VERSION "HNNBNNNYNNNNNNNNNNNNNNNNNNNNNNNNNNNNNNNNNN/4/%%%/4/'%**4NNN///"

NS_ :

BS_:

BU_: BAP_Tester Booster_AMP DSP_SKODA Gateway_PQ35 Gateway_PQ46 GSM_Pager Kompassmodul MDI Radio_2DIN Radio_Modul Radio_SKODA Rearview RNS_300_NF RNS_MFD2 RNS_midline SDARS_Tuner Sprachbedienung Standheizung Tastatur Telematik_Basis TV_hybrid UHV_High UHV_low UHV_NAR UHV_Premium UHV_UMTS

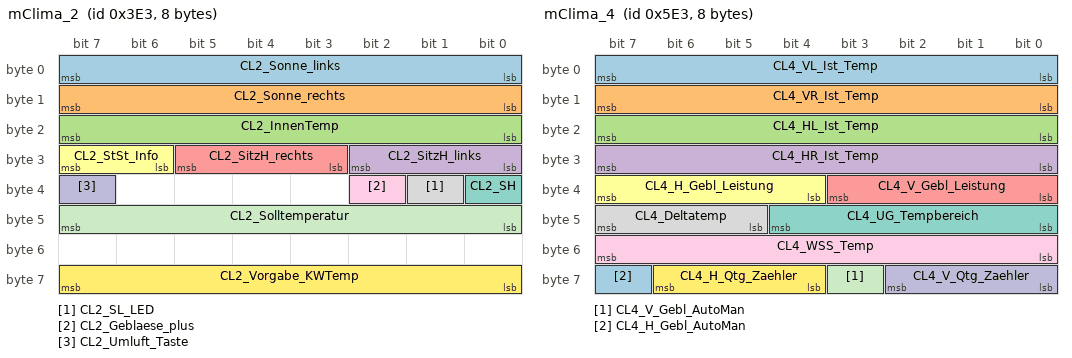
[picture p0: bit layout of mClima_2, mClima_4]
BO_ 995 mClima_2: 8 Gateway_PQ35
 SG_ CL2_Sonne_links : 0|8@1+ (4,0) [0|1016] "Unit_WattPerMeterSquar" Vector__XXX
 SG_ CL2_Sonne_rechts : 8|8@1+ (4,0) [0|1016] "Unit_WattPerMeterSquar" Vector__XXX
 SG_ CL2_InnenTemp : 16|8@1+ (0.5,-50) [-50|77] "Unit_DegreCelsi" Vector__XXX
 SG_ CL2_SitzH_links : 24|3@1+ (1,0) [0|7] "" Vector__XXX
 SG_ CL2_SitzH_rechts : 27|3@1+ (1,0) [0|7] "" Vector__XXX
 SG_ CL2_StSt_Info : 30|2@1+ (1,0) [0|3] "" Vector__XXX
 SG_ CL2_SH : 32|1@1+ (1,0) [0|1] ""  Standheizung,Telematik_Basis
 SG_ CL2_SL_LED : 33|1@1+ (1,0) [0|1] "" Vector__XXX
 SG_ CL2_Geblaese_plus : 34|1@1+ (1,0) [0|1] "" Vector__XXX
 SG_ CL2_Umluft_Taste : 39|1@1+ (1,0) [0|1] "" Vector__XXX
 SG_ CL2_Solltemperatur : 40|8@1+ (1,0) [0|255] "" Vector__XXX
 SG_ CL2_Vorgabe_KWTemp : 56|8@1+ (0.75,-48) [-48|142.5] "Unit_DegreCelsi" Vector__XXX

BO_ 1505 mClima_3: 7 Gateway_PQ35
 SG_ CL3_Umluft : 0|1@1+ (1,0) [0|1] ""  Radio_SKODA
 SG_ CL3_Restwaerme : 1|1@1+ (1,0) [0|1] "" Vector__XXX
 SG_ CL3_Mono : 2|1@1+ (1,0) [0|1] ""  Radio_SKODA
 SG_ CL3_Luftguetesensor : 3|1@1+ (1,0) [0|1] ""  Radio_SKODA
 SG_ CL3_Defrost : 4|1@1+ (1,0) [0|1] ""  Radio_SKODA
 SG_ CL3_Solarbelueftung : 5|1@1+ (1,0) [0|1] ""  Radio_SKODA
 SG_ CL3_Econ : 6|1@1+ (1,0) [0|1] ""  Radio_SKODA
 SG_ CL3_Klima_Hauptschalter : 7|1@1+ (1,0) [0|1] ""  Radio_SKODA
 SG_ CL3_KlimaOffFond : 8|1@1+ (1,0) [0|1] "" Vector__XXX
 SG_ CL3_Bedien_mgl : 9|1@1+ (1,0) [0|1] "" Vector__XXX
 SG_ CL3_nAkt_Uml_Fond : 10|1@1+ (1,0) [0|1] "" Vector__XXX
 SG_ CL3_nAkt_Umluft : 11|1@1+ (1,0) [0|1] "" Vector__XXX
 SG_ CL3_nAkt_Econ : 12|1@1+ (1,0) [0|1] "" Vector__XXX
 SG_ CL3_nAkt_AQS : 13|1@1+ (1,0) [0|1] "" Vector__XXX
 SG_ CL3_nAkt_Restwaerme : 14|1@1+ (1,0) [0|1] "" Vector__XXX
 SG_ CL3_Hzg_LF_Sens : 15|1@1+ (1,0) [0|1] "" Vector__XXX
 SG_ CL3_V_Qtg_Zaehler : 16|3@1+ (1,0) [0|7] "" Vector__XXX
 SG_ CL3_H_Qtg_Zaehler : 20|3@1+ (1,0) [0|7] "" Vector__XXX
 SG_ CL3_StandHzg : 23|1@1+ (1,0) [0|1] ""  Radio_SKODA
 SG_ CL3_Anstr_VL_Kopf : 24|1@1+ (1,0) [0|1] ""  Radio_SKODA
 SG_ CL3_Anstr_VL_Mann : 25|1@1+ (1,0) [0|1] ""  Radio_SKODA
 SG_ CL3_Anstr_VL_Fuss : 26|1@1+ (1,0) [0|1] ""  Radio_SKODA
 SG_ CL3_Anstr_VL_Automatik : 27|1@1+ (1,0) [0|1] ""  Radio_SKODA
 SG_ CL3_Anstr_VR_Kopf : 28|1@1+ (1,0) [0|1] "" Vector__XXX
 SG_ CL3_Anstr_VR_Mann : 29|1@1+ (1,0) [0|1] "" Vector__XXX
 SG_ CL3_Anstr_VR_Fuss : 30|1@1+ (1,0) [0|1] "" Vector__XXX
 SG_ CL3_Anstr_VR_Automatik : 31|1@1+ (1,0) [0|1] "" Vector__XXX
 SG_ CL3_Anstr_HL_Kopf : 32|1@1+ (1,0) [0|1] "" Vector__XXX
 SG_ CL3_Anstr_HL_Mann : 33|1@1+ (1,0) [0|1] "" Vector__XXX
 SG_ CL3_Anstr_HL_Fuss : 34|1@1+ (1,0) [0|1] "" Vector__XXX
 SG_ CL3_Anstr_HL_Automatik : 35|1@1+ (1,0) [0|1] "" Vector__XXX
 SG_ CL3_Anstr_HR_Kopf : 36|1@1+ (1,0) [0|1] "" Vector__XXX
 SG_ CL3_Anstr_HR_Mann : 37|1@1+ (1,0) [0|1] "" Vector__XXX
 SG_ CL3_Anstr_HR_Fuss : 38|1@1+ (1,0) [0|1] "" Vector__XXX
 SG_ CL3_Anstr_HR_Automatik : 39|1@1+ (1,0) [0|1] "" Vector__XXX
 SG_ CL3_FT_Defrost : 40|1@1+ (1,0) [0|1] "" Vector__XXX
 SG_ CL3_BT_Defrost : 41|1@1+ (1,0) [0|1] "" Vector__XXX
 SG_ CL3_StandLftg : 42|1@1+ (1,0) [0|1] "" Vector__XXX
 SG_ CL3_SH_ein_KDWunsch : 43|1@1+ (1,0) [0|1] "" Vector__XXX
 SG_ CL3_SH_Wasserpumpe : 44|1@1+ (1,0) [0|1] ""  Standheizung
 SG_ CL3_ein_Lenkrad_Hzg : 46|1@1+ (1,0) [0|1] "" Vector__XXX
 SG_ CL3_Gegendimmung : 48|8@1+ (1,0) [0|100] "Unit_PerCent" Vector__XXX

BO_ 1507 mClima_4: 8 Gateway_PQ35
 SG_ CL4_VL_Ist_Temp : 0|8@1+ (0.5,-50) [-50|77] "Unit_DegreCelsi"  Radio_SKODA
 SG_ CL4_VR_Ist_Temp : 8|8@1+ (0.5,-50) [-50|77] "Unit_DegreCelsi"  Radio_SKODA
 SG_ CL4_HL_Ist_Temp : 16|8@1+ (0.5,-50) [-50|77] "Unit_DegreCelsi" Vector__XXX
 SG_ CL4_HR_Ist_Temp : 24|8@1+ (0.5,-50) [-50|77] "Unit_DegreCelsi" Vector__XXX
 SG_ CL4_V_Gebl_Leistung : 32|4@1+ (10,0) [0|100] "Unit_PerCent"  Radio_SKODA
 SG_ CL4_H_Gebl_Leistung : 36|4@1+ (10,0) [0|100] "Unit_PerCent" Vector__XXX
 SG_ CL4_UG_Tempbereich : 40|5@1+ (1,0) [0|31] "Unit_DegreCelsi" Vector__XXX
 SG_ CL4_Deltatemp : 45|3@1+ (0.5,4) [4.5|7.5] "Unit_DegreCelsi" Vector__XXX
 SG_ CL4_WSS_Temp : 48|8@1+ (0.5,-50) [-50|77] "Unit_DegreCelsi" Vector__XXX
 SG_ CL4_V_Qtg_Zaehler : 56|3@1+ (1,0) [0|7] "" Vector__XXX
 SG_ CL4_V_Gebl_AutoMan : 59|1@1+ (1,0) [0|1] "" Vector__XXX
 SG_ CL4_H_Qtg_Zaehler : 60|3@1+ (1,0) [0|7] "" Vector__XXX
 SG_ CL4_H_Gebl_AutoMan : 63|1@1+ (1,0) [0|1] "" Vector__XXX

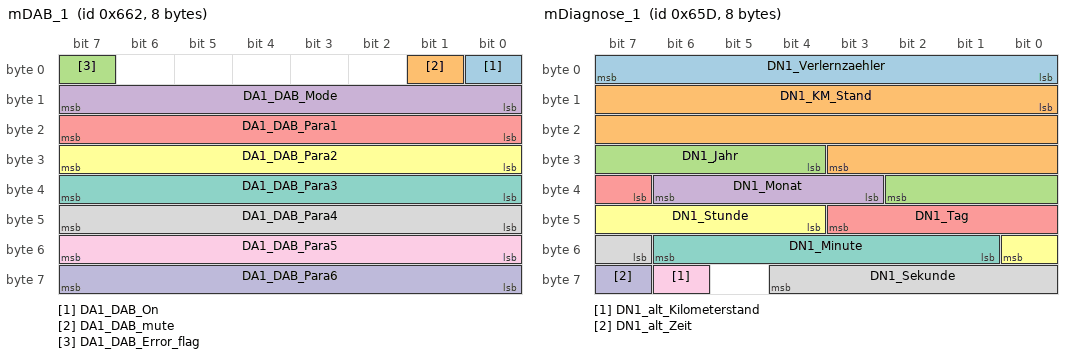
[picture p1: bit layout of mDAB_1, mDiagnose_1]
BO_ 1634 mDAB_1: 8 SDARS_Tuner
 SG_ DA1_DAB_On : 0|1@1+ (1,0) [0|1] ""  Radio_2DIN,Radio_SKODA
 SG_ DA1_DAB_mute : 1|1@1+ (1,0) [0|1] "" Vector__XXX
 SG_ DA1_DAB_Error_flag : 7|1@1+ (1,0) [0|1] ""  Gateway_PQ35,Gateway_PQ46
 SG_ DA1_DAB_Mode : 8|8@1+ (1,0) [0|255] ""  Radio_2DIN,Radio_SKODA
 SG_ DA1_DAB_Para1 : 16|8@1+ (1,0) [0|255] ""  Radio_2DIN,Radio_SKODA
 SG_ DA1_DAB_Para2 : 24|8@1+ (1,0) [0|255] ""  Radio_2DIN,Radio_SKODA
 SG_ DA1_DAB_Para3 : 32|8@1+ (1,0) [0|255] ""  Radio_2DIN,Radio_SKODA
 SG_ DA1_DAB_Para4 : 40|8@1+ (1,0) [0|255] ""  Radio_2DIN,Radio_SKODA
 SG_ DA1_DAB_Para5 : 48|8@1+ (1,0) [0|255] ""  Radio_2DIN,Radio_SKODA
 SG_ DA1_DAB_Para6 : 56|8@1+ (1,0) [0|255] ""  Radio_2DIN,Radio_SKODA

BO_ 1629 mDiagnose_1: 8 Gateway_PQ35
 SG_ DN1_Verlernzaehler : 0|8@1+ (1,0) [0|254] ""  Booster_AMP,DSP_SKODA,GSM_Pager,Kompassmodul,MDI,Radio_2DIN,Radio_Modul,Radio_SKODA,Rearview,RNS_300_NF,RNS_MFD2,RNS_midline,SDARS_Tuner,Sprachbedienung,Standheizung,Tastatur,Telematik_Basis,TV_hybrid,UHV_High,UHV_low,UHV_NAR,UHV_Premium,UHV_UMTS
 SG_ DN1_KM_Stand : 8|20@1+ (1,0) [0|1048575] "Unit_KiloMeter"  Booster_AMP,DSP_SKODA,GSM_Pager,Kompassmodul,MDI,Radio_Modul,Radio_SKODA,Rearview,RNS_300_NF,RNS_midline,SDARS_Tuner,Sprachbedienung,Standheizung,Tastatur,Telematik_Basis,TV_hybrid,UHV_High,UHV_low,UHV_NAR,UHV_Premium,UHV_UMTS
 SG_ DN1_Jahr : 28|7@1+ (1,2000) [2000|2127] "Unit_Year"  Booster_AMP,DSP_SKODA,GSM_Pager,Kompassmodul,MDI,Radio_2DIN,Radio_Modul,Radio_SKODA,Rearview,RNS_300_NF,RNS_midline,SDARS_Tuner,Sprachbedienung,Standheizung,Tastatur,Telematik_Basis,TV_hybrid,UHV_High,UHV_low,UHV_NAR,UHV_Premium,UHV_UMTS
 SG_ DN1_Monat : 35|4@1+ (1,0) [1|12] "Unit_Month"  Booster_AMP,DSP_SKODA,GSM_Pager,Kompassmodul,MDI,Radio_2DIN,Radio_Modul,Radio_SKODA,Rearview,RNS_300_NF,RNS_midline,SDARS_Tuner,Sprachbedienung,Standheizung,Tastatur,Telematik_Basis,TV_hybrid,UHV_High,UHV_low,UHV_NAR,UHV_Premium,UHV_UMTS
 SG_ DN1_Tag : 39|5@1+ (1,0) [0|31] "Unit_Day"  Booster_AMP,DSP_SKODA,GSM_Pager,Kompassmodul,MDI,Radio_2DIN,Radio_Modul,Radio_SKODA,Rearview,RNS_300_NF,RNS_midline,SDARS_Tuner,Sprachbedienung,Standheizung,Tastatur,Telematik_Basis,TV_hybrid,UHV_High,UHV_low,UHV_NAR,UHV_Premium,UHV_UMTS
 SG_ DN1_Stunde : 44|5@1+ (1,0) [0|23] "Unit_Hours"  Booster_AMP,DSP_SKODA,GSM_Pager,Kompassmodul,MDI,Radio_2DIN,Radio_Modul,Radio_SKODA,Rearview,RNS_300_NF,RNS_MFD2,RNS_midline,SDARS_Tuner,Sprachbedienung,Standheizung,Tastatur,Telematik_Basis,TV_hybrid,UHV_High,UHV_low,UHV_NAR,UHV_Premium,UHV_UMTS
 SG_ DN1_Minute : 49|6@1+ (1,0) [0|59] "Unit_Minut"  Booster_AMP,DSP_SKODA,GSM_Pager,Kompassmodul,MDI,Radio_2DIN,Radio_Modul,Radio_SKODA,Rearview,RNS_300_NF,RNS_MFD2,RNS_midline,SDARS_Tuner,Sprachbedienung,Standheizung,Tastatur,Telematik_Basis,TV_hybrid,UHV_High,UHV_low,UHV_NAR,UHV_Premium,UHV_UMTS
 SG_ DN1_Sekunde : 55|6@1+ (1,0) [0|59] "Unit_Secon"  Booster_AMP,DSP_SKODA,GSM_Pager,Kompassmodul,MDI,Radio_2DIN,Radio_Modul,Radio_SKODA,Rearview,RNS_300_NF,RNS_MFD2,RNS_midline,SDARS_Tuner,Sprachbedienung,Standheizung,Tastatur,Telematik_Basis,TV_hybrid,UHV_High,UHV_low,UHV_NAR,UHV_Premium,UHV_UMTS
 SG_ DN1_alt_Kilometerstand : 62|1@1+ (1,0) [0|1] ""  Booster_AMP,DSP_SKODA,GSM_Pager,Kompassmodul,MDI,Radio_Modul,Radio_SKODA,Rearview,RNS_300_NF,RNS_midline,SDARS_Tuner,Sprachbedienung,Standheizung,Tastatur,Telematik_Basis,TV_hybrid,UHV_High,UHV_low,UHV_NAR,UHV_Premium,UHV_UMTS
 SG_ DN1_alt_Zeit : 63|1@1+ (1,0) [0|1] ""  Booster_AMP,DSP_SKODA,GSM_Pager,Kompassmodul,MDI,Radio_2DIN,Radio_Modul,Radio_SKODA,Rearview,RNS_300_NF,RNS_MFD2,RNS_midline,SDARS_Tuner,Sprachbedienung,Standheizung,Tastatur,Telematik_Basis,TV_hybrid,UHV_High,UHV_low,UHV_NAR,UHV_Premium,UHV_UMTS

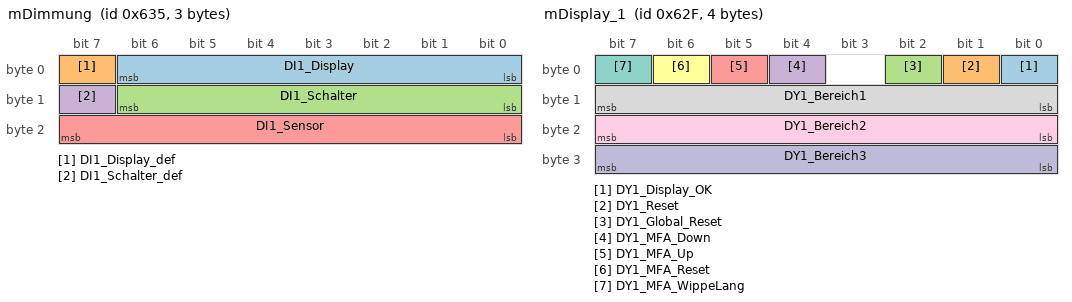
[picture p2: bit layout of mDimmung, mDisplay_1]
BO_ 1589 mDimmung: 3 Gateway_PQ35
 SG_ DI1_Display : 0|7@1+ (1,0) [0|100] "Unit_PerCent"  Radio_2DIN,Radio_Modul,Radio_SKODA,RNS_300_NF,RNS_MFD2,RNS_midline,Sprachbedienung,Tastatur,Telematik_Basis
 SG_ DI1_Display_def : 7|1@1+ (1,0) [0|1] ""  Radio_2DIN,Radio_Modul,Radio_SKODA,RNS_300_NF,RNS_MFD2,RNS_midline,Sprachbedienung,Tastatur,Telematik_Basis
 SG_ DI1_Schalter : 8|7@1+ (1,0) [0|100] "Unit_PerCent" Vector__XXX
 SG_ DI1_Schalter_def : 15|1@1+ (1,0) [0|1] "" Vector__XXX
 SG_ DI1_Sensor : 16|8@1+ (1,0) [0|253] ""  Radio_Modul,RNS_300_NF,RNS_midline

BO_ 1583 mDisplay_1: 4 Gateway_PQ35
 SG_ DY1_Display_OK : 0|1@1+ (1,0) [0|1] ""  Kompassmodul,Radio_2DIN,Radio_Modul,Radio_SKODA,RNS_300_NF,RNS_MFD2,RNS_midline,Standheizung,Telematik_Basis
 SG_ DY1_Reset : 1|1@1+ (1,0) [0|1] ""  Kompassmodul,Radio_2DIN,Radio_Modul,Radio_SKODA,RNS_300_NF,RNS_MFD2,RNS_midline,Standheizung,Telematik_Basis
 SG_ DY1_Global_Reset : 2|1@1+ (1,0) [0|1] ""  Standheizung
 SG_ DY1_MFA_Down : 4|1@1+ (1,0) [0|1] "" Vector__XXX
 SG_ DY1_MFA_Up : 5|1@1+ (1,0) [0|1] "" Vector__XXX
 SG_ DY1_MFA_Reset : 6|1@1+ (1,0) [0|1] "" Vector__XXX
 SG_ DY1_MFA_WippeLang : 7|1@1+ (1,0) [0|1] "" Vector__XXX
 SG_ DY1_Bereich1 : 8|8@1+ (1,0) [0|255] ""  Kompassmodul,Radio_2DIN,Radio_Modul,Radio_SKODA,RNS_300_NF,RNS_midline,Standheizung,Telematik_Basis
 SG_ DY1_Bereich2 : 16|8@1+ (1,0) [0|255] ""  Kompassmodul,Radio_2DIN,Radio_Modul,Radio_SKODA,RNS_300_NF,RNS_midline,Standheizung,Telematik_Basis
 SG_ DY1_Bereich3 : 24|8@1+ (1,0) [0|255] ""  Kompassmodul,Radio_2DIN,Radio_Modul,Radio_SKODA,RNS_300_NF,RNS_midline,Standheizung,Telematik_Basis

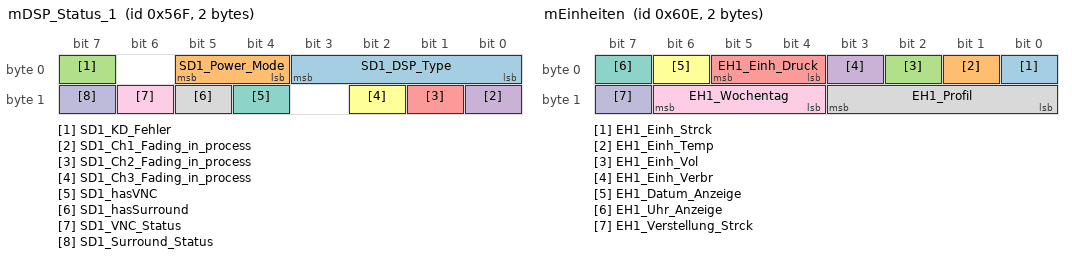
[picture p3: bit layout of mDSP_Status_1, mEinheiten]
BO_ 1391 mDSP_Status_1: 2 Booster_AMP
 SG_ SD1_DSP_Type : 0|4@1+ (1,0) [0|15] ""  Radio_Modul,Radio_SKODA
 SG_ SD1_Power_Mode : 4|2@1+ (1,0) [0|3] ""  Radio_Modul,Radio_SKODA,RNS_300_NF,RNS_midline
 SG_ SD1_KD_Fehler : 7|1@1+ (1,0) [0|1] ""  Gateway_PQ35,Gateway_PQ46
 SG_ SD1_Ch1_Fading_in_process : 8|1@1+ (1,0) [0|1] ""  Radio_SKODA
 SG_ SD1_Ch2_Fading_in_process : 9|1@1+ (1,0) [0|1] ""  Radio_SKODA
 SG_ SD1_Ch3_Fading_in_process : 10|1@1+ (1,0) [0|1] ""  Radio_SKODA
 SG_ SD1_hasVNC : 12|1@1+ (1,0) [0|1] "" Vector__XXX
 SG_ SD1_hasSurround : 13|1@1+ (1,0) [0|1] "" Vector__XXX
 SG_ SD1_VNC_Status : 14|1@1+ (1,0) [0|1] "" Vector__XXX
 SG_ SD1_Surround_Status : 15|1@1+ (1,0) [0|1] "" Vector__XXX

BO_ 1550 mEinheiten: 2 Gateway_PQ35
 SG_ EH1_Einh_Strck : 0|1@1+ (1,0) [0|1] ""  Radio_Modul,RNS_300_NF,RNS_midline
 SG_ EH1_Einh_Temp : 1|1@1+ (1,0) [0|1] ""  Radio_Modul,RNS_300_NF,RNS_midline,Standheizung
 SG_ EH1_Einh_Vol : 2|1@1+ (1,0) [0|1] ""  Radio_Modul,RNS_300_NF,RNS_midline
 SG_ EH1_Einh_Verbr : 3|1@1+ (1,0) [0|1] ""  Radio_Modul,RNS_300_NF,RNS_midline
 SG_ EH1_Einh_Druck : 4|2@1+ (1,0) [0|3] "" Vector__XXX
 SG_ EH1_Datum_Anzeige : 6|1@1+ (1,0) [0|1] ""  Radio_Modul,RNS_300_NF,RNS_midline
 SG_ EH1_Uhr_Anzeige : 7|1@1+ (1,0) [0|1] ""  Radio_2DIN,Radio_Modul,Radio_SKODA,RNS_300_NF,RNS_midline,Standheizung
 SG_ EH1_Profil : 8|4@1+ (1,0) [0|15] ""  Radio_Modul,RNS_300_NF,RNS_midline,Sprachbedienung,Standheizung,Telematik_Basis
 SG_ EH1_Wochentag : 12|3@1+ (1,0) [0|7] "" Vector__XXX
 SG_ EH1_Verstellung_Strck : 15|1@1+ (1,0) [0|1] ""  RNS_300_NF,RNS_midline

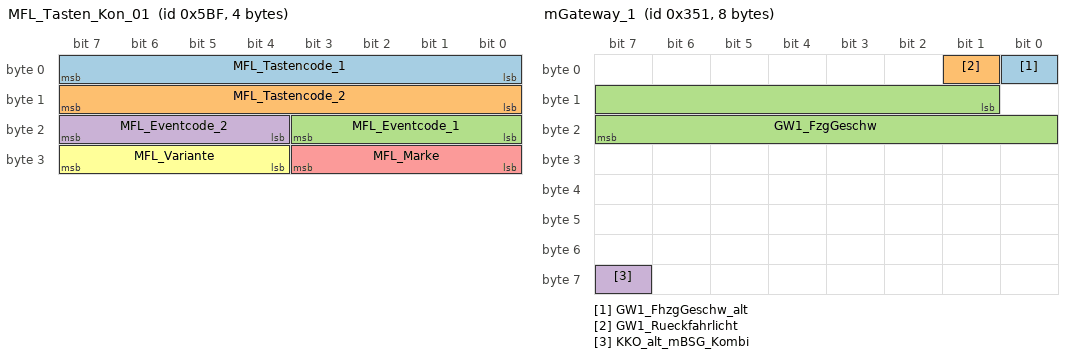
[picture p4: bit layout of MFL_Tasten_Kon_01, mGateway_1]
BO_ 1471 MFL_Tasten_Kon_01: 4 Gateway_PQ46
 SG_ MFL_Tastencode_1 : 0|8@1+ (1,0) [0|255] ""  UHV_NAR,UHV_UMTS
 SG_ MFL_Tastencode_2 : 8|8@1+ (1,0) [0|255] ""  UHV_NAR,UHV_UMTS
 SG_ MFL_Eventcode_1 : 16|4@1+ (1,0) [0|15] ""  UHV_NAR,UHV_UMTS
 SG_ MFL_Eventcode_2 : 20|4@1+ (1,0) [0|15] ""  UHV_NAR,UHV_UMTS
 SG_ MFL_Marke : 24|4@1+ (1,0) [0|15] ""  UHV_NAR,UHV_UMTS
 SG_ MFL_Variante : 28|4@1+ (1,0) [0|15] ""  UHV_NAR,UHV_UMTS

BO_ 1631 mFzg_Ident: 8 Gateway_PQ35
 SG_ FI1_MUX M : 0|2@1+ (1,0) [0|2] ""  RNS_300_NF,Telematik_Basis
 SG_ FI1_Geheimnis_1 m0 : 8|8@1+ (1,0) [0|255] "" Vector__XXX
 SG_ FI1_VIN_4 m1 : 8|8@1+ (1,0) [0|255] ""  RNS_300_NF,Telematik_Basis
 SG_ FI1_VIN_11 m2 : 8|8@1+ (1,0) [0|255] ""  RNS_300_NF,Telematik_Basis
 SG_ FI1_Geheimnis_2 m0 : 16|8@1+ (1,0) [0|255] "" Vector__XXX
 SG_ FI1_VIN_5 m1 : 16|8@1+ (1,0) [0|255] ""  RNS_300_NF,Telematik_Basis
 SG_ FI1_VIN_12 m2 : 16|8@1+ (1,0) [0|255] ""  RNS_300_NF,Telematik_Basis
 SG_ FI1_Geheimnis_3 m0 : 24|8@1+ (1,0) [0|255] "" Vector__XXX
 SG_ FI1_VIN_6 m1 : 24|8@1+ (1,0) [0|255] ""  RNS_300_NF,Telematik_Basis
 SG_ FI1_VIN_13 m2 : 24|8@1+ (1,0) [0|255] ""  RNS_300_NF,Telematik_Basis
 SG_ FI1_Geheimnis_4 m0 : 32|8@1+ (1,0) [0|255] "" Vector__XXX
 SG_ FI1_VIN_7 m1 : 32|8@1+ (1,0) [0|255] ""  RNS_300_NF,Telematik_Basis
 SG_ FI1_VIN_14 m2 : 32|8@1+ (1,0) [0|255] ""  RNS_300_NF,Telematik_Basis
 SG_ FI1_VIN_1 m0 : 40|8@1+ (1,0) [0|255] ""  RNS_300_NF,Telematik_Basis
 SG_ FI1_VIN_8 m1 : 40|8@1+ (1,0) [0|255] ""  RNS_300_NF,Telematik_Basis
 SG_ FI1_VIN_15 m2 : 40|8@1+ (1,0) [0|255] ""  RNS_300_NF,Telematik_Basis
 SG_ FI1_VIN_2 m0 : 48|8@1+ (1,0) [0|255] ""  RNS_300_NF,Telematik_Basis
 SG_ FI1_VIN_9 m1 : 48|8@1+ (1,0) [0|255] ""  RNS_300_NF,Telematik_Basis
 SG_ FI1_VIN_16 m2 : 48|8@1+ (1,0) [0|255] ""  RNS_300_NF,Telematik_Basis
 SG_ FI1_VIN_3 m0 : 56|8@1+ (1,0) [0|255] ""  RNS_300_NF,Telematik_Basis
 SG_ FI1_VIN_10 m1 : 56|8@1+ (1,0) [0|255] ""  RNS_300_NF,Telematik_Basis
 SG_ FI1_VIN_17 m2 : 56|8@1+ (1,0) [0|255] ""  RNS_300_NF,Telematik_Basis

BO_ 849 mGateway_1: 8 Gateway_PQ35
 SG_ GW1_FhzgGeschw_alt : 0|1@1+ (1,0) [0|1] "" Vector__XXX
 SG_ GW1_Rueckfahrlicht : 1|1@1+ (1,0) [0|1] "" Vector__XXX
 SG_ GW1_FzgGeschw : 9|15@1+ (0.01,0) [0|326.39] "Unit_KiloMeterPerHour" Vector__XXX
 SG_ KKO_alt_mBSG_Kombi : 63|1@1+ (1,0) [0|1] "" Vector__XXX

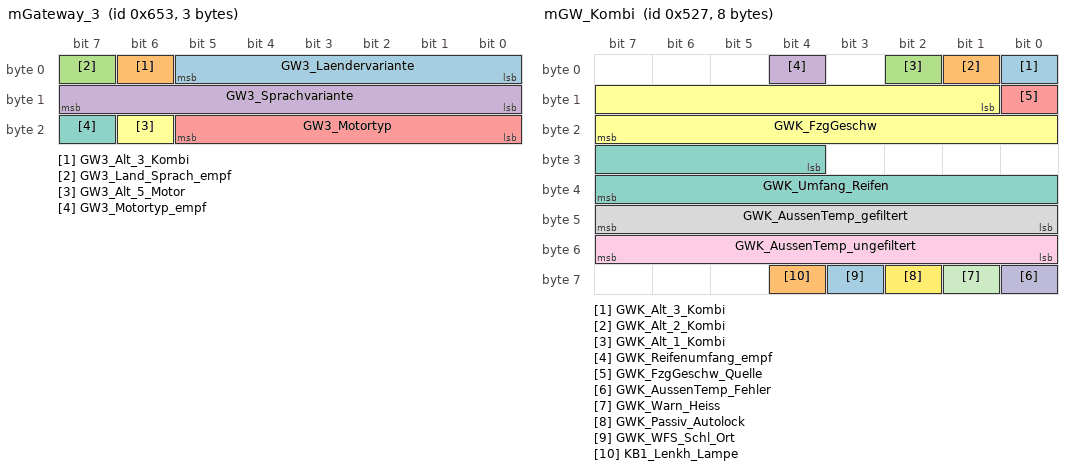
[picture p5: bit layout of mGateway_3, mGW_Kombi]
BO_ 1619 mGateway_3: 3 Gateway_PQ35
 SG_ GW3_Laendervariante : 0|6@1+ (1,0) [0|63] ""  Kompassmodul,Radio_Modul,Rearview,RNS_300_NF,RNS_MFD2,RNS_midline,Standheizung,Telematik_Basis,UHV_High,UHV_low,UHV_NAR,UHV_Premium,UHV_UMTS
 SG_ GW3_Alt_3_Kombi : 6|1@1+ (1,0) [0|1] ""  Rearview,UHV_High,UHV_low,UHV_NAR,UHV_Premium,UHV_UMTS
 SG_ GW3_Land_Sprach_empf : 7|1@1+ (1,0) [0|1] ""  Radio_Modul,RNS_300_NF,RNS_MFD2,RNS_midline,Telematik_Basis,UHV_High,UHV_low,UHV_NAR,UHV_Premium,UHV_UMTS
 SG_ GW3_Sprachvariante : 8|8@1+ (1,0) [0|255] ""  Kompassmodul,Radio_Modul,Rearview,RNS_300_NF,RNS_MFD2,RNS_midline,Standheizung,Telematik_Basis,UHV_High,UHV_low,UHV_NAR,UHV_Premium,UHV_UMTS
 SG_ GW3_Motortyp : 16|6@1+ (1,0) [0|63] ""  Standheizung
 SG_ GW3_Alt_5_Motor : 22|1@1+ (1,0) [0|1] ""  Standheizung
 SG_ GW3_Motortyp_empf : 23|1@1+ (1,0) [0|1] "" Vector__XXX

BO_ 1487 mGSM_Pager_1: 1 GSM_Pager
 SG_ GS1_Error_flag : 7|1@1+ (1,0) [0|1] ""  Gateway_PQ35,Gateway_PQ46

BO_ 857 mGW_Bremse_Getriebe: 8 Gateway_PQ35
 SG_ GWB_Alt_FzgGeschw : 0|1@1+ (1,0) [0|1] ""  Booster_AMP,DSP_SKODA,Kompassmodul,Radio_2DIN,Radio_Modul,Radio_SKODA,Rearview,RNS_300_NF,RNS_MFD2,RNS_midline,Standheizung,Telematik_Basis,UHV_low,UHV_Premium
 SG_ GWB_Alt_2_Bremse : 1|1@1+ (1,0) [0|1] ""  Radio_Modul,RNS_300_NF,RNS_MFD2,RNS_midline,Telematik_Basis
 SG_ GWB_Alt_1_Bremse : 2|1@1+ (1,0) [0|1] "" Vector__XXX
 SG_ GWB_Alt_1_Getriebe : 3|1@1+ (1,0) [0|1] "" Vector__XXX
 SG_ GWB_Alt_2_Getriebe : 4|1@1+ (1,0) [0|1] "" Vector__XXX
 SG_ GWB_Alt_1_EPB : 5|1@1+ (1,0) [0|1] "" Vector__XXX
 SG_ GWB_Alt_5_Bremse : 6|1@1+ (1,0) [0|1] "" Vector__XXX
 SG_ GWB_Alt_AWV_X : 7|1@1+ (1,0) [0|1] "" Vector__XXX
 SG_ GWB_FzgGeschw_Quelle : 8|1@1+ (1,0) [0|1] ""  Booster_AMP,DSP_SKODA,Kompassmodul,Radio_2DIN,Radio_Modul,Radio_SKODA,Rearview,RNS_300_NF,RNS_MFD2,RNS_midline,Standheizung,Telematik_Basis,UHV_low,UHV_Premium
 SG_ GWB_FzgGeschw : 9|15@1+ (0.01,0) [0|326.39] "Unit_KiloMeterPerHour"  Booster_AMP,DSP_SKODA,Kompassmodul,Radio_2DIN,Radio_Modul,Radio_SKODA,Rearview,RNS_300_NF,RNS_MFD2,RNS_midline,Standheizung,Telematik_Basis,UHV_low,UHV_Premium
 SG_ GWB_Wegimpulse : 24|11@1+ (1,0) [0|2047] ""  Radio_Modul,RNS_300_NF,RNS_MFD2,RNS_midline,Telematik_Basis
 SG_ GWB_Wegimpuls_Status : 35|1@1+ (1,0) [0|1] ""  Radio_Modul,RNS_300_NF,RNS_MFD2,RNS_midline,Telematik_Basis
 SG_ GWB_Wegimpulse_Fehler : 39|1@1+ (1,0) [0|1] ""  Radio_Modul,RNS_300_NF,RNS_MFD2,RNS_midline,Telematik_Basis
 SG_ GWB_Impulszahl : 40|6@1+ (1,0) [0|63] ""  Radio_Modul,RNS_300_NF,RNS_MFD2,RNS_midline,Telematik_Basis
 SG_ GWB_Alt_PLA_Status : 46|1@1+ (1,0) [0|1] "" Vector__XXX
 SG_ PLS_Bremsleuchte : 47|1@1+ (1,0) [0|1] "" Vector__XXX
 SG_ GWB_TSP_aktiv : 48|1@1+ (1,0) [0|1] "" Vector__XXX
 SG_ GWB_Notbremsung : 49|1@1+ (1,0) [0|1] "" Vector__XXX
 SG_ GWB_ABS_Bremsung : 50|1@1+ (1,0) [0|1] "" Vector__XXX
 SG_ GWB_EPB_Status : 51|1@1+ (1,0) [0|1] "" Vector__XXX
 SG_ GWB_EPB_Bremslicht : 52|1@1+ (1,0) [0|1] "" Vector__XXX
 SG_ GWB_Schlechtweg : 53|1@1+ (1,0) [0|1] "" Vector__XXX
 SG_ GWB_Schlechtweg_Fehler : 54|1@1+ (1,0) [0|1] "" Vector__XXX
 SG_ GWB_Geschw_Ersatz : 55|1@1+ (1,0) [0|1] ""  Booster_AMP,DSP_SKODA,Kompassmodul,Radio_2DIN,Radio_Modul,Radio_SKODA,RNS_300_NF,RNS_MFD2,RNS_midline,Telematik_Basis
 SG_ GWB_Schaltvorgang : 56|1@1+ (1,0) [0|1] "" Vector__XXX
 SG_ ANB_Teilbremsung_Freigabe : 57|1@1+ (1,0) [0|1] "" Vector__XXX
 SG_ GWB_ESP_Eingriff : 58|1@1+ (1,0) [0|1] "" Vector__XXX
 SG_ GWB_Shift_Lock : 59|1@1+ (1,0) [0|1] "" Vector__XXX
 SG_ GWB_Info_Waehlhebel : 60|4@1+ (1,0) [0|15] "" Vector__XXX

BO_ 1315 mGW_KOM_INF: 8 Gateway_PQ35
 SG_ GWI_alt_ZKE_4 : 0|1@1+ (1,0) [0|1] ""  GSM_Pager,Radio_Modul
 SG_ GWI_alt_ZKE_3 : 1|1@1+ (1,0) [0|1] ""  GSM_Pager
 SG_ GWI_alt_Kombi_1 : 2|1@1+ (1,0) [0|1] "" Vector__XXX
 SG_ GWI_res3 : 3|1@1+ (1,0) [0|1] "" Vector__XXX
 SG_ GWI_res4 : 4|1@1+ (1,0) [0|1] "" Vector__XXX
 SG_ GWI_res5 : 5|1@1+ (1,0) [0|1] "" Vector__XXX
 SG_ GWI_res6 : 6|1@1+ (1,0) [0|1] "" Vector__XXX
 SG_ GWI_res7 : 7|1@1+ (1,0) [0|1] "" Vector__XXX
 SG_ GWI_Status_Verdeck : 8|1@1+ (1,0) [0|1] ""  Radio_Modul
 SG_ GWI_ZKE4_Zusatzfkt : 15|1@1+ (1,0) [0|1] ""  GSM_Pager
 SG_ GWI_Blk_ZV_auf : 16|1@1+ (1,0) [0|1] ""  GSM_Pager
 SG_ GWI_Blk_ZV_zu : 17|1@1+ (1,0) [0|1] ""  GSM_Pager
 SG_ GWI_Blk_DW_ein : 18|1@1+ (1,0) [0|1] ""  GSM_Pager
 SG_ GWI_DWA_Alarm : 19|1@1+ (1,0) [0|1] ""  GSM_Pager
 SG_ GWI_verriegelt_int : 20|1@1+ (1,0) [0|1] ""  GSM_Pager
 SG_ GWI_verriegelt_ext : 21|1@1+ (1,0) [0|1] ""  GSM_Pager
 SG_ GWI_gesaeft_ext : 22|1@1+ (1,0) [0|1] ""  GSM_Pager
 SG_ KB1_angez_kmh : 32|10@1+ (0.32,0) [0|325.76] "Unit_KiloMeterPerHour" Vector__XXX

BO_ 1319 mGW_Kombi: 8 Gateway_PQ35
 SG_ GWK_Alt_3_Kombi : 0|1@1+ (1,0) [0|1] ""  Radio_Modul,RNS_300_NF,RNS_MFD2,RNS_midline
 SG_ GWK_Alt_2_Kombi : 1|1@1+ (1,0) [0|1] ""  Radio_Modul,Standheizung,Telematik_Basis
 SG_ GWK_Alt_1_Kombi : 2|1@1+ (1,0) [0|1] ""  DSP_SKODA,Kompassmodul,Radio_2DIN,Radio_Modul,Radio_SKODA,RNS_300_NF,RNS_midline,Standheizung,Telematik_Basis,UHV_low,UHV_NAR,UHV_Premium,UHV_UMTS
 SG_ GWK_Reifenumfang_empf : 4|1@1+ (1,0) [0|1] ""  RNS_300_NF,RNS_MFD2,RNS_midline
 SG_ GWK_FzgGeschw_Quelle : 8|1@1+ (1,0) [0|1] ""  DSP_SKODA,Kompassmodul,Radio_2DIN,Radio_Modul,Radio_SKODA,RNS_300_NF,RNS_midline,Standheizung,Telematik_Basis,UHV_low,UHV_NAR,UHV_Premium,UHV_UMTS
 SG_ GWK_FzgGeschw : 9|15@1+ (0.01,0) [0|326] "Unit_KiloMeterPerHour"  DSP_SKODA,Kompassmodul,Radio_2DIN,Radio_Modul,Radio_SKODA,RNS_300_NF,RNS_midline,Standheizung,Telematik_Basis,UHV_low,UHV_NAR,UHV_Premium,UHV_UMTS
 SG_ GWK_Umfang_Reifen : 28|12@1+ (1,0) [0|4095] ""  RNS_300_NF,RNS_MFD2,RNS_midline
 SG_ GWK_AussenTemp_gefiltert : 40|8@1+ (0.5,-50) [-50|77] "Unit_DegreCelsi"  Radio_Modul,Standheizung,Telematik_Basis
 SG_ GWK_AussenTemp_ungefiltert : 48|8@1+ (0.5,-50) [-50|77] "Unit_DegreCelsi"  Standheizung,Telematik_Basis
 SG_ GWK_AussenTemp_Fehler : 56|1@1+ (1,0) [0|1] ""  Standheizung,Telematik_Basis
 SG_ GWK_Warn_Heiss : 57|1@1+ (1,0) [0|1] "" Vector__XXX
 SG_ GWK_Passiv_Autolock : 58|1@1+ (1,0) [0|1] "" Vector__XXX
 SG_ GWK_WFS_Schl_Ort : 59|1@1+ (1,0) [0|1] "" Vector__XXX
 SG_ KB1_Lenkh_Lampe : 60|1@1+ (1,0) [0|1] "" Vector__XXX

BO_ 859 mGW_Motor: 8 Gateway_PQ35
 SG_ GWM_Alt_1_Motor : 0|1@1+ (1,0) [0|1] ""  Booster_AMP,DSP_SKODA,Radio_2DIN,Radio_Modul,Radio_SKODA,RNS_300_NF,RNS_midline,Standheizung,Telematik_Basis
 SG_ GWM_Alt_2_Motor : 1|1@1+ (1,0) [0|1] ""  Standheizung
 SG_ GWM_Alt_5_Motor : 2|1@1+ (1,0) [0|1] "" Vector__XXX
 SG_ GWM_Alt_Motor_Bremse : 3|1@1+ (1,0) [0|1] "" Vector__XXX
 SG_ GWM_RME_Gehalt : 5|3@1+ (12.5,0) [0|75] "Unit_PerCent"  Standheizung
 SG_ GWM_Motordrehzahl : 8|16@1+ (0.25,0) [0|16256] "Unit_MinutInver"  Booster_AMP,DSP_SKODA,Radio_2DIN,Radio_Modul,Radio_SKODA,RNS_300_NF,RNS_midline,Standheizung,Telematik_Basis
 SG_ GWM_KuehlmittelTemp : 24|8@1+ (0.75,-48) [-47.25|142.5] "Unit_DegreCelsi"  Standheizung
 SG_ GWM_Bremslicht_Schalter : 32|1@1+ (1,0) [0|1] "" Vector__XXX
 SG_ GWM_Bremstest_Schalter : 33|1@1+ (1,0) [0|1] "" Vector__XXX
 SG_ GWM_Fehl_KmittelTemp : 34|1@1+ (1,0) [0|1] "" Vector__XXX
 SG_ GWM_Kuppl_Schalter : 35|1@1+ (1,0) [0|1] "" Vector__XXX
 SG_ GWM_Heissl_Vorwarn : 36|1@1+ (1,0) [0|1] "" Vector__XXX
 SG_ GWM_Klimaabschaltung : 37|1@1+ (1,0) [0|1] "" Vector__XXX
 SG_ GWM_Kennfeldkuehlung : 38|1@1+ (1,0) [0|1] "" Vector__XXX
 SG_ GWM_Komp_Leist_red : 39|1@1+ (1,0) [0|1] "" Vector__XXX
 SG_ GWM_KLuefter : 40|8@1+ (0.4,0) [0|101.6] "Unit_PerCent" Vector__XXX
 SG_ GWM_Anl_Freigabe : 48|1@1+ (1,0) [0|1] "" Vector__XXX
 SG_ GWM_Anl_Ausspuren : 49|1@1+ (1,0) [0|1] "" Vector__XXX
 SG_ GWM_Interlock : 50|1@1+ (1,0) [0|1] "" Vector__XXX
 SG_ GWM_TypStartSteu : 51|1@1+ (1,0) [0|1] "" Vector__XXX
 SG_ GWM_Freig_Bremsanforderung : 52|1@1+ (1,0) [0|1] "" Vector__XXX
 SG_ GWM_Vorgluehen : 53|1@1+ (1,0) [0|1] "" Vector__XXX
 SG_ GWM_GRA_Status : 54|2@1+ (1,0) [0|3] "" Vector__XXX
 SG_ GWM_KVerbrauch : 56|7@1+ (256,0) [0|32512] "Unit_MicroLiter" Vector__XXX
 SG_ GWM_Ueberl_KV : 63|1@1+ (1,0) [0|1] "" Vector__XXX

BO_ 1367 mKD_Error: 8 Gateway_PQ35
 SG_ EKD_Motor_A : 0|1@1+ (1,0) [0|1] ""  Telematik_Basis
 SG_ EKD_Getriebe_A : 1|1@1+ (1,0) [0|1] ""  Telematik_Basis
 SG_ EKD_Bremse_A : 2|1@1+ (1,0) [0|1] ""  Telematik_Basis
 SG_ EKD_Kombi_A : 3|1@1+ (1,0) [0|1] ""  Telematik_Basis
 SG_ EKD_LSM_A : 4|1@1+ (1,0) [0|1] ""  Telematik_Basis
 SG_ EKD_Airbag_A : 5|1@1+ (1,0) [0|1] ""  Telematik_Basis
 SG_ EKD_Lenkhilfe_A : 6|1@1+ (1,0) [0|1] ""  Telematik_Basis
 SG_ EKD_dyn_LWR_A : 7|1@1+ (1,0) [0|1] ""  Telematik_Basis
 SG_ EKD_Niveau_A : 8|1@1+ (1,0) [0|1] ""  Telematik_Basis
 SG_ EKD_Allrad_A : 9|1@1+ (1,0) [0|1] ""  Telematik_Basis
 SG_ EKD_ADR_Sensor_A : 10|1@1+ (1,0) [0|1] ""  Telematik_Basis
 SG_ EKD_ADR_getrennt : 11|1@1+ (1,0) [0|1] ""  Telematik_Basis
 SG_ EKD_Parkbremse_A : 12|1@1+ (1,0) [0|1] ""  Telematik_Basis
 SG_ EKD_EZS_A : 13|1@1+ (1,0) [0|1] ""  Telematik_Basis
 SG_ EKD_Daempfer_A : 14|1@1+ (1,0) [0|1] ""  Telematik_Basis
 SG_ EKD_Quersperre : 15|1@1+ (1,0) [0|1] "" Vector__XXX
 SG_ EKD_Motor_Slave_A : 16|1@1+ (1,0) [0|1] "" Vector__XXX
 SG_ EKD_SWA_A : 17|1@1+ (1,0) [0|1] "" Vector__XXX
 SG_ EKD_LDW_A : 18|1@1+ (1,0) [0|1] "" Vector__XXX
 SG_ EKD_RKA_Plus_A : 19|1@1+ (1,0) [0|1] "" Vector__XXX
 SG_ EKD_PLA_A : 20|1@1+ (1,0) [0|1] ""  Telematik_Basis
 SG_ EKD_WFS_KBI : 21|1@1+ (1,0) [0|1] ""  Telematik_Basis
 SG_ EKD_Kombi_KBI : 22|1@1+ (1,0) [0|1] ""  Telematik_Basis
 SG_ EKD_BSG_K : 24|1@1+ (1,0) [0|1] ""  Telematik_Basis
 SG_ EKD_KSG_K : 25|1@1+ (1,0) [0|1] ""  Telematik_Basis
 SG_ EKD_TSG_FT_K : 26|1@1+ (1,0) [0|1] ""  Telematik_Basis
 SG_ EKD_TSG_BT_K : 27|1@1+ (1,0) [0|1] ""  Telematik_Basis
 SG_ EKD_TSG_HL_K : 28|1@1+ (1,0) [0|1] ""  Telematik_Basis
 SG_ EKD_TSG_HR_K : 29|1@1+ (1,0) [0|1] ""  Telematik_Basis
 SG_ EKD_Memory_K : 30|1@1+ (1,0) [0|1] ""  Telematik_Basis
 SG_ EKD_Dachmodul_K : 31|1@1+ (1,0) [0|1] ""  Telematik_Basis
 SG_ EKD_Zentralelektrik_II_K : 32|1@1+ (1,0) [0|1] ""  Telematik_Basis
 SG_ EKD_RDK_K : 33|1@1+ (1,0) [0|1] ""  Telematik_Basis
 SG_ EKD_SMLS_K : 34|1@1+ (1,0) [0|1] ""  Telematik_Basis
 SG_ EKD_Gateway_K : 35|1@1+ (1,0) [0|1] ""  Telematik_Basis
 SG_ EKD_Clima_K : 36|1@1+ (1,0) [0|1] ""  Telematik_Basis
 SG_ EKD_APS_K : 37|1@1+ (1,0) [0|1] ""  Telematik_Basis
 SG_ EKD_PTC_Heizung_K : 38|1@1+ (1,0) [0|1] ""  Telematik_Basis
 SG_ EKD_Standhzg_K : 39|1@1+ (1,0) [0|1] ""  Telematik_Basis
 SG_ EKD_VSG_K : 40|1@1+ (1,0) [0|1] ""  Telematik_Basis
 SG_ EKD_RSE_I : 41|1@1+ (1,0) [0|1] ""  Telematik_Basis
 SG_ EKD_Wischer_K : 42|1@1+ (1,0) [0|1] ""  Telematik_Basis
 SG_ EKD_MDI_I : 43|1@1+ (1,0) [0|1] ""  Telematik_Basis
 SG_ EKD_AAG_K : 44|1@1+ (1,0) [0|1] ""  Telematik_Basis
 SG_ EKD_Mem_BF_K : 45|1@1+ (1,0) [0|1] ""  Telematik_Basis
 SG_ EKD_Easy_Entry_VF : 46|1@1+ (1,0) [0|1] ""  Telematik_Basis
 SG_ EKD_Easy_Entry_VB : 47|1@1+ (1,0) [0|1] "" Vector__XXX
 SG_ EKD_Heckdeckel_K : 48|1@1+ (1,0) [0|1] ""  Telematik_Basis
 SG_ EKD_Rearview_I : 49|1@1+ (1,0) [0|1] "" Vector__XXX
 SG_ EKD_Sonderfahrzeug_SG_K : 50|1@1+ (1,0) [0|1] ""  Telematik_Basis
 SG_ EKD_Tastenmodul_I : 51|1@1+ (1,0) [0|1] ""  Telematik_Basis
 SG_ EKD_Kompass_I : 52|1@1+ (1,0) [0|1] ""  Telematik_Basis
 SG_ EKD_WFS_K : 53|1@1+ (1,0) [0|1] ""  Telematik_Basis
 SG_ EKD_GSM_Pager_I : 54|1@1+ (1,0) [0|1] ""  Telematik_Basis
 SG_ EKD_DSP_I : 56|1@1+ (1,0) [0|1] ""  Telematik_Basis
 SG_ EKD_DAB_I : 57|1@1+ (1,0) [0|1] ""  Telematik_Basis
 SG_ EKD_Telematik_I : 58|1@1+ (1,0) [0|1] ""  Telematik_Basis
 SG_ EKD_Navigation_I : 59|1@1+ (1,0) [0|1] ""  Telematik_Basis
 SG_ EKD_TV_Tuner_I : 60|1@1+ (1,0) [0|1] ""  Telematik_Basis
 SG_ EKD_Neigungsmodul : 61|1@1+ (1,0) [0|1] ""  Telematik_Basis
 SG_ EKD_Radio_I : 62|1@1+ (1,0) [0|1] ""  Telematik_Basis
 SG_ EKD_Telefon_I : 63|1@1+ (1,0) [0|1] ""  Telematik_Basis

BO_ 1569 mKombi_K1: 7 Gateway_PQ35
 SG_ KO1_Tankstop : 0|1@1+ (1,0) [0|1] ""  RNS_midline,Standheizung,UHV_High
 SG_ KO1_Tankwarnlampe : 1|1@1+ (1,0) [0|1] ""  RNS_midline,Standheizung
 SG_ KO1_WaschWasser : 2|1@1+ (1,0) [0|1] "" Vector__XXX
 SG_ KO1_MH_Kontakt : 3|1@1+ (1,0) [0|1] "" Vector__XXX
 SG_ KO1_FT_geoeffnet : 4|1@1+ (1,0) [0|1] "" Vector__XXX
 SG_ KO1_Handbremse : 5|1@1+ (1,0) [0|1] "" Vector__XXX
 SG_ KO1_AFL : 6|1@1+ (1,0) [0|1] "" Vector__XXX
 SG_ KO1_Klemme_L : 7|1@1+ (1,0) [0|1] "" Vector__XXX
 SG_ KO1_Standzeit : 8|15@1+ (4,0) [0|131068] "Unit_Secon"  Radio_2DIN,Radio_Modul,Radio_SKODA,RNS_MFD2,RNS_midline
 SG_ KO1_Standzeit_Fehler : 23|1@1+ (1,0) [0|1] ""  Radio_2DIN,Radio_Modul,Radio_SKODA,RNS_MFD2,RNS_midline
 SG_ KO1_Tankinhalt : 24|7@1+ (1,0) [0|126] "Unit_Liter"  Standheizung
 SG_ KO1_Tankwarnung : 31|1@1+ (1,0) [0|1] ""  RNS_midline
 SG_ KO1_WFS_Schluessel : 32|4@1+ (1,0) [0|15] "" Vector__XXX
 SG_ KO1_KD_Fehler_WFS : 36|1@1+ (1,0) [0|1] "" Vector__XXX
 SG_ KO1_Fernlicht : 37|1@1+ (1,0) [0|1] "" Vector__XXX
 SG_ KO1_Freigabe_Zuheizer : 38|1@1+ (1,0) [0|1] "" Vector__XXX
 SG_ KO1_MFA_vorhanden : 39|1@1+ (1,0) [0|1] "" Vector__XXX
 SG_ KO1_Bel_Displ : 40|7@1+ (1,0) [0|100] "Unit_PerCent" Vector__XXX
 SG_ KO1_Sta_Displ : 47|1@1+ (1,0) [0|1] "" Vector__XXX
 SG_ KO1_Lichtsensor : 48|8@1+ (1,0) [0|253] "" Vector__XXX

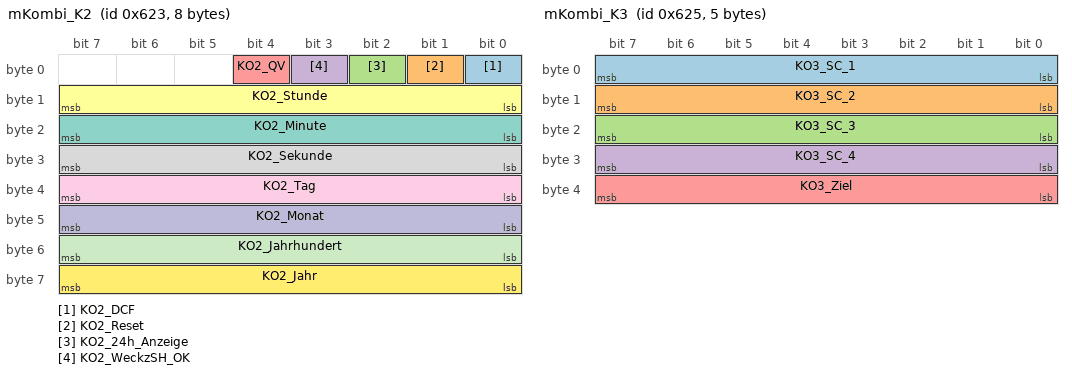
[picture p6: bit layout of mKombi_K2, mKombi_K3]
BO_ 1571 mKombi_K2: 8 Gateway_PQ35
 SG_ KO2_DCF : 0|1@1+ (1,0) [0|1] "" Vector__XXX
 SG_ KO2_Reset : 1|1@1+ (1,0) [0|1] "" Vector__XXX
 SG_ KO2_24h_Anzeige : 2|1@1+ (1,0) [0|1] "" Vector__XXX
 SG_ KO2_WeckzSH_OK : 3|1@1+ (1,0) [0|1] "" Vector__XXX
 SG_ KO2_QV : 4|1@1+ (1,0) [0|1] "" Vector__XXX
 SG_ KO2_Stunde : 8|8@1+ (1,0) [0|255] "" Vector__XXX
 SG_ KO2_Minute : 16|8@1+ (1,0) [0|255] "" Vector__XXX
 SG_ KO2_Sekunde : 24|8@1+ (1,0) [0|255] "" Vector__XXX
 SG_ KO2_Tag : 32|8@1+ (1,0) [0|255] "" Vector__XXX
 SG_ KO2_Monat : 40|8@1+ (1,0) [0|255] "" Vector__XXX
 SG_ KO2_Jahrhundert : 48|8@1+ (1,0) [0|255] "" Vector__XXX
 SG_ KO2_Jahr : 56|8@1+ (1,0) [0|255] "" Vector__XXX

BO_ 1573 mKombi_K3: 5 Gateway_PQ35
 SG_ KO3_SC_1 : 0|8@1+ (1,0) [0|255] ""  Radio_2DIN,Radio_Modul,Radio_SKODA,RNS_300_NF,RNS_MFD2,RNS_midline
 SG_ KO3_SC_2 : 8|8@1+ (1,0) [0|255] ""  Radio_2DIN,Radio_Modul,Radio_SKODA,RNS_300_NF,RNS_MFD2,RNS_midline
 SG_ KO3_SC_3 : 16|8@1+ (1,0) [0|255] ""  Radio_2DIN,Radio_Modul,Radio_SKODA,RNS_300_NF,RNS_MFD2,RNS_midline
 SG_ KO3_SC_4 : 24|8@1+ (1,0) [0|255] ""  Radio_2DIN,Radio_Modul,Radio_SKODA,RNS_300_NF,RNS_MFD2,RNS_midline
 SG_ KO3_Ziel : 32|8@1+ (1,0) [0|255] ""  Radio_2DIN,Radio_Modul,Radio_SKODA,RNS_300_NF,RNS_MFD2,RNS_midline

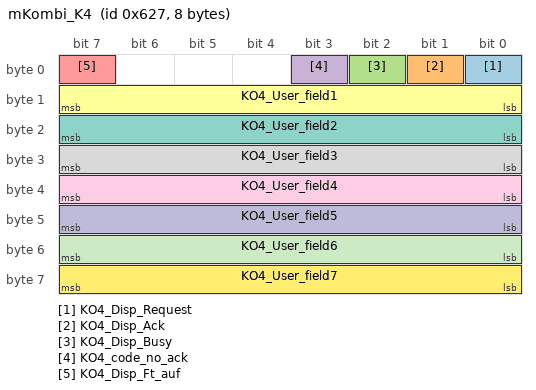
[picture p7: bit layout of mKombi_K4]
BO_ 1575 mKombi_K4: 8 Gateway_PQ35
 SG_ KO4_Disp_Request : 0|1@1+ (1,0) [0|1] "" Vector__XXX
 SG_ KO4_Disp_Ack : 1|1@1+ (1,0) [0|1] "" Vector__XXX
 SG_ KO4_Disp_Busy : 2|1@1+ (1,0) [0|1] "" Vector__XXX
 SG_ KO4_code_no_ack : 3|1@1+ (1,0) [0|1] "" Vector__XXX
 SG_ KO4_Disp_Ft_auf : 7|1@1+ (1,0) [0|1] "" Vector__XXX
 SG_ KO4_User_field1 : 8|8@1+ (1,0) [0|255] "" Vector__XXX
 SG_ KO4_User_field2 : 16|8@1+ (1,0) [0|255] "" Vector__XXX
 SG_ KO4_User_field3 : 24|8@1+ (1,0) [0|255] "" Vector__XXX
 SG_ KO4_User_field4 : 32|8@1+ (1,0) [0|255] "" Vector__XXX
 SG_ KO4_User_field5 : 40|8@1+ (1,0) [0|255] "" Vector__XXX
 SG_ KO4_User_field6 : 48|8@1+ (1,0) [0|255] "" Vector__XXX
 SG_ KO4_User_field7 : 56|8@1+ (1,0) [0|255] "" Vector__XXX

BO_ 1479 mKompass: 4 Kompassmodul
 SG_ KOM_Norden : 0|1@1+ (1,0) [0|1] "" Vector__XXX
 SG_ KOM_NordOst : 1|1@1+ (1,0) [0|1] "" Vector__XXX
 SG_ KOM_Ost : 2|1@1+ (1,0) [0|1] "" Vector__XXX
 SG_ KOM_SuedOst : 3|1@1+ (1,0) [0|1] "" Vector__XXX
 SG_ KOM_Sued : 4|1@1+ (1,0) [0|1] "" Vector__XXX
 SG_ KOM_SuedWest : 5|1@1+ (1,0) [0|1] "" Vector__XXX
 SG_ KOM_West : 6|1@1+ (1,0) [0|1] "" Vector__XXX
 SG_ KOM_NordWest : 7|1@1+ (1,0) [0|1] "" Vector__XXX
 SG_ KOM_Zone : 8|4@1+ (1,0) [0|15] "" Vector__XXX
 SG_ KOM_Calibriert : 12|1@1+ (1,0) [0|1] "" Vector__XXX
 SG_ KOM_CALaktiv : 13|1@1+ (1,0) [0|1] "" Vector__XXX
 SG_ KOM_Grad : 16|8@1+ (1,0) [0|255] "" Vector__XXX
 SG_ KOM_Stoerfeld : 24|1@1+ (1,0) [0|1] "" Vector__XXX
 SG_ KOM_ASIC_Fehler : 25|1@1+ (1,0) [0|1] "" Vector__XXX
 SG_ KOM_Fehler3 : 26|1@1+ (1,0) [0|1] "" Vector__XXX
 SG_ KOM_Fehler4 : 27|1@1+ (1,0) [0|1] "" Vector__XXX
 SG_ KOM_Fehler5 : 28|1@1+ (1,0) [0|1] "" Vector__XXX
 SG_ KOM_Fehler6 : 29|1@1+ (1,0) [0|1] "" Vector__XXX
 SG_ KOM_Fehler7 : 30|1@1+ (1,0) [0|1] "" Vector__XXX
 SG_ KOM_KD_Fehler : 31|1@1+ (1,0) [0|1] ""  Gateway_PQ35,Gateway_PQ46

BO_TX_BU_ 995 : Gateway_PQ35,Gateway_PQ46;
BO_TX_BU_ 1505 : Gateway_PQ35,Gateway_PQ46;
BO_TX_BU_ 1507 : Gateway_PQ35,Gateway_PQ46;
BO_TX_BU_ 1629 : Gateway_PQ35,Gateway_PQ46;
BO_TX_BU_ 1589 : Gateway_PQ35,Gateway_PQ46;
BO_TX_BU_ 1583 : Gateway_PQ35,Gateway_PQ46;
BO_TX_BU_ 1391 : Booster_AMP,DSP_SKODA;
BO_TX_BU_ 1550 : Gateway_PQ35,Gateway_PQ46;
BO_TX_BU_ 1471 : Gateway_PQ35,Gateway_PQ46;
BO_TX_BU_ 1631 : Gateway_PQ35,Gateway_PQ46;
BO_TX_BU_ 849 : Gateway_PQ35,Gateway_PQ46;
BO_TX_BU_ 1619 : Gateway_PQ35,Gateway_PQ46;
BO_TX_BU_ 857 : Gateway_PQ35,Gateway_PQ46;
BO_TX_BU_ 1315 : Gateway_PQ35,Gateway_PQ46;
BO_TX_BU_ 1319 : Gateway_PQ35,Gateway_PQ46;
BO_TX_BU_ 859 : Gateway_PQ35,Gateway_PQ46;
BO_TX_BU_ 1367 : Gateway_PQ35,Gateway_PQ46;
BO_TX_BU_ 1569 : Gateway_PQ35,Gateway_PQ46;
BO_TX_BU_ 1571 : Gateway_PQ35,Gateway_PQ46;
BO_TX_BU_ 1573 : Gateway_PQ35,Gateway_PQ46;
BO_TX_BU_ 1575 : Gateway_PQ35,Gateway_PQ46;
CM_ SG_ 995 CL2_Sonne_links "FF = Fehler
Sonnensensor links";
CM_ SG_ 995 CL2_Sonne_rechts "FF = Fehler
Sonnensensor rechts";
CM_ SG_ 995 CL2_InnenTemp "FF = Fehler
Innenraumtemperatur";
CM_ SG_ 995 CL2_SitzH_links "Status Sitzheizung links
Sitzheizung links Stufe 0...6";
CM_ SG_ 995 CL2_SitzH_rechts "Status Sitzheizung rechts
Sitzheizung rechts Stufe 0...6";
CM_ SG_ 995 CL2_StSt_Info "Stopp-Freigabe/Start-Anforderung für den Start-Stopp-Koordinator";
CM_ SG_ 995 CL2_SH "1 = Standheizung ein, 0 = Standheizung aus";
CM_ SG_ 995 CL2_SL_LED "1 = Kontrolllampe SL_LED ein
Kontrollampe Standlueftung";
CM_ SG_ 995 CL2_Geblaese_plus "1 = Geblaeseleistung Standheizung erhoehen oder Standheizung/ Lueftung ein erhalten
Geblaese plus, Standheizung - Lueftung ein erhalten";
CM_ SG_ 995 CL2_Umluft_Taste "1 = Taste gedrueckt, 0 = Taste nicht gedrueckt
Umluft Taste gedrueckt";
CM_ SG_ 995 CL2_Solltemperatur "Solltemperatur fuer RNSE
Wertebeschreibung:
0 = Klima OFF
1..4 = keine Anzeige
5 = Low
6..9 = keine Anzeige
10..34 = 16,0°C - 28,0°C; Schrittweite 0,5°C
35..109 = keine Anzeige
110..134 = 60°F - 84°F; Schrittweite 1,0°F
135..199 = keine Anzeige
";
CM_ SG_ 995 CL2_Vorgabe_KWTemp "FF = Fehler
Vorgabe der Kuehlwassertemperatur";
CM_ SG_ 1505 CL3_Umluft "1 = ein
Status Umluftbetrieb";
CM_ SG_ 1505 CL3_Restwaerme "1= ein
Restwaermebetrieb";
CM_ SG_ 1505 CL3_Mono "1 = Clima Status MONO aktiviert";
CM_ SG_ 1505 CL3_Luftguetesensor "1 = ein Umluftautomatik
Status Luftguetesensor AQS";
CM_ SG_ 1505 CL3_Defrost "1 = ein
Status Defrost";
CM_ SG_ 1505 CL3_Solarbelueftung "1 = Solarbelueftungsmodus ist eingeschaltet (Klappen sind geoeffnet)
Im D1GP2 wird diese Info vom RNS auf dem I-CAN empfangen.
Status Solarbelueftung";
CM_ SG_ 1505 CL3_Econ "1 = ein
Status ECON-Betrieb";
CM_ SG_ 1505 CL3_Klima_Hauptschalter "1 = Klimaanlage ist ausgeschaltet
Status Klimaanlage OFF";
CM_ SG_ 1505 CL3_KlimaOffFond "1 - Klimaanlage Fond ist ausgeschaltet (Rückmeldung für Anzeige)
Status Klimaanlage Fond";
CM_ SG_ 1505 CL3_Bedien_mgl "1= Mitteilung, daß eine Bedienung ueber externe Bedieneinheit moeglich ist (z.B. nach Wake-up oder Reset)";
CM_ SG_ 1505 CL3_nAkt_Uml_Fond "1 = nicht aktivierbar
Umluft von BT Fond nicht aktivierbar";
CM_ SG_ 1505 CL3_nAkt_Umluft "1 = nicht aktivierbar
Umluft von BT Vorne nicht aktivierbar";
CM_ SG_ 1505 CL3_nAkt_Econ "1 = nicht aktivierbar
Econ nicht aktivierbar";
CM_ SG_ 1505 CL3_nAkt_AQS "1 = nicht aktivierbar
Luftguetesensor (AQS) nicht aktivierbar";
CM_ SG_ 1505 CL3_nAkt_Restwaerme "1 = nicht aktivierbar
Restwaermebetrieb nicht aktivierbar";
CM_ SG_ 1505 CL3_Hzg_LF_Sens "1 = Bfehl Heizung einschalten, 0 = Heizung ausschalten
Heizung des Luftfeuchtesensors";
CM_ SG_ 1505 CL3_V_Qtg_Zaehler "Der Zaehlerstand aus mBedClima_1 wird hier uebernommen
Quittungszaehler fuer Einstellungen vorn";
CM_ SG_ 1505 CL3_H_Qtg_Zaehler "Der Zaehlerstand aus mBedClima_1, also mBedClima_3 wird hier uebernommen
Quittungszaehler fuer Einstellungen hinten";
CM_ SG_ 1505 CL3_StandHzg "Befehl z. aus-/einschalten der Standheizung";
CM_ SG_ 1505 CL3_Anstr_VL_Kopf "1 = auf
Status Anstroemer vorne links Kopf (auf/zu)";
CM_ SG_ 1505 CL3_Anstr_VL_Mann "1 = auf
Status Anstroemer vorne links Mann (auf/zu)";
CM_ SG_ 1505 CL3_Anstr_VL_Fuss "1 = auf
Status Anstroemer vorne links Fuss (auf/zu)";
CM_ SG_ 1505 CL3_Anstr_VL_Automatik "1 = auf
Status Anstroemer vorne links Auto (ein/aus)";
CM_ SG_ 1505 CL3_Anstr_VR_Kopf "1 = auf
Status Anstroemer vorne rechts Kopf (auf/zu)";
CM_ SG_ 1505 CL3_Anstr_VR_Mann "1 = auf
Status Anstroemer vorne rechts Mann (auf/zu)";
CM_ SG_ 1505 CL3_Anstr_VR_Fuss "1 = auf
Status Anstroemer vorne rechts Fuss (auf/zu)";
CM_ SG_ 1505 CL3_Anstr_VR_Automatik "1 = auf
Status Anstroemer vorne rechts Auto (ein/aus)";
CM_ SG_ 1505 CL3_Anstr_HL_Kopf "1 = auf
Status Anstroemer hinten links Kopf (auf/zu)";
CM_ SG_ 1505 CL3_Anstr_HL_Mann "1 = auf
Status Anstroemer hinten links Mann (auf/zu)";
CM_ SG_ 1505 CL3_Anstr_HL_Fuss "1 = auf
Status Anstroemer hinten links Fuss (auf/zu)";
CM_ SG_ 1505 CL3_Anstr_HL_Automatik "1 = auf
Status Anstroemer hinten links Auto (ein/aus)";
CM_ SG_ 1505 CL3_Anstr_HR_Kopf "1 = auf
Status Anstroemer hinten rechts Kopf (auf/zu)";
CM_ SG_ 1505 CL3_Anstr_HR_Mann "1 = auf
Status Anstroemer hinten rechts Mann (auf/zu)";
CM_ SG_ 1505 CL3_Anstr_HR_Fuss "1 = auf
Status Anstroemer hinten rechts Fuss (auf/zu)";
CM_ SG_ 1505 CL3_Anstr_HR_Automatik "1 = auf
Status Anstroemer hinten rechts Auto (ein/aus)";
CM_ SG_ 1505 CL3_FT_Defrost "1 = auf
Status Defrostausstroemer Fahrertuer";
CM_ SG_ 1505 CL3_BT_Defrost "1 = auf
Status Defrostausstroemer Beifahrertuer";
CM_ SG_ 1505 CL3_StandLftg "1=aktiv, 0=deaktiv
Standlueftungsmodus";
CM_ SG_ 1505 CL3_SH_ein_KDWunsch "1 = Kundenwunsch Standheizung einschalten";
CM_ SG_ 1505 CL3_SH_Wasserpumpe "Anforderung zur Ansteuerung der SH- Wasserpunmpe im Restwaermebetrieb; 1 = Wasserpumpe ein; 0 = aus";
CM_ SG_ 1505 CL3_ein_Lenkrad_Hzg "1 = Lenkradheizung einschalten; 0 = Lenkradheizung aus. Dieses Biot wird in Abhaengigkeit der Innentemperatur nur von der Climatronic gesetzt";
CM_ SG_ 1505 CL3_Gegendimmung "Gegenlichtdimmung Display";
CM_ SG_ 1507 CL4_VL_Ist_Temp "Zur Anzeige im Infotainment, FF = Fehler
Eingestellte Temperatur vorne links";
CM_ SG_ 1507 CL4_VR_Ist_Temp "An der Klimaanlage eingestellter Wert, kein gemessener Wert
Eingestellte Temperatur vorne rechts";
CM_ SG_ 1507 CL4_HL_Ist_Temp "An der Klimaanlage eingestellter Wert, kein gemessener Wert
Eingestellte Temperatur hinten links";
CM_ SG_ 1507 CL4_HR_Ist_Temp "An der Klimaanlage eingestellter Wert, kein gemessener Wert
Eingestellte Temperatur hinten rechts";
CM_ SG_ 1507 CL4_V_Gebl_Leistung "Eingestellte Geblaeseleistung vorn";
CM_ SG_ 1507 CL4_H_Gebl_Leistung "Eingestellte Geblaeseleistung hinten";
CM_ SG_ 1507 CL4_UG_Tempbereich "fuer Prioritaetsschaltungen ZAB vorn/hinten
Untergrenze des gueltigen Temperaturbereiches";
CM_ SG_ 1507 CL4_Deltatemp "0 = Begrenzung nicht verwendet
maximaler Temperaturgradient";
CM_ SG_ 1507 CL4_WSS_Temp "Temperatur an der Windschutzscheibe fuer interne Berechnungen des Regensensors";
CM_ SG_ 1507 CL4_V_Qtg_Zaehler "Bestaetigung des Zaehlerstandes fuer einen aus der Bedienbotschaft erhaltenen Befehl
Quittungszaehler fuer Einstellungen vorn";
CM_ SG_ 1507 CL4_V_Gebl_AutoMan "Modus Geblaese vorne: 0 = Automatik, 1 = Manuell";
CM_ SG_ 1507 CL4_H_Qtg_Zaehler "Bestaetigung des Zaehlerstandes fuer einen aus der Bedienbotschaft erhaltenen Befehl
Quittungszaehler f. Einst. hinten";
CM_ SG_ 1507 CL4_H_Gebl_AutoMan "Modus Geblaese hinten: 0 = Automatik, 1 = Manuell";
CM_ SG_ 1634 DA1_DAB_On "Festlegung von Statuscodes und Parametern erfolgt in separater Tabelle.
DAB-Tuner Einschaltzustand";
CM_ SG_ 1634 DA1_DAB_mute "Mute On/Off";
CM_ SG_ 1634 DA1_DAB_Error_flag "Fehlereintrag vorhanden";
CM_ SG_ 1634 DA1_DAB_Mode "siehe Spezifikation Mode-Codierung
Mode-Information";
CM_ SG_ 1634 DA1_DAB_Para1 "Parameter des jew. Modes";
CM_ SG_ 1634 DA1_DAB_Para2 "Parameter des jew. Modes";
CM_ SG_ 1634 DA1_DAB_Para3 "Parameter des jew. Modes";
CM_ SG_ 1634 DA1_DAB_Para4 "Parameter des jew. Modes";
CM_ SG_ 1634 DA1_DAB_Para5 "Parameter des jew. Modes";
CM_ SG_ 1634 DA1_DAB_Para6 "Parameter des jew. Modes";
CM_ BO_ 1629 "CAN-Dashboard CAN-Komfort CAN-Infotainment";
CM_ SG_ 1629 DN1_Verlernzaehler "FFh = Fehler, ungueltiger Zaehlerstand bzw. kein gueltiger Fahrzyklus
Binaer wrap around";
CM_ SG_ 1629 DN1_KM_Stand "Kilometerstand";
CM_ SG_ 1629 DN1_Jahr "0 für Datum unbekannt (z.B. keine Funkuhr)
(bei relativem Datum ist auch der Wert 0 gültig siehe Spezifikation_Tageszähler_Kombi_01.doc)";
CM_ SG_ 1629 DN1_Monat "0 = Monat unbekannt
Dh = ungueltig
Eh = relatives Datum siehe Spezifikation_Tageszähler_Kombi_01.doc
Fh = Keine Funkuhrinformation vorhanden und 12 h Anzeige (Monat, Tag, Jahr fehlen)";
CM_ SG_ 1629 DN1_Tag "0 für Datum unbekannt (z.B. keine Funkuhr)
(bei relativem Datum ist auch der Wert 0 gültig siehe Spezifikation_Tageszähler_Kombi_01.doc)";
CM_ SG_ 1629 DN1_Stunde "18h - 1Fh ungueltig";
CM_ SG_ 1629 DN1_Minute "3Ch - 3Fh ungueltig";
CM_ SG_ 1629 DN1_Sekunde "3Ch - 3Fh ungueltig";
CM_ SG_ 1629 DN1_alt_Kilometerstand "0 = Kilometerstand aktuell (vor < als 2 Sec vom Kombi empfangen)
1 = Kilometerstand veraltet";
CM_ SG_ 1629 DN1_alt_Zeit "0 = Zeit aktuell vom Kombi empfangen (< 2 sec)
1 = Zeit veraltet";
CM_ SG_ 1589 DI1_Display "7F = Fehlerwert, kein Ersatzwert; (100 % entspricht maximaler Beleuchtungsstaerke)
Displaydimmung; Tastverhaeltnis";
CM_ SG_ 1589 DI1_Display_def "1 = Fehler, bzw. nicht verfuegbar
Klemme 58d n.i.O";
CM_ SG_ 1589 DI1_Schalter "7F = Fehlerwert, kein Ersatzwert (Bei VW z.Zt. grundsaetzlich 7Fh)
Schalterdimmung; Tastverhaeltnis";
CM_ SG_ 1589 DI1_Schalter_def "1 = Fehler, bzw. nicht verfuegbar (Bei VW z.Zt. grundsaetzlich 1)
Klemme 58s n.i.O";
CM_ SG_ 1589 DI1_Sensor "Lichtsensorzustand lt. Dimmungsspezifikation";
CM_ SG_ 1583 DY1_Display_OK "1 = Diplay ist bereit um Daten anzuzeigen (z.B. Klemme 15 ist ein)";
CM_ SG_ 1583 DY1_Reset "1 = Anzeige wurde resetet";
CM_ SG_ 1583 DY1_Global_Reset "1 = Zuruecksetzen aller DDP-Teilnehmer in den Init-Zustand bzgl. Personalisierung
Reset aller DDP-Teilnehmer gefordert";
CM_ SG_ 1583 DY1_MFA_Down "1 = Taste gedrueckt
Taste MFA Down betaetigt";
CM_ SG_ 1583 DY1_MFA_Up "1 = Taste gedrueckt
Taste MFA Up betaetigt";
CM_ SG_ 1583 DY1_MFA_Reset "1 = Taste gedrueckt
Taste MFA Reset betaetigt";
CM_ SG_ 1583 DY1_MFA_WippeLang "1 = die Wippe wird gerade laenger als 2 Sekunden gehalten";
CM_ SG_ 1583 DY1_Bereich1 "Belegung des Displaybereiches mit einer Meldung mit der Prioritaet des Wertes.
Die genaue Zuordnung der Bereiche zum Display sind aus den Ergaenzungen zur DDP Spezifikation zu ersehen.
Displaybereich Nr. 1";
CM_ SG_ 1583 DY1_Bereich2 "Belegung des Displaybereiches mit einer Meldung mit der Prioritaet des Wertes.
Die genaue Zuordnung der Bereiche zum Display sind aus den Ergaenzungen zur DDP Spezifikation zu ersehen.
Displaybereich Nr. 2";
CM_ SG_ 1583 DY1_Bereich3 "Belegung des Displaybereiches mit einer Meldung mit der Prioritaet des Wertes.
Die genaue Zuordnung der Bereiche zum Display sind aus den Ergaenzungen zur DDP Spezifikation zu ersehen.
Displaybereich Nr. 3";
CM_ SG_ 1391 SD1_DSP_Type "0 = keine Info verfuegbar
1 = 8 K. Linearverst.
2 = 8 K. Verst m. Klangregelung
3 = 12 K. DSP
DSP Typ Information";
CM_ SG_ 1391 SD1_Power_Mode "Rueckmeldung des Verstaerker Betriebszustandes s. mMenu_DSP_1";
CM_ SG_ 1391 SD1_KD_Fehler "1 = mindestens ein Kundendienstfehler ist im Steuergeraet eingetragen";
CM_ SG_ 1391 SD1_Ch1_Fading_in_process "1 = Angesteuerter Cross-Fading Lauf in Kanal 1 ist zur Zeit aktiv";
CM_ SG_ 1391 SD1_Ch2_Fading_in_process "1 = Angesteuerter Cross-Fading Lauf in Kanal 2 ist zur Zeit aktiv";
CM_ SG_ 1391 SD1_Ch3_Fading_in_process "1 = Angesteuerter Cross-Fading Lauf in Kanal 3 ist zur Zeit aktiv";
CM_ SG_ 1550 EH1_Einh_Strck "0 = km
1 = mls
Einheit Streckenanzeige (km/mls)";
CM_ SG_ 1550 EH1_Einh_Temp "0 = °C
1 = °F
Einheit Temperaturanzeige ( °C / °F )";
CM_ SG_ 1550 EH1_Einh_Vol "0 = liter
1 = gallons
Einheit_Volumen ( liter / gallons)";
CM_ SG_ 1550 EH1_Einh_Verbr "0= Strecke / Volumen
1 = Volumen / Strecke
Einheit Verbrauchsanzeige ( Vol./Strecke ; Strecke/Vol.)";
CM_ SG_ 1550 EH1_Einh_Druck "0 = Druckangabe in bar
1 = Druckangabe in psi
2 = n.n.
3 = Druck in kPa
Einheit Druck (bar/psi/_/kPa)";
CM_ SG_ 1550 EH1_Datum_Anzeige "Anzeigeformat des Datums (Europäisch = 0, amerikanisch = 1)";
CM_ SG_ 1550 EH1_Uhr_Anzeige "0 = 24 Stunden Anzeige
1 = 12 Stunden Anzeige
Anzeige 12 24 Stunden";
CM_ SG_ 1550 EH1_Profil "aktuelle Profilnummer";
CM_ SG_ 1550 EH1_Wochentag "0 =Init, 1=Mo, 2=Di, 3=Mi, 4=Do, 5=Fr, 6=Sa, 7=So
Wochentag";
CM_ SG_ 1550 EH1_Verstellung_Strck "Das Kombi kann mittels Personalisierung die Einheit für die Strecke (km/mls) verstellen.
Verstellung der Einheit Strecke via Personalisierung";
CM_ SG_ 1471 MFL_Tastencode_1 "siehe MFL-Codes
Symbolcode 1";
CM_ SG_ 1471 MFL_Tastencode_2 "siehe MFL-Codes
Symbolcode 2";
CM_ SG_ 1471 MFL_Eventcode_1 "Walze:
0 = kein Tick
1...7 = +1...+7 Ticks
8 = Fehlerwert
9...15 = -7...-1 Ticks

Taste:
0 = no Event
1 = pressed
3 = double-click
4 = long-press 1 [800ms]
5 = long-press 2 [2s]
6 = long-press 3 [3s]

Tickzaehler od. Eventcode Walze 1";
CM_ SG_ 1471 MFL_Eventcode_2 "Walze:
0 = kein Tick
1...7 = +1...+7 Ticks
8 = Fehlerwert
9...15 = -7...-1 Ticks

Taste:
0 = no Event
1 = pressed
3 = double-click
4 = long-press 1 [800ms]
5 = long-press 2 [2s]
6 = long-press 3 [3s]

Tickzaehler od. Eventcode Walze 2";
CM_ SG_ 1471 MFL_Marke "0 = VW
1 = AU
2 = SE
3 = SK
4 = VN
5 = Bugatti
6 = Lamborghini
7 = Bentley
8 = Rolls Royce
14 = Ford
15 = Porsche
Fahrzeughersteller nach Kenntnisstand des Senders";
CM_ SG_ 1471 MFL_Variante "Variante für unterschiedliche Tasten / Tastenbelegungen verschiedener MFL";
CM_ BO_ 1631 "CAN-Komfort";
CM_ SG_ 1631 FI1_MUX "Multiplexbyte zur Berechnung der folgenden Datenbytes
Schaltet die naechsten 7 Byte um.
VW756/VW611: Reihenfolge der Inhalte für schnelle Initialisierung anderer Steuergeräte über Ident-Wert 0 folgendermaßen definiert 0, 1, 0, 2, 0, 1, 0, ...";
CM_ SG_ 1631 FI1_Geheimnis_1 "Multiplex = 0
1. Byte Fahrzeuggeheimnis (nicht PQ35/46)";
CM_ SG_ 1631 FI1_VIN_4 "Multiplex = 1
4. Stelle der Fahrgestellnummer
WFS nicht angelernt: Ausgabe 'X' (0x58) oder '-' (0x2D)";
CM_ SG_ 1631 FI1_VIN_11 "Multiplex = 2
11. Stelle der Fahrgestellnummer
WFS nicht angelernt: Ausgabe 'X' (0x58) oder '-' (0x2D)";
CM_ SG_ 1631 FI1_Geheimnis_2 "Multiplex = 0
2. Byte Fahrzeuggeheimnis (nicht PQ35/46)";
CM_ SG_ 1631 FI1_VIN_5 "Multiplex = 1
5. Stelle der Fahrgestellnummer
WFS nicht angelernt: Ausgabe 'X' (0x58) oder '-' (0x2D)";
CM_ SG_ 1631 FI1_VIN_12 "Multiplex = 2
12. Stelle der Fahrgestellnummer
WFS nicht angelernt: Ausgabe 'X' (0x58) oder '-' (0x2D)";
CM_ SG_ 1631 FI1_Geheimnis_3 "Multiplex = 0
3. Byte Fahrzeuggeheimnis (nicht PQ35/46)";
CM_ SG_ 1631 FI1_VIN_6 "Multiplex = 1
6. Stelle der Fahrgestellnummer
WFS nicht angelernt: Ausgabe 'X' (0x58) oder '-' (0x2D)";
CM_ SG_ 1631 FI1_VIN_13 "Multiplex = 2
13. Stelle der Fahrgestellnummer
WFS nicht angelernt: Ausgabe 'X' (0x58) oder '-' (0x2D)";
CM_ SG_ 1631 FI1_Geheimnis_4 "Multiplex = 0
4. Byte Fahrzeuggeheimnis (nicht PQ35/46)";
CM_ SG_ 1631 FI1_VIN_7 "Multiplex = 1
7. Stelle der Fahrgestellnummer
WFS nicht angelernt: Ausgabe 'X' (0x58) oder '-' (0x2D)";
CM_ SG_ 1631 FI1_VIN_14 "Multiplex = 2
14. Stelle der Fahrgestellnummer
WFS nicht angelernt: Ausgabe 'X' (0x58) oder '-' (0x2D)";
CM_ SG_ 1631 FI1_VIN_1 "Multiplex = 0
1. Stelle der Fahrgestellnummer
WFS nicht angelernt: Ausgabe 'X' (0x58) oder '-' (0x2D)";
CM_ SG_ 1631 FI1_VIN_8 "Multiplex = 1
8. Stelle der Fahrgestellnummer
WFS nicht angelernt: Ausgabe 'X' (0x58) oder '-' (0x2D)";
CM_ SG_ 1631 FI1_VIN_15 "Multiplex = 2
15. Stelle der Fahrgestellnummer
WFS nicht angelernt: Ausgabe 'X' (0x58) oder '-' (0x2D)";
CM_ SG_ 1631 FI1_VIN_2 "Multiplex = 0
2. Stelle der Fahrgestellnummer
WFS nicht angelernt: Ausgabe 'X' (0x58) oder '-' (0x2D)";
CM_ SG_ 1631 FI1_VIN_9 "Multiplex = 1
9. Stelle der Fahrgestellnummer
WFS nicht angelernt: Ausgabe 'X' (0x58) oder '-' (0x2D)";
CM_ SG_ 1631 FI1_VIN_16 "Multiplex = 2
16. Stelle der Fahrgestellnummer
WFS nicht angelernt: Ausgabe 'X' (0x58) oder '-' (0x2D)";
CM_ SG_ 1631 FI1_VIN_3 "Multiplex = 0
3. Stelle der Fahrgestellnummer
WFS nicht angelernt: Ausgabe 'X' (0x58) oder '-' (0x2D)";
CM_ SG_ 1631 FI1_VIN_10 "Multiplex = 1
10. Stelle der Fahrgestellnummer
WFS nicht angelernt: Ausgabe 'X' (0x58) oder '-' (0x2D)";
CM_ SG_ 1631 FI1_VIN_17 "Multiplex = 2
17. Stelle der Fahrgestellnummer
WFS nicht angelernt: Ausgabe 'X' (0x58) oder '-' (0x2D)";
CM_ SG_ 849 GW1_FhzgGeschw_alt "Veraltetbit wird bei Ausfall der Botschaft am CAN Antrieb nach 50 ms gesetzt. Entspricht GWB_Alt_1_Bremse
Fahrzeuggeschwindigkeit veraltet";
CM_ SG_ 849 GW1_Rueckfahrlicht "1 = Rueckfahrlicht ein";
CM_ SG_ 849 GW1_FzgGeschw "Low Byte 3, High Byte 4 (Auflösung 1,28 km/h)
Bremse holt sich den Radumfang aus der Botschaft 'Kombi_3'
generell wird Mittelwert (alle außer B6/D3) der permanent angetriebenen Räder ausgegeben (d.h. bei Frontantrieb und gesteuertem Allrad (Haldex) Mitt";
CM_ SG_ 849 KKO_alt_mBSG_Kombi "Veraltetinformation der Botschaft mBSG_Kombi
Wird gesetzt nach zweimaligem Nichtempfang der Botschaft (100 ms)";
CM_ SG_ 1619 GW3_Laendervariante "Code 00: Länder- und Sprachvariante werden nur ausgegeben, wenn Sie im Kombi vorliegen (z.B. Highline)
Kombi Multiplex Info (Ländervariante)";
CM_ SG_ 1619 GW3_Alt_3_Kombi "1 = Wert veraltet (>100 ms)
veraltete Signale aus Botschaft Kombi 3";
CM_ SG_ 1619 GW3_Land_Sprach_empf "Die Laender und Sprachvariante werden aus der Botschaft mKombi_3 genommen. Da die Werte in ihrer Quellenbotschaft als Multiplexinformation gesendet wird, bezeichnet dieses Bit, dass der Inhalt nicht der Initwert ist, sondern die Informationen korrekt gese";
CM_ SG_ 1619 GW3_Sprachvariante "Code 00: Länder- und Sprachvariante werden nur ausgegeben, wenn Sie im Kombi vorliegen (z.B. Highline)
Kombi Multiplex Info (Sprachvariante)";
CM_ SG_ 1619 GW3_Motortyp "Motor Multiplex-Info (Motortyp) (Code 10)
Bit 3...0: Zweizylinder 2 Dreizylinder 3 Vierzylinder 4 Fuenfzylinder 5 Sechszylinder 6 Achtzylinder 8 Zehnzylnder 10 Zwoelfzylinder 12 Fuenfzehnzylinder 13 Sechzehnzylinder 14 Achtzehnzylinder 15
Bit 4: Turbo_M";
CM_ SG_ 1619 GW3_Alt_5_Motor "veraltete Signale aus Botschsaft Motor 5";
CM_ SG_ 1619 GW3_Motortyp_empf "Der Motortyp wird aus der Botschaft mMotor_5 genommen. Da der Wert in seiner Quellenbotschaft als Multiplexinformation gesendet wird, bezeichnet dieses Bit, dass der Inhalt nicht der Initwert ist, sondern die Information korrekt gesetzt ist.
Motortyp emp";
CM_ SG_ 1487 GS1_Error_flag "Fehlereintrag vorhanden";
CM_ SG_ 857 GWB_Alt_FzgGeschw "Veraltetbit wird bei Ausfall der Botschaft am CAN Antrieb nach 50 ms gesetzt. Entspricht GWB_Alt_1_Bremse
Fahrzeuggeschwindigkeit veraltet";
CM_ SG_ 857 GWB_Alt_2_Bremse "Veraltetbit wird bei Ausfall der Botschaft mBremse_2 am CAN Antrieb nach 50 ms gesetzt.
veraltete Signale aus Botschaft Bremse 2 ( Byte 4 bis 6)";
CM_ SG_ 857 GWB_Alt_1_Bremse "Veraltetbit wird bei Ausfall der Botschaft mBremse_1 am CAN Antrieb nach 50 ms gesetzt.
veraltete Signale aus Botschaft Bremse 1 (Byte 7)";
CM_ SG_ 857 GWB_Alt_1_Getriebe "Veraltetbit wird bei Ausfall der Botschaft mGetriebe_1 am CAN Antrieb nach 50 ms gesetzt.
veraltete Signale aus Botschaft Getriebe 1";
CM_ SG_ 857 GWB_Alt_2_Getriebe "Veraltetbit wird bei Ausfall der Botschaft mGetriebe_2 am CAN Antrieb nach 50 ms gesetzt.
veraltete Signale aus Botschaft Getriebe 2";
CM_ SG_ 857 GWB_Alt_1_EPB "Veraltetbit wird bei Ausfall der Botschaft mEPB_1 auf dem CAN Antrieb nach 50ms gesetzt
veraltete Signale aus Botschaft mEPB_1";
CM_ SG_ 857 GWB_Alt_5_Bremse "Veraltetbit wird bei Ausfall der Botschaft mBremse_5 auf dem CAN Antrieb nach 50 ms gesetzt
veraltete Signale aus Botschaft mBremse_5";
CM_ SG_ 857 GWB_FzgGeschw_Quelle "1 = ABS-Signal
Signalquelle FzgGeschw.";
CM_ SG_ 857 GWB_FzgGeschw "Low Byte 3, High Byte 4 (Auflösung 1,28 km/h)
Bremse holt sich den Radumfang aus der Botschaft 'Kombi_3'
generell wird Mittelwert (alle außer B6/D3) der permanent angetriebenen Räder ausgegeben (d.h. bei Frontantrieb und gesteuertem Allrad (Haldex) Mitt";
CM_ SG_ 857 GWB_Wegimpulse "Anzahl der Raddrehzahl-impulse (steigende und fallende Flanke) der Vorderachse (gemittelt) zur Wegstreckenzählung
bei Ausfall eines Drehzahlfühlers wird der funktionsfähige Sensor zur Ausgabe verwendet
Wegimpulse Vorderachse

Im RPU wird die Hinterach";
CM_ SG_ 857 GWB_Wegimpuls_Status "der Wegimpuls-Zähler ist mindestens einmal übergelaufen (Reset des ABS-Steuergerätes) kann damit erkannt werden
Wegimpulszählerstatus";
CM_ SG_ 857 GWB_Wegimpulse_Fehler "Fehler wird gesetzt, wenn beide ABS-Drehzahlfühler an der Vorderachse defekt sind
Fehlerstatus Wegimpulse";
CM_ SG_ 857 GWB_Impulszahl "Zähnezahl des verwendeten Impulsrades
Bei Neuentwicklungen muss die Impulszahl aus Byte 1 (Ausgabe während der Hochlaufphase) verwendet werden";
CM_ SG_ 857 GWB_Alt_PLA_Status "Veraltetbit wird bei Ausfall der Botschaft mBremse_1 am CAN Antrieb nach 50 ms gesetzt.
veraltete Signale aus Botschaft Bremse 1 (Byte 7)";
CM_ SG_ 857 PLS_Bremsleuchte "Bei einer durch PLA initiierten Bremsung des Fahrzeugs muss Bremsleuchte angesteuert werden. Dieses Signal ist der Befehl, die Bremsleuchte einzuschalten, an dasjenige Steuergerät, das sie schaltet.";
CM_ SG_ 857 GWB_TSP_aktiv "wenn Gespannstabilisierungs-Regelung zu einer Verzögerung führt, wird das Bit gesetzt: im Colorado zusätzlich zum Hardware-ausgang, in PQ35 / PQ46 ohne Hardware-Ausgang (nicht D1GP/BY61x)
Wird im T5GP und RPU umgesetzt für Bremslicht-Ansteuerung.
Gespan";
CM_ SG_ 857 GWB_Notbremsung "Automatische Aktivierung des Warnblinkers und Bremsflächenvergrößerung bei Notbremsung. Funktion im ESP8 & ILM-Hinten ab Audi C6 erstmalig implementiert. (nicht PQ46) (nicht D1GP/BY61x)
Notbremsanzeige";
CM_ SG_ 857 GWB_ABS_Bremsung "Antiblockiersystem, Bit zeigt auch Druckabbau an (z.B. ESP hat zuviel Druck aufgebaut oder ungebremste Regelung auf Bahnübergang)";
CM_ SG_ 857 GWB_EPB_Status "Gibt den Zustand der EPB-Aktuatoren an. Verknüpfung mit Fehlerstatus; wenn z.B. 'Linke Seite Fehlerhaft' und 'Bremse geschlossen', dann ist nur die rechte Seite geschlossen. Das Bit gesetzt, wenn auf einer Seite Spannkraft aufgebaut wird. Wenn auf beiden ";
CM_ SG_ 857 GWB_EPB_Bremslicht "Bremslichtansteuerung bei dynamischer Abbremsung (nur im PQ46)";
CM_ SG_ 857 GWB_Schlechtweg "OBD-Funktion (MAD-Signal), wird bei Teves / TRW z.Zt. nicht ausgegeben
Schlechtwegausblendung";
CM_ SG_ 857 GWB_Schlechtweg_Fehler "ESP 5.7: Im ESP-Fehlerfall ist Bit 'ungültig'
ESP 8: Im ESP-Fehler ist Bit weiterhin 'gültig'
Initwert 1 wird gesendet, wenn Funktion nicht umgesetzt
Fehlerstatus Schlechtwegausblendung";
CM_ SG_ 857 GWB_Geschw_Ersatz "Geschwindigkeit wird als Ersatzwert ausgegeben (z.B. ein Sensor defekt, kein Radumfang gelernt, kein oder fehlerhafter Radumfang vom Kombi empfangen oder bei Contiteves und passiven Sensoren wird Hinterrad eingespiegelt)
Geschwindigkeits-Ersatzwert";
CM_ SG_ 857 GWB_Schaltvorgang "Schaltung aktiv (Getriebe 1)";
CM_ SG_ 857 ANB_Teilbremsung_Freigabe "Freigabe-Bit der Teilbremsung an das ESP";
CM_ SG_ 857 GWB_ESP_Eingriff "Fahrdynamikregelung
ESP Eingriff";
CM_ SG_ 857 GWB_Shift_Lock "Wählhebel ist durch Shift-Lock Funktion blockiert
Falls Senderkennung = 1 (MSG): Bedienung mit Initwert
Shift-Lock-Lampe";
CM_ SG_ 857 GWB_Info_Waehlhebel "bei Selespeed Bedeutung 'Fahrprogramm', da keine Wählhebelgasse vorhanden ist;Anmerkung: Empfänger erwartet 'P' wegen Zündschlüsselabzugsperre.
Das Selespeed-Getriebe (automatisierter Handschalter) hat den Zustand 'P' nicht, bedient aber den Wert (08H), ";
CM_ SG_ 1315 GWI_alt_ZKE_4 "1 = Botschaft mZKE_4 nicht empfangen (>400 ms)";
CM_ SG_ 1315 GWI_alt_Kombi_1 "1 = Wert veraltet (>200 ms)
veraltete Signale aus Botschaft Kombi 1";
CM_ SG_ 1315 GWI_Status_Verdeck "Signal zeigt den Status des manuellen Verdeckes an.";
CM_ SG_ 1315 GWI_ZKE4_Zusatzfkt "Zusatzfunktionen des Komfortsteuergeräts sind verfuegbar, wenn DLC von mZKE_4 >6";
CM_ SG_ 1315 GWI_Blk_ZV_auf "Zusatzinfo, statisch zu ZK3_Blinker_ein (Modesignal)
Modesignal: Blinkerquittierung ZV auf";
CM_ SG_ 1315 GWI_Blk_ZV_zu "Zusatzinfo, statisch zu ZK3_Blinker_ein (Modesignal)
Modesignal: Blinkerquittierung ZV zu";
CM_ SG_ 1315 GWI_Blk_DW_ein "Zusatzinfo, statisch zu ZK3_Blinker_ein (Modesignal)
Modesignal: Blinkerquittierung DWA ein";
CM_ SG_ 1315 GWI_DWA_Alarm "Zusatzinfo, statisch zu ZK3_Blinker_ein (Modesignal)
Modesignal: Alarmblinken DWA";
CM_ SG_ 1315 GWI_verriegelt_int "1 = Fahrzeug innen verriegelt (Sollzustand nach Befehl)
Fahrzeug verriegelt per Innentaster (Soll)";
CM_ SG_ 1315 GWI_verriegelt_ext "1 = Fahrzeug aussen verriegelt (Sollzustand nach Befehl)
Fahrzeug verriegelt per Funk/Schl. (Soll)";
CM_ SG_ 1315 GWI_gesaeft_ext "1 = Fahrzeug aussen gesafet (Sollzustand nach Befehl)
Fahrzeug gesafet per Funk/Schl. (Soll)";
CM_ SG_ 1315 KB1_angez_kmh "Am Tacho angezeigte Geschwindigkeit (incl. Voreilung)
Angezeigte Geschwindigkeit";
CM_ SG_ 1319 GWK_Alt_3_Kombi "1 = Wert veraltet (>100 ms)
veraltete Signale aus Botschaft Kombi 3";
CM_ SG_ 1319 GWK_Alt_2_Kombi "veraltete Signale aus Botschaft Kombi 2";
CM_ SG_ 1319 GWK_Alt_1_Kombi "1 = Wert veraltet (>200 ms)
veraltete Signale aus Botschaft Kombi 1";
CM_ SG_ 1319 GWK_Reifenumfang_empf "Der Reifenumfang wird aus der Botschaft mKombi_3 genommen. Da der Wert in seiner Quellenbotschaft als Multiplexinformation gesendet wird, bezeichnet dieses Bit, dass der Inhalt nicht der Initwert ist, sondern die Information korrekt gesetzt ist.
MUX Inha";
CM_ SG_ 1319 GWK_FzgGeschw_Quelle "Die Fahrzeuggeschwindigkeit wird aus einem Tachogeber (eigener Hallgeber, eigener Reed-Kontakt, Fahrtenschreiber) oder aus der Referenzgeschwindigkeit vom ABS berechnet (nicht Audi D3/C6)
Signalquelle Geschwindigkeit";
CM_ SG_ 1319 GWK_FzgGeschw "Fahrzeuggeschwindigkeit als Rohsignal vom Tachogeber (ab ca. 25 km/h eine Geberradumdrehung, d.h. z.Zt. Mittelwert aus 4 Perioden der wahren Geschwindigkeit) oder vom ABS-Steuergerät (Raddrehzahl x Radumfang)
die Auflösung entspricht der ABS-Geschwindigk";
CM_ SG_ 1319 GWK_Umfang_Reifen "Code 10: mittlerer Reifenumfang in Millimeter (Byte 2 Bit 5,4 reserviert, Byte 2 Bit 3..0 und Byte 1 Bit 7..0; Wertebereich 0..4096 mm)
Kombi Multiplex Info (Radumfang)";
CM_ SG_ 1319 GWK_AussenTemp_gefiltert "realer Meßbereich z. Zt. ca. -45..58 Grad
0 für nicht verbaut

im Fehlerfall (FFH) ggf. auf Byte 8, Bit 7..4 achten
Außentemperatur gefiltert";
CM_ SG_ 1319 GWK_AussenTemp_ungefiltert "Klima-Steuergerät kann aus dem Rohsignal eigene Plausibilitäten berechnen
0 für nicht verbaut
im Hochlauf alter abgespeicherter Wert bis neuer vorliegt
Besonderheit Initwerte Temperaturen (bei VW und Audi ???):

0/1*:
0: Klemme 30 Reset
1: Klemme 1";
CM_ SG_ 1319 GWK_AussenTemp_Fehler "Diese Botschaft wird mit der Botschaft mKombi_1 zeitlich verzahnt gesendet!!!
n.i.O. steht für Fehlerwert, außerhalb des Meßbereichs (ungenau), nicht verbaut oder noch kein aktueller Wert
Besonderheit Initwerte Temperaturen (bei VW und Audi ???):

0/1";
CM_ SG_ 1319 GWK_Warn_Heiss "Heißleuchtenvorwarnung 5 Grad (applizierbar) vor Erreichen der Warnschwelle für die Heißleuchte (nur PQ24/25/T5)
";
CM_ SG_ 1319 GWK_Passiv_Autolock "1 = Umschaltanforderung vom Kombi: 'Passiv Autolock / Autounlock'";
CM_ SG_ 1319 GWK_WFS_Schl_Ort "Schlüsselerkennung via Lesespule oder Keyless";
CM_ SG_ 1319 KB1_Lenkh_Lampe "Lenkhilfe-Sicherheits-Lampe wurde eingeschaltet";
CM_ SG_ 859 GWM_Alt_1_Motor "1 = Fehler oder Wert veraltet (>100 ms)
veraltete Signale aus Botschsaft Motor 1";
CM_ SG_ 859 GWM_Alt_2_Motor "1 = Fehler oder Wert veraltet (>1 s)
veraltete Signale aus Botschsaft Motor 2";
CM_ SG_ 859 GWM_Alt_5_Motor "veraltete Signale aus Botschsaft Motor 5";
CM_ SG_ 859 GWM_Alt_Motor_Bremse "Veraltetbit wird bei Ausfall der Botschaft auf dem CAN Antrieb nach 50ms gesetzt
veraltete Signale aus Botschaft mMotor_Bremse";
CM_ SG_ 859 GWM_RME_Gehalt "Rapsölmethylester-Gehalt (Diesel) (wird z. Zt. nicht bedient)
(evtl. mit Bio-Ethanol-Gehalt bei Benzinern belegen)
(Info: Byte 4 war 'Fahrzeuggeschwindigkeit' teilw. noch im PQ25,T5GP)";
CM_ SG_ 859 GWM_Motordrehzahl "Low Byte 3, High Byte 4; es wird der letzte aktuelle Meßwert gesendet, d.h. die Zeit für das letzte Arbeitsspiel (180 Grad KW beim 4 Zylinder) wird herangezogen; der Fehlerwert wird gesendet, wenn das Motor-steuergerät keine plausible Drehzahlinformation ";
CM_ SG_ 859 GWM_KuehlmittelTemp "Motor-Kühlmitteltemperatur oder Ersatzwert
Initwert 0 ist außerhalb des Wertebereichs";
CM_ SG_ 859 GWM_Bremslicht_Schalter "Ungefiltertes Rohsignal (Fzg. ohne BLS (z. B. Touareg GP): siehe 'Spezifikation Schnittstelle und Verhalten bei Fahrerbremsung für Motorsteuergerät und Bremsensteuergerät im Touareg GP', Autor M. Williges)";
CM_ SG_ 859 GWM_Bremstest_Schalter "Ein Empfänger kann BLS und BTS miteinander plausibilisieren ('0' für nicht verbaut)
Fzg. ohne BTS (z.B. PQ46): Bit aus Bremse 1, Byte 2, Bit 3 Bremsdruckschwelle überschritten wird gespiegelt
Touareg GP: siehe 'Spezifikation Schnittstelle und Verhalten ";
CM_ SG_ 859 GWM_Fehl_KmittelTemp "n i.O. steht für Ersatzwert oder Fehlerwert in Byte 2
Fehlerstatus Kühlmitteltemperatur (Motor 2)";
CM_ SG_ 859 GWM_Kuppl_Schalter "nur Handschalter
aktiv, wenn Schalter verbaut, sonst konstant auf 0 gesetzt
Bit wird gesetzt, wenn Kupplungspedal nicht betätigt wird (Kupplungsschalter hoch), Triebstrang kann noch eingekuppelt sein
Kupplungsschalter";
CM_ SG_ 859 GWM_Heissl_Vorwarn "Klimaanlage mußte aufgrund einer Übertemperaturerkennung abgeschaltet werden (Schwelle entspricht der Heißleuchtenvorwarnschwelle)
Heißleuchtenvorwarnung";
CM_ SG_ 859 GWM_Klimaabschaltung "Motor-Steuergerät schaltet Klimakompressor aus";
CM_ SG_ 859 GWM_Kennfeldkuehlung "Die Kennfeldkühlung ist in diesem Fahrzeug verbaut und hat keinen Systemfehler";
CM_ SG_ 859 GWM_Komp_Leist_red "Klimakompressor-Leistungsreduzierung (im PQ35/46 z. Zt. nicht genutzt)";
CM_ SG_ 859 GWM_KLuefter "Istzustand der Kühlerlüfteransteuerung über die PWM Schnittstelle
Lüfterstufen (z.B. 14) werden in Prozente umgerechnet
Werte > 100% sind unzulässig (Mittelwert bei zwei Lüftern)
Kühlerlüfteransteuerung (Motor 5)";
CM_ SG_ 859 GWM_Anl_Freigabe "Bit wird gesetzt, wenn der Motor beim Automatikstart (nur im VW D1/Colorado Otto; nicht bei sonstigen Audi) gestartet werden darf (Motorstillstand, Emissionsmaßnahmen sind erfüllt,..)
Anlasser Freigabe";
CM_ SG_ 859 GWM_Anl_Ausspuren "Bit wird gesetzt, wenn der Motorhochlauf ohne Anlasserunterstützung beendet werden kann oder ein Start-Time Out erreicht wurde (nur im VW D1/Colorado Otto und PQ35/46; nicht bei sonstigen Audi)
Anlasser Ausspuren";
CM_ SG_ 859 GWM_Interlock "Interlockschalter muß beim Handschalter betätigt sein, damit ein Motorstart erlaubt ist (z.Zt. bei Audi-Handschalter mit Automatikstart und VW mit Automatikstart)
Bei Stufenautomaten (Audi) wird pauschal der Initwert gesendet.
Bei Stufenautomaten (VW) w";
CM_ SG_ 859 GWM_TypStartSteu "Automatikstart wird gesetzt, wenn das Motorsteuergerät den Motorstart automatisch steuert
Typ Startersteuerung";
CM_ SG_ 859 GWM_Freig_Bremsanforderung "Anforderung Bremsstellgröße (mMotor_Bremse: Byte 4,3) bzw. Summenradbremsmoment (mMotor_Bremse: Byte 5,4) wird freigegeben (Vorhalt)
Bremslicht wird angesteuert
Freigabe Bremsanforderung";
CM_ SG_ 859 GWM_Vorgluehen "Diesel-Vorglühlampe und Diesel-Systemlampe";
CM_ SG_ 859 GWM_GRA_Status "00 steht auch für nicht verbaut und ADR nicht zulässig
01 bedeutet eingeschaltet, GRA vom Fahrer aktiviert und z.Zt. im Regelbetrieb oder ADR erlaubt
10 Fahrer gibt mehr Gas als der Regler
11 Fehler in Motorsteuerung oder Time out oder CS-Fehler in Bot";
CM_ SG_ 859 GWM_KVerbrauch "Highbyte des Kraftstoffverbrauchssignales (entspricht Motor_5, Byte 4, Bit 0...7);Hinweis Erdgas-Projekt: Bei Erdgasbetrieb wird die Gas-Verbrauchsmenge in Einheit mg ausgegeben.
Kraftstoffverbrauchssignal Highbyte (s. Motor_5)
";
CM_ SG_ 859 GWM_Ueberl_KV "Der Motor-Steuergerät interne Verbrauchszähler ist mindestens einmal übergelaufen. Dieses Bit wird genutzt, um erkennen zu können, das das Motorsteuergerät aus dem Reset-Zustand hochläuft";
CM_ SG_ 1367 EKD_Motor_A "Bei gesetztem Bit ist mindestens ein Kundendienstfehler eingetragen";
CM_ SG_ 1367 EKD_Getriebe_A "Bei gesetztem Bit ist mindestens ein Kundendienstfehler eingetragen
Fehlerspeichereintrag (Getriebe 1)";
CM_ SG_ 1367 EKD_Bremse_A "Bei gesetztem Bit ist mindestens ein Kundendienstfehler eingetragen";
CM_ SG_ 1367 EKD_Kombi_A "Kundendienstfehler
Kombiinstrument am CAN-Antrieb";
CM_ SG_ 1367 EKD_LSM_A "Kundendienstfehler
Lenkwinkel";
CM_ SG_ 1367 EKD_Airbag_A "Bei gesetztem Bit ist mindestens ein Kundendienstfehler eingetragen";
CM_ SG_ 1367 EKD_Lenkhilfe_A "Bei gesetztem Bit ist mindestens ein Kundendienstfehler eingetragen
Fehlerspeichereintrag (Lenkhilfe 1)";
CM_ SG_ 1367 EKD_dyn_LWR_A "Bei gesetztem Bit ist mindestens ein Kundendienstfehler eingetragen (auch sporadische bzw. passive Fehler).
LWR und AFS Fehlerspeichereintrag";
CM_ SG_ 1367 EKD_Niveau_A "Kundendienstfehler
Niveauregulierung am CAN Antrieb";
CM_ SG_ 1367 EKD_Allrad_A "Bei gesetztem Bit ist mindestens ein Kundendienstfehler eingetragen";
CM_ SG_ 1367 EKD_ADR_Sensor_A "Bei gesetztem Bit ist mindestens ein Kundendienstfehler eingetragen
Fehlerspeichereintrag ACC-SG";
CM_ SG_ 1367 EKD_ADR_getrennt "ADR-Sensor kann vom CAN-Antrieb abgetrennt werden:
aktueller Zustand dieses Relais wird übertragen
Initwert 0: Hardware ohne Abtrennmöglichkeit (z. Zt. PQ35)
Initwert 1: Hardware mit bestückbarer Abtrennmöglichkeit (z. Zt. alle PQ46)";
CM_ SG_ 1367 EKD_Parkbremse_A "Bei gesetztem Bit ist mindestens ein Kundendienstfehler eingetragen";
CM_ SG_ 1367 EKD_EZS_A "Kundendienstfehler
EZS Steuergeraet
EKD_EZS_A";
CM_ SG_ 1367 EKD_Daempfer_A "im Fehlerspeicher der Dämpferregelung gibt es einen aktuellen (statischen oder sporadischen) Kundendienst-Fehlerspeichereintrag";
CM_ SG_ 1367 EKD_Quersperre "Bei gesetztem Bit ist mindestens ein Kundendienstfehler eingetragen";
CM_ SG_ 1367 EKD_Motor_Slave_A "Info für Diagnose; bei gesetztem Bit befindet sich mindestens ein Kundendienstfehler im Fehlerspeicher des Motorslave";
CM_ SG_ 1367 EKD_SWA_A "Bei gesetztem Bit ist mindestens ein Kundendienstfehler eingetragen";
CM_ SG_ 1367 EKD_LDW_A "Bei gesetztem Bit ist mindestens ein Kundendienstfehler eingetragen";
CM_ SG_ 1367 EKD_RKA_Plus_A "1 = mindestens ein Kundendienstfehler im Steuergeraet vorhanden";
CM_ SG_ 1367 EKD_PLA_A "mindestens ein Fehler ist im Kundendienstfehlerspeicher eingetragen";
CM_ SG_ 1367 EKD_WFS_KBI "1 = mindestens ein Kundendienstfehler im Fehlerspeicher der Wegfahrsperre eingetragen";
CM_ SG_ 1367 EKD_Kombi_KBI "Bei gesetztem Bit ist mindestens ein Kundendienstfehler eingetragen
Fehlerspeichereintrag (Kombi 2)";
CM_ SG_ 1367 EKD_BSG_K "1 = mindestens ein Fehler ist im Kundendienstfehlerspeicher eingetragen";
CM_ SG_ 1367 EKD_KSG_K "1 = mindestens 1 Kundendienstfehler im Steuergeraet";
CM_ SG_ 1367 EKD_TSG_FT_K "1 = mindestens 1 Kundendienstfehler im Steuergeraet, Bei Audi z. Z. nur Memoryfehler";
CM_ SG_ 1367 EKD_TSG_BT_K "1 = mindestens 1 Kundendienstfehler im Steuergeraet, Bei Audi z. Z. nur Memoryfehler";
CM_ SG_ 1367 EKD_TSG_HL_K "1 = mindestens 1 Kundendienstfehler im Steuergeraet";
CM_ SG_ 1367 EKD_TSG_HR_K "1 = mindestens 1 Kundendienstfehler im Steuergeraet";
CM_ SG_ 1367 EKD_Memory_K "1 = mindestens 1 Kundendienstfehler ist im Steuergeraet eingetragen";
CM_ SG_ 1367 EKD_Dachmodul_K "Kundendienstfehler Dachmodul
";
CM_ SG_ 1367 EKD_Zentralelektrik_II_K "Kundendienstfehler Zentralelektrik 2 am CAN-Komfort";
CM_ SG_ 1367 EKD_RDK_K "1 = mindestens ein Kundendienstfehler im Steuergeraet vorhanden
";
CM_ SG_ 1367 EKD_SMLS_K "1 = mindestens ein Kundendienstfehler ist im Fehlerspeicher eingetragen";
CM_ SG_ 1367 EKD_Gateway_K "Bei gesetztem Bit ist mindestens ein KD-Fehler unter der Gateway Adresse abgelegt";
CM_ SG_ 1367 EKD_Clima_K "1 = mindestens 1 Kundendienstfehler ist im Fehlerspeicher eingetragen";
CM_ SG_ 1367 EKD_APS_K "1 = mindestens ein Fehler ist im Kundendienstfehlerspeicher eingetragen";
CM_ SG_ 1367 EKD_PTC_Heizung_K "1 = mindestens 1 Fehler im Kundendienstfehlerspeicher eingetragen";
CM_ SG_ 1367 EKD_Standhzg_K "1 = mindestens 1 Kundendienstfehler ist im Fehlerspeicher eingetragen";
CM_ SG_ 1367 EKD_VSG_K "1 = mindestens 1 Kundendienstfehlereintrag im Steuergeraet";
CM_ SG_ 1367 EKD_RSE_I "Kundendienstfehler Rearseatentertainment";
CM_ SG_ 1367 EKD_Wischer_K "Kundendienstfehler Wischermodul";
CM_ SG_ 1367 EKD_MDI_I "Fehlereintrag vorhanden";
CM_ SG_ 1367 EKD_AAG_K "1 = mindestens ein Kundendienstfehler ist eingetragen";
CM_ SG_ 1367 EKD_Mem_BF_K "1 = mindestens 1 Kundendienstfehler ist im Steuergeraet eingetragen";
CM_ SG_ 1367 EKD_Easy_Entry_VF "1 = mindestens 1 Kundendienstfehler ist im Steuergeraet eingetragen (statisch oder sporadisch)";
CM_ SG_ 1367 EKD_Easy_Entry_VB "1 = mindestens 1 Kundendienstfehler ist im Steuergeraet eingetragen (statisch oder sporadisch)";
CM_ SG_ 1367 EKD_Heckdeckel_K "Kundendienstfehlerspeichereintrag im Steuergeraet";
CM_ SG_ 1367 EKD_Rearview_I "Kundendienst-Fehler";
CM_ SG_ 1367 EKD_Sonderfahrzeug_SG_K "1 = mindestens 1 Kundendienstfehlereintrag im Steuergeraet";
CM_ SG_ 1367 EKD_Tastenmodul_I "Fehlereintrag vorhanden";
CM_ SG_ 1367 EKD_Kompass_I "Kundendienstfehlerspeicher vorhanden";
CM_ SG_ 1367 EKD_WFS_K "1 = Mindestens ein Kundendienstfehler im Fehlerspeicher WFS eingetragen
KD_Fehler fuer Wegfahrsperre";
CM_ SG_ 1367 EKD_GSM_Pager_I "Fehlereintrag vorhanden";
CM_ SG_ 1367 EKD_DSP_I "1 = mindestens ein Kundendienstfehler ist im Steuergeraet eingetragen";
CM_ SG_ 1367 EKD_DAB_I "Fehlereintrag vorhanden";
CM_ SG_ 1367 EKD_Telematik_I "Fehlereintrag vorhanden";
CM_ SG_ 1367 EKD_Navigation_I "Fehlereintrag vorhanden";
CM_ SG_ 1367 EKD_TV_Tuner_I "1 = mindestens 1 Fehler im Kundendienstfehlerspeicher eingetragen";
CM_ SG_ 1367 EKD_Neigungsmodul "Kundendienstfehler Neigungsmodul am CAN-Infotainment";
CM_ SG_ 1367 EKD_Radio_I "Fehlereintrag vorhanden";
CM_ SG_ 1367 EKD_Telefon_I "1 = mindestens ein Kundendienstfehler ist im Steuergeraet eingetragen";
CM_ BO_ 1569 "PQ35";
CM_ SG_ 1569 KO1_Tankstop "Kombi hat Tankstop erkannt (Vorsicht: Wartezeit nach Klemme 15 ein berücksichtigen)
Flag wird nach 5 Sekunden bei fahrendem Fahrzeug gelöscht
";
CM_ SG_ 1569 KO1_Tankwarnlampe "Fahrer wird gewarnt (z. Zt. 7 Liter)";
CM_ SG_ 1569 KO1_WaschWasser "1 = Waschwasserstand zu niedrig
Waschwasser Warnung";
CM_ SG_ 1569 KO1_MH_Kontakt "1 = Motorhaube geoeffnet
Motorhaubenkontakt";
CM_ SG_ 1569 KO1_FT_geoeffnet "1 = Fahrertuer geoeffnet";
CM_ SG_ 1569 KO1_Handbremse "Umgesetzt bei VW, Audi B6, B7
Nicht bei Audi-Fahrzeugen mit EPB (Audi D3, C6)
Sonderfall PQ46: Hardware-Eingang von EPB zur Ansteuerung der BKL-Lampe, auch im Betriebsfall BKL-Blinken!
Sonderfall BY61x: Gespiegelt aus EPB-Botschaft CAN-Antrieb.";
CM_ SG_ 1569 KO1_AFL "Lichtschalterstellung auf AFL";
CM_ SG_ 1569 KO1_Klemme_L "Kombi hat seine Ladekontroll-Lampe eingeschaltet (Empfänger: z.Zt. Batman), nicht PQ35/46, nicht Audi D3/C6";
CM_ SG_ 1569 KO1_Standzeit "(0...36,4 h) Standzeit in 4 Sekunden Auflösung
mit diesen 15 Bits läßt sich eine Zeit bis 36 Stunden, 24 Minuten und 28 Sekunden darstellen
Der Standzeitzähler wird mit 'Klemme 15 aus' gestartet, er bleibt 2 Minuten vor einem Überlauf stehen, dieser alt";
CM_ SG_ 1569 KO1_Standzeit_Fehler "Reset Standzeit";
CM_ SG_ 1569 KO1_Tankinhalt "Restmenge 2 bzw. 2,5l nicht auflösbar
7FH ist Fehler. Bei Klemme 15 aus werden hier die zuletzt bei Kl. 15 ein ermittelten Werte gesendet.";
CM_ SG_ 1569 KO1_Tankwarnung "OBD-Schwelle (z. Zt. 15 %, applizierbar)
Tankwarnung";
CM_ SG_ 1569 KO1_WFS_Schluessel "0 = ungueltig, xxxx = Schluessel-Nr.
Schluesselinformation (s. Kombi_3)";
CM_ SG_ 1569 KO1_KD_Fehler_WFS "1 = mindestens ein Kundendienstfehler im Fehlerspeicher der Wegfahrsperre eingetragen";
CM_ SG_ 1569 KO1_Fernlicht "1 = Licht ein
Kl56a Fernlicht ein";
CM_ SG_ 1569 KO1_Freigabe_Zuheizer "Ein- u. Ausschalten des autom. Zuheizers via Einstellung im Kombi-Menue (statt Taste am KBT)
Einschalten des automatischen Zuheizers";
CM_ SG_ 1569 KO1_MFA_vorhanden "1 = MFA-Schalter verbaut
0 = kein MFA- Schalter
MFA Tasten vorhanden";
CM_ SG_ 1569 KO1_Bel_Displ "Display-Beleuchtung, Tastverhältnis in Prozent
Klemme 58d";
CM_ SG_ 1569 KO1_Sta_Displ "N.i.O. steht für nicht verfügbar oder Ersatzwert in Bit 6..0 wird vorgegeben (Standard)
VW Highline / Mini-DOT und Audi Kombis geben das mit dem Fototransister bewertete Signal aus
Fehlerstatus Kl. 58 d";
CM_ SG_ 1569 KO1_Lichtsensor "Lichtsensorzustand lt. Dimmungsspezifikation";
CM_ SG_ 1571 KO2_DCF "1 = DCF-Signal vorhanden";
CM_ SG_ 1571 KO2_Reset "1 = Reset der Uhr, Uebertragene Uhrzeit nicht gueltig";
CM_ SG_ 1571 KO2_24h_Anzeige "1 = Uhr zeigt 24 Stunden an
0 = Uhr zeigt nur 12 Stunden an, Fehler von +- 12 Stunden sind moeglich";
CM_ SG_ 1571 KO2_WeckzSH_OK "1= Die im Kombi gespeicherte Weckzeit ist erreicht. Bit wird nach 2-maliger Wiederholung wieder auf Null gesetzt.
Aktivierte Weckzeit fuer SH erreicht";
CM_ SG_ 1571 KO2_QV "Verstellmode Kombi";
CM_ SG_ 1571 KO2_Stunde "BCD-Codiert
Stunde
Dieses Signal ist die Kombi-Uhrzeit";
CM_ SG_ 1571 KO2_Minute "BCD-Codiert
Minute";
CM_ SG_ 1571 KO2_Sekunde "BCD-Codiert
Sekunde";
CM_ SG_ 1571 KO2_Tag "BCD-Codiert
Tag";
CM_ SG_ 1571 KO2_Monat "BCD-Codiert
Monat";
CM_ SG_ 1571 KO2_Jahrhundert "BCD-Codiert
Jahrhundert";
CM_ SG_ 1571 KO2_Jahr "BCD-Codiert
Jahr";
CM_ BO_ 1573 "CAN-Komfort, CAN-Dashboard";
CM_ SG_ 1573 KO3_SC_1 "Antwort auf Komfort-Radio-Request
Security Acces_Mode_2_Byte_1";
CM_ SG_ 1573 KO3_SC_2 "Timeout, siehe Radio-spec.
Security Acces_Mode_2_Byte_2";
CM_ SG_ 1573 KO3_SC_3 "Security Acces_Mode_2_Byte_3";
CM_ SG_ 1573 KO3_SC_4 "Security Acces_Mode_2_Byte_4";
CM_ SG_ 1573 KO3_Ziel "Adresse des anfragenden Teilnehmers
Zieladresse Security_Request";
CM_ SG_ 1575 KO4_Disp_Request "1 = neue Anfrage zum Refresh des Displays
Display_Request";
CM_ SG_ 1575 KO4_Disp_Ack "1 = Displaydaten erhalten
Display_Acknowledge";
CM_ SG_ 1575 KO4_Disp_Busy "1 = Display busy (wird derzeit gesetzt wenn Teldaten nicht angezeigt werden koennen Prio1 Warnung)";
CM_ SG_ 1575 KO4_code_no_ack "1 = Komfortcodierung des Radio nicht verstanden(derzeit nicht verwendet)
Komfort_Codierung_no_Ack";
CM_ SG_ 1575 KO4_Disp_Ft_auf "1 = Fahrertuer geoeffnet, fuer Coming_home Funktion fuer AFL";
CM_ SG_ 1575 KO4_User_field1 "Display-Manager-Information
SG im linken Anzeigesegment 1.Zeile von oben";
CM_ SG_ 1575 KO4_User_field2 "Aufteilung des Displays im Kombi siehe Kombispec. Highline Kombis
SG im rechten Anzeigesegment 1.Zeile von oben";
CM_ SG_ 1575 KO4_User_field3 "SG im linken Anzeigesegment 2.Zeile von oben";
CM_ SG_ 1575 KO4_User_field4 "SG im rechten Anzeigesegment 2.Zeile von oben";
CM_ SG_ 1575 KO4_User_field5 "SG im mittleren Anzeigesegment oben";
CM_ SG_ 1575 KO4_User_field6 "SG im mittleren Anzeigesegment unten";
CM_ SG_ 1575 KO4_User_field7 "SG im unteren Anzeigesegment";
CM_ SG_ 1479 KOM_Norden "Richtung Norden";
CM_ SG_ 1479 KOM_NordOst "Richtung NordOst";
CM_ SG_ 1479 KOM_Ost "Richtung Ost";
CM_ SG_ 1479 KOM_SuedOst "Richtung SüdOst";
CM_ SG_ 1479 KOM_Sued "Richtung Süd";
CM_ SG_ 1479 KOM_SuedWest "Richtung SüdWest";
CM_ SG_ 1479 KOM_West "Richtung West";
CM_ SG_ 1479 KOM_NordWest "Richtung NordWest";
CM_ SG_ 1479 KOM_Zone "Aktivierte Zone (1-15)
Richtung West";
CM_ SG_ 1479 KOM_Calibriert "Kompass ist kalibriert";
CM_ SG_ 1479 KOM_CALaktiv "Anzeige CAL im Display
Calibrierung aktiv";
CM_ SG_ 1479 KOM_Grad "Grad";
CM_ SG_ 1479 KOM_Stoerfeld "Magnetisches Störfeld zu stark";
CM_ SG_ 1479 KOM_ASIC_Fehler "ASIC Fehler";
CM_ SG_ 1479 KOM_Fehler3 "Fehler1";
CM_ SG_ 1479 KOM_Fehler4 "Fehler4";
CM_ SG_ 1479 KOM_Fehler5 "Fehler5";
CM_ SG_ 1479 KOM_Fehler6 "Fehler6";
CM_ SG_ 1479 KOM_Fehler7 "Fehler7";
CM_ SG_ 1479 KOM_KD_Fehler "Kundendienstfehlerspeicher vorhanden";
BA_DEF_ BO_  "GenMsgAutoGenDsp" ENUM  "No","Yes";
BA_DEF_ BO_  "GenMsgAutoGenSnd" ENUM  "No","Yes";
BA_DEF_ BO_  "GenMsgCycleTime" INT 0 65535;
BA_DEF_ BO_  "GenMsgCycleTimeFast" INT 0 65535;
BA_DEF_ BO_  "GenMsgDelayTime" INT 0 100000;
BA_DEF_ BO_  "GenMsgILSupport" ENUM  "No","Yes";
BA_DEF_ BO_  "GenMsgNrOfRepetition" INT 0 100;
BA_DEF_ BO_  "GenMsgSendType" ENUM  "Cyclic","not_used","not_used","not_used","not_used","not_used","not_used","IfActive","NoMsgSendType";
BA_DEF_ BO_  "GenMsgStartDelayTime" INT 0 100000;
BA_DEF_ BO_  "NmMessage" ENUM  "No","Yes";
BA_DEF_ BO_  "NmhMessage" ENUM  "No","Yes";
BA_DEF_ BO_  "VAGTP20_API" HEX 0 255;
BA_DEF_ BO_  "VAGTP20_DynConnection" ENUM  "No","Yes";
BA_DEF_ BO_  "VAGTP20_DynSetup" ENUM  "No","Yes";
BA_DEF_ BO_  "VAGTP20_StatConnection" ENUM  "No","Yes";
BA_DEF_ BO_  "DiagRequest" ENUM  "No","Yes";
BA_DEF_ BO_  "DiagResponse" ENUM  "No","Yes";
BA_DEF_ BO_  "DiagState" ENUM  "No","Yes";
BA_DEF_ SG_  "GenSigAutoGenDsp" ENUM  "No","Yes";
BA_DEF_ SG_  "GenSigAutoGenSnd" ENUM  "No","Yes";
BA_DEF_ SG_  "GenSigEnvVarType" ENUM  "int","float","undef";
BA_DEF_ SG_  "GenSigInactiveValue" INT -2147483648 2147483647;
BA_DEF_ SG_  "GenSigSendType" ENUM  "Cyclic","OnWrite","OnWriteWithRepetition","OnChange","OnChangeWithRepetition","IfActive","IfActiveWithRepetition","NoSigSendType","OnChangeAndIfActive","OnChangeAndIfActiveWithRepetition";
BA_DEF_ SG_  "GenSigStartValue" INT -2147483648 2147483647;
BA_DEF_ SG_  "NWM-WakeupAllowed" ENUM  "No","Yes";
BA_DEF_ SG_  "GenSigFuncType" ENUM  "NoFunction","MsgCounter","CRC-8","XOR","XOR-2","DatedBit","SW-Kl15","CHK","Constant","Protocol";
BA_DEF_ SG_  "GenSigSwitchedByIgnition" ENUM  "No","Yes";
BA_DEF_ SG_  "Fehlerwert" HEX 0 2147483647;
BA_DEF_DEF_  "GenMsgAutoGenDsp" "Yes";
BA_DEF_DEF_  "GenMsgAutoGenSnd" "Yes";
BA_DEF_DEF_  "GenMsgCycleTime" 0;
BA_DEF_DEF_  "GenMsgCycleTimeFast" 0;
BA_DEF_DEF_  "GenMsgDelayTime" 0;
BA_DEF_DEF_  "GenMsgILSupport" "No";
BA_DEF_DEF_  "GenMsgNrOfRepetition" 0;
BA_DEF_DEF_  "GenMsgSendType" "NoMsgSendType";
BA_DEF_DEF_  "GenMsgStartDelayTime" 0;
BA_DEF_DEF_  "NmMessage" "No";
BA_DEF_DEF_  "NmhMessage" "No";
BA_DEF_DEF_  "VAGTP20_API" 0;
BA_DEF_DEF_  "VAGTP20_DynConnection" "No";
BA_DEF_DEF_  "VAGTP20_DynSetup" "No";
BA_DEF_DEF_  "VAGTP20_StatConnection" "No";
BA_DEF_DEF_  "DiagRequest" "No";
BA_DEF_DEF_  "DiagResponse" "No";
BA_DEF_DEF_  "DiagState" "No";
BA_DEF_DEF_  "GenSigAutoGenDsp" "No";
BA_DEF_DEF_  "GenSigAutoGenSnd" "No";
BA_DEF_DEF_  "GenSigEnvVarType" "undef";
BA_DEF_DEF_  "GenSigInactiveValue" 0;
BA_DEF_DEF_  "GenSigSendType" "NoSigSendType";
BA_DEF_DEF_  "GenSigStartValue" 0;
BA_DEF_DEF_  "NWM-WakeupAllowed" "No";
BA_DEF_DEF_  "GenSigFuncType" "NoFunction";
BA_DEF_DEF_  "GenSigSwitchedByIgnition" "No";
BA_DEF_DEF_  "Fehlerwert" 0;
BA_ "GenMsgCycleTime" BO_ 995 800;
BA_ "GenMsgDelayTime" BO_ 995 80;
BA_ "GenMsgILSupport" BO_ 995 1;
BA_ "GenMsgSendType" BO_ 995 0;
BA_ "GenMsgCycleTime" BO_ 1505 200;
BA_ "GenMsgDelayTime" BO_ 1505 20;
BA_ "GenMsgILSupport" BO_ 1505 1;
BA_ "GenMsgSendType" BO_ 1505 0;
BA_ "GenMsgCycleTime" BO_ 1507 400;
BA_ "GenMsgDelayTime" BO_ 1507 40;
BA_ "GenMsgILSupport" BO_ 1507 1;
BA_ "GenMsgSendType" BO_ 1507 0;
BA_ "GenMsgCycleTime" BO_ 1634 1000;
BA_ "GenMsgDelayTime" BO_ 1634 100;
BA_ "GenMsgILSupport" BO_ 1634 1;
BA_ "GenMsgSendType" BO_ 1634 0;
BA_ "GenMsgCycleTime" BO_ 1629 1000;
BA_ "GenMsgILSupport" BO_ 1629 1;
BA_ "GenMsgSendType" BO_ 1629 0;
BA_ "GenMsgCycleTime" BO_ 1589 200;
BA_ "GenMsgDelayTime" BO_ 1589 25;
BA_ "GenMsgILSupport" BO_ 1589 1;
BA_ "GenMsgSendType" BO_ 1589 0;
BA_ "GenMsgCycleTime" BO_ 1583 200;
BA_ "GenMsgDelayTime" BO_ 1583 20;
BA_ "GenMsgILSupport" BO_ 1583 1;
BA_ "GenMsgSendType" BO_ 1583 0;
BA_ "GenMsgCycleTime" BO_ 1391 1000;
BA_ "GenMsgDelayTime" BO_ 1391 100;
BA_ "GenMsgILSupport" BO_ 1391 1;
BA_ "GenMsgSendType" BO_ 1391 0;
BA_ "GenMsgCycleTime" BO_ 1550 1000;
BA_ "GenMsgDelayTime" BO_ 1550 100;
BA_ "GenMsgILSupport" BO_ 1550 1;
BA_ "GenMsgSendType" BO_ 1550 0;
BA_ "GenMsgCycleTimeFast" BO_ 1471 1000;
BA_ "GenMsgDelayTime" BO_ 1471 30;
BA_ "GenMsgILSupport" BO_ 1471 1;
BA_ "GenMsgNrOfRepetition" BO_ 1471 5;
BA_ "GenMsgCycleTime" BO_ 1631 200;
BA_ "GenMsgILSupport" BO_ 1631 1;
BA_ "GenMsgSendType" BO_ 1631 0;
BA_ "GenMsgCycleTime" BO_ 849 100;
BA_ "GenMsgCycleTime" BO_ 1619 500;
BA_ "GenMsgILSupport" BO_ 1619 1;
BA_ "GenMsgSendType" BO_ 1619 0;
BA_ "GenMsgCycleTime" BO_ 1487 1000;
BA_ "GenMsgILSupport" BO_ 1487 1;
BA_ "GenMsgSendType" BO_ 1487 0;
BA_ "GenMsgCycleTime" BO_ 857 100;
BA_ "GenMsgILSupport" BO_ 857 1;
BA_ "GenMsgSendType" BO_ 857 0;
BA_ "GenMsgCycleTime" BO_ 1315 200;
BA_ "GenMsgDelayTime" BO_ 1315 20;
BA_ "GenMsgILSupport" BO_ 1315 1;
BA_ "GenMsgSendType" BO_ 1315 0;
BA_ "GenMsgCycleTime" BO_ 1319 200;
BA_ "GenMsgILSupport" BO_ 1319 1;
BA_ "GenMsgSendType" BO_ 1319 0;
BA_ "GenMsgCycleTime" BO_ 859 100;
BA_ "GenMsgILSupport" BO_ 859 1;
BA_ "GenMsgSendType" BO_ 859 0;
BA_ "GenMsgCycleTime" BO_ 1367 500;
BA_ "GenMsgSendType" BO_ 1367 0;
BA_ "GenMsgCycleTime" BO_ 1569 100;
BA_ "GenMsgILSupport" BO_ 1569 1;
BA_ "GenMsgSendType" BO_ 1569 0;
BA_ "GenMsgCycleTime" BO_ 1571 1000;
BA_ "GenMsgILSupport" BO_ 1571 1;
BA_ "GenMsgSendType" BO_ 1571 0;
BA_ "GenMsgCycleTimeFast" BO_ 1573 100;
BA_ "GenMsgILSupport" BO_ 1573 1;
BA_ "GenMsgSendType" BO_ 1573 7;
BA_ "GenMsgCycleTime" BO_ 1575 500;
BA_ "GenMsgDelayTime" BO_ 1575 50;
BA_ "GenMsgILSupport" BO_ 1575 1;
BA_ "GenMsgSendType" BO_ 1575 0;
BA_ "GenMsgCycleTime" BO_ 1479 500;
BA_ "GenMsgILSupport" BO_ 1479 1;
BA_ "GenMsgSendType" BO_ 1479 0;
BA_ "GenSigAutoGenDsp" SG_ 995 CL2_Sonne_links 1;
BA_ "GenSigAutoGenSnd" SG_ 995 CL2_Sonne_links 1;
BA_ "GenSigSendType" SG_ 995 CL2_Sonne_links 0;
BA_ "GenSigStartValue" SG_ 995 CL2_Sonne_links 255;
BA_ "Fehlerwert" SG_ 995 CL2_Sonne_links 255;
BA_ "GenSigAutoGenDsp" SG_ 995 CL2_Sonne_rechts 1;
BA_ "GenSigAutoGenSnd" SG_ 995 CL2_Sonne_rechts 1;
BA_ "GenSigSendType" SG_ 995 CL2_Sonne_rechts 0;
BA_ "GenSigStartValue" SG_ 995 CL2_Sonne_rechts 255;
BA_ "Fehlerwert" SG_ 995 CL2_Sonne_rechts 255;
BA_ "GenSigAutoGenDsp" SG_ 995 CL2_InnenTemp 1;
BA_ "GenSigAutoGenSnd" SG_ 995 CL2_InnenTemp 1;
BA_ "GenSigSendType" SG_ 995 CL2_InnenTemp 0;
BA_ "GenSigStartValue" SG_ 995 CL2_InnenTemp 255;
BA_ "Fehlerwert" SG_ 995 CL2_InnenTemp 255;
BA_ "GenSigAutoGenDsp" SG_ 995 CL2_SitzH_links 1;
BA_ "GenSigAutoGenSnd" SG_ 995 CL2_SitzH_links 1;
BA_ "GenSigSendType" SG_ 995 CL2_SitzH_links 0;
BA_ "GenSigAutoGenDsp" SG_ 995 CL2_SitzH_rechts 1;
BA_ "GenSigAutoGenSnd" SG_ 995 CL2_SitzH_rechts 1;
BA_ "GenSigSendType" SG_ 995 CL2_SitzH_rechts 0;
BA_ "GenSigAutoGenDsp" SG_ 995 CL2_StSt_Info 1;
BA_ "GenSigAutoGenSnd" SG_ 995 CL2_StSt_Info 1;
BA_ "GenSigSendType" SG_ 995 CL2_StSt_Info 3;
BA_ "GenSigAutoGenDsp" SG_ 995 CL2_SH 1;
BA_ "GenSigAutoGenSnd" SG_ 995 CL2_SH 1;
BA_ "GenSigSendType" SG_ 995 CL2_SH 3;
BA_ "GenSigAutoGenDsp" SG_ 995 CL2_SL_LED 1;
BA_ "GenSigAutoGenSnd" SG_ 995 CL2_SL_LED 1;
BA_ "GenSigSendType" SG_ 995 CL2_SL_LED 3;
BA_ "GenSigAutoGenDsp" SG_ 995 CL2_Geblaese_plus 1;
BA_ "GenSigAutoGenSnd" SG_ 995 CL2_Geblaese_plus 1;
BA_ "GenSigSendType" SG_ 995 CL2_Geblaese_plus 3;
BA_ "GenSigAutoGenDsp" SG_ 995 CL2_Umluft_Taste 1;
BA_ "GenSigAutoGenSnd" SG_ 995 CL2_Umluft_Taste 1;
BA_ "GenSigSendType" SG_ 995 CL2_Umluft_Taste 3;
BA_ "GenSigAutoGenDsp" SG_ 995 CL2_Solltemperatur 1;
BA_ "GenSigAutoGenSnd" SG_ 995 CL2_Solltemperatur 1;
BA_ "GenSigSendType" SG_ 995 CL2_Solltemperatur 3;
BA_ "GenSigStartValue" SG_ 995 CL2_Solltemperatur 254;
BA_ "Fehlerwert" SG_ 995 CL2_Solltemperatur 255;
BA_ "GenSigAutoGenDsp" SG_ 995 CL2_Vorgabe_KWTemp 1;
BA_ "GenSigAutoGenSnd" SG_ 995 CL2_Vorgabe_KWTemp 1;
BA_ "GenSigSendType" SG_ 995 CL2_Vorgabe_KWTemp 3;
BA_ "GenSigStartValue" SG_ 995 CL2_Vorgabe_KWTemp 255;
BA_ "Fehlerwert" SG_ 995 CL2_Vorgabe_KWTemp 255;
BA_ "GenSigAutoGenDsp" SG_ 1505 CL3_Umluft 1;
BA_ "GenSigAutoGenSnd" SG_ 1505 CL3_Umluft 1;
BA_ "GenSigSendType" SG_ 1505 CL3_Umluft 3;
BA_ "GenSigAutoGenDsp" SG_ 1505 CL3_Restwaerme 1;
BA_ "GenSigAutoGenSnd" SG_ 1505 CL3_Restwaerme 1;
BA_ "GenSigSendType" SG_ 1505 CL3_Restwaerme 3;
BA_ "GenSigAutoGenDsp" SG_ 1505 CL3_Mono 1;
BA_ "GenSigAutoGenSnd" SG_ 1505 CL3_Mono 1;
BA_ "GenSigSendType" SG_ 1505 CL3_Mono 3;
BA_ "GenSigAutoGenDsp" SG_ 1505 CL3_Luftguetesensor 1;
BA_ "GenSigAutoGenSnd" SG_ 1505 CL3_Luftguetesensor 1;
BA_ "GenSigSendType" SG_ 1505 CL3_Luftguetesensor 3;
BA_ "GenSigAutoGenDsp" SG_ 1505 CL3_Defrost 1;
BA_ "GenSigAutoGenSnd" SG_ 1505 CL3_Defrost 1;
BA_ "GenSigSendType" SG_ 1505 CL3_Defrost 3;
BA_ "GenSigAutoGenDsp" SG_ 1505 CL3_Solarbelueftung 1;
BA_ "GenSigAutoGenSnd" SG_ 1505 CL3_Solarbelueftung 1;
BA_ "GenSigSendType" SG_ 1505 CL3_Solarbelueftung 3;
BA_ "GenSigAutoGenDsp" SG_ 1505 CL3_Econ 1;
BA_ "GenSigAutoGenSnd" SG_ 1505 CL3_Econ 1;
BA_ "GenSigSendType" SG_ 1505 CL3_Econ 3;
BA_ "GenSigAutoGenDsp" SG_ 1505 CL3_Klima_Hauptschalter 1;
BA_ "GenSigAutoGenSnd" SG_ 1505 CL3_Klima_Hauptschalter 1;
BA_ "GenSigSendType" SG_ 1505 CL3_Klima_Hauptschalter 3;
BA_ "GenSigAutoGenDsp" SG_ 1505 CL3_KlimaOffFond 1;
BA_ "GenSigAutoGenSnd" SG_ 1505 CL3_KlimaOffFond 1;
BA_ "GenSigSendType" SG_ 1505 CL3_KlimaOffFond 3;
BA_ "GenSigAutoGenDsp" SG_ 1505 CL3_Bedien_mgl 1;
BA_ "GenSigAutoGenSnd" SG_ 1505 CL3_Bedien_mgl 1;
BA_ "GenSigSendType" SG_ 1505 CL3_Bedien_mgl 3;
BA_ "GenSigAutoGenDsp" SG_ 1505 CL3_nAkt_Uml_Fond 1;
BA_ "GenSigAutoGenSnd" SG_ 1505 CL3_nAkt_Uml_Fond 1;
BA_ "GenSigSendType" SG_ 1505 CL3_nAkt_Uml_Fond 3;
BA_ "GenSigAutoGenDsp" SG_ 1505 CL3_nAkt_Umluft 1;
BA_ "GenSigAutoGenSnd" SG_ 1505 CL3_nAkt_Umluft 1;
BA_ "GenSigSendType" SG_ 1505 CL3_nAkt_Umluft 3;
BA_ "GenSigAutoGenDsp" SG_ 1505 CL3_nAkt_Econ 1;
BA_ "GenSigAutoGenSnd" SG_ 1505 CL3_nAkt_Econ 1;
BA_ "GenSigSendType" SG_ 1505 CL3_nAkt_Econ 3;
BA_ "GenSigAutoGenDsp" SG_ 1505 CL3_nAkt_AQS 1;
BA_ "GenSigAutoGenSnd" SG_ 1505 CL3_nAkt_AQS 1;
BA_ "GenSigSendType" SG_ 1505 CL3_nAkt_AQS 3;
BA_ "GenSigAutoGenDsp" SG_ 1505 CL3_nAkt_Restwaerme 1;
BA_ "GenSigAutoGenSnd" SG_ 1505 CL3_nAkt_Restwaerme 1;
BA_ "GenSigSendType" SG_ 1505 CL3_nAkt_Restwaerme 3;
BA_ "GenSigAutoGenDsp" SG_ 1505 CL3_Hzg_LF_Sens 1;
BA_ "GenSigAutoGenSnd" SG_ 1505 CL3_Hzg_LF_Sens 1;
BA_ "GenSigSendType" SG_ 1505 CL3_Hzg_LF_Sens 3;
BA_ "GenSigAutoGenDsp" SG_ 1505 CL3_V_Qtg_Zaehler 1;
BA_ "GenSigAutoGenSnd" SG_ 1505 CL3_V_Qtg_Zaehler 1;
BA_ "GenSigSendType" SG_ 1505 CL3_V_Qtg_Zaehler 3;
BA_ "GenSigAutoGenDsp" SG_ 1505 CL3_H_Qtg_Zaehler 1;
BA_ "GenSigAutoGenSnd" SG_ 1505 CL3_H_Qtg_Zaehler 1;
BA_ "GenSigSendType" SG_ 1505 CL3_H_Qtg_Zaehler 3;
BA_ "GenSigAutoGenDsp" SG_ 1505 CL3_StandHzg 1;
BA_ "GenSigAutoGenSnd" SG_ 1505 CL3_StandHzg 1;
BA_ "GenSigSendType" SG_ 1505 CL3_StandHzg 3;
BA_ "GenSigAutoGenDsp" SG_ 1505 CL3_Anstr_VL_Kopf 1;
BA_ "GenSigAutoGenSnd" SG_ 1505 CL3_Anstr_VL_Kopf 1;
BA_ "GenSigSendType" SG_ 1505 CL3_Anstr_VL_Kopf 3;
BA_ "GenSigAutoGenDsp" SG_ 1505 CL3_Anstr_VL_Mann 1;
BA_ "GenSigAutoGenSnd" SG_ 1505 CL3_Anstr_VL_Mann 1;
BA_ "GenSigSendType" SG_ 1505 CL3_Anstr_VL_Mann 3;
BA_ "GenSigAutoGenDsp" SG_ 1505 CL3_Anstr_VL_Fuss 1;
BA_ "GenSigAutoGenSnd" SG_ 1505 CL3_Anstr_VL_Fuss 1;
BA_ "GenSigSendType" SG_ 1505 CL3_Anstr_VL_Fuss 3;
BA_ "GenSigAutoGenDsp" SG_ 1505 CL3_Anstr_VL_Automatik 1;
BA_ "GenSigAutoGenSnd" SG_ 1505 CL3_Anstr_VL_Automatik 1;
BA_ "GenSigSendType" SG_ 1505 CL3_Anstr_VL_Automatik 3;
BA_ "GenSigAutoGenDsp" SG_ 1505 CL3_Anstr_VR_Kopf 1;
BA_ "GenSigAutoGenSnd" SG_ 1505 CL3_Anstr_VR_Kopf 1;
BA_ "GenSigSendType" SG_ 1505 CL3_Anstr_VR_Kopf 3;
BA_ "GenSigAutoGenDsp" SG_ 1505 CL3_Anstr_VR_Mann 1;
BA_ "GenSigAutoGenSnd" SG_ 1505 CL3_Anstr_VR_Mann 1;
BA_ "GenSigSendType" SG_ 1505 CL3_Anstr_VR_Mann 3;
BA_ "GenSigAutoGenDsp" SG_ 1505 CL3_Anstr_VR_Fuss 1;
BA_ "GenSigAutoGenSnd" SG_ 1505 CL3_Anstr_VR_Fuss 1;
BA_ "GenSigSendType" SG_ 1505 CL3_Anstr_VR_Fuss 3;
BA_ "GenSigAutoGenDsp" SG_ 1505 CL3_Anstr_VR_Automatik 1;
BA_ "GenSigAutoGenSnd" SG_ 1505 CL3_Anstr_VR_Automatik 1;
BA_ "GenSigSendType" SG_ 1505 CL3_Anstr_VR_Automatik 3;
BA_ "GenSigAutoGenDsp" SG_ 1505 CL3_Anstr_HL_Kopf 1;
BA_ "GenSigAutoGenSnd" SG_ 1505 CL3_Anstr_HL_Kopf 1;
BA_ "GenSigSendType" SG_ 1505 CL3_Anstr_HL_Kopf 3;
BA_ "GenSigAutoGenDsp" SG_ 1505 CL3_Anstr_HL_Mann 1;
BA_ "GenSigAutoGenSnd" SG_ 1505 CL3_Anstr_HL_Mann 1;
BA_ "GenSigSendType" SG_ 1505 CL3_Anstr_HL_Mann 3;
BA_ "GenSigAutoGenDsp" SG_ 1505 CL3_Anstr_HL_Fuss 1;
BA_ "GenSigAutoGenSnd" SG_ 1505 CL3_Anstr_HL_Fuss 1;
BA_ "GenSigSendType" SG_ 1505 CL3_Anstr_HL_Fuss 3;
BA_ "GenSigAutoGenDsp" SG_ 1505 CL3_Anstr_HL_Automatik 1;
BA_ "GenSigAutoGenSnd" SG_ 1505 CL3_Anstr_HL_Automatik 1;
BA_ "GenSigSendType" SG_ 1505 CL3_Anstr_HL_Automatik 3;
BA_ "GenSigAutoGenDsp" SG_ 1505 CL3_Anstr_HR_Kopf 1;
BA_ "GenSigAutoGenSnd" SG_ 1505 CL3_Anstr_HR_Kopf 1;
BA_ "GenSigSendType" SG_ 1505 CL3_Anstr_HR_Kopf 3;
BA_ "GenSigAutoGenDsp" SG_ 1505 CL3_Anstr_HR_Mann 1;
BA_ "GenSigAutoGenSnd" SG_ 1505 CL3_Anstr_HR_Mann 1;
BA_ "GenSigSendType" SG_ 1505 CL3_Anstr_HR_Mann 3;
BA_ "GenSigAutoGenDsp" SG_ 1505 CL3_Anstr_HR_Fuss 1;
BA_ "GenSigAutoGenSnd" SG_ 1505 CL3_Anstr_HR_Fuss 1;
BA_ "GenSigSendType" SG_ 1505 CL3_Anstr_HR_Fuss 3;
BA_ "GenSigAutoGenDsp" SG_ 1505 CL3_Anstr_HR_Automatik 1;
BA_ "GenSigAutoGenSnd" SG_ 1505 CL3_Anstr_HR_Automatik 1;
BA_ "GenSigSendType" SG_ 1505 CL3_Anstr_HR_Automatik 3;
BA_ "GenSigAutoGenDsp" SG_ 1505 CL3_FT_Defrost 1;
BA_ "GenSigAutoGenSnd" SG_ 1505 CL3_FT_Defrost 1;
BA_ "GenSigSendType" SG_ 1505 CL3_FT_Defrost 3;
BA_ "GenSigAutoGenDsp" SG_ 1505 CL3_BT_Defrost 1;
BA_ "GenSigAutoGenSnd" SG_ 1505 CL3_BT_Defrost 1;
BA_ "GenSigSendType" SG_ 1505 CL3_BT_Defrost 3;
BA_ "GenSigAutoGenDsp" SG_ 1505 CL3_StandLftg 1;
BA_ "GenSigAutoGenSnd" SG_ 1505 CL3_StandLftg 1;
BA_ "GenSigSendType" SG_ 1505 CL3_StandLftg 3;
BA_ "GenSigAutoGenDsp" SG_ 1505 CL3_SH_ein_KDWunsch 1;
BA_ "GenSigAutoGenSnd" SG_ 1505 CL3_SH_ein_KDWunsch 1;
BA_ "GenSigSendType" SG_ 1505 CL3_SH_ein_KDWunsch 3;
BA_ "GenSigAutoGenDsp" SG_ 1505 CL3_SH_Wasserpumpe 1;
BA_ "GenSigAutoGenSnd" SG_ 1505 CL3_SH_Wasserpumpe 1;
BA_ "GenSigSendType" SG_ 1505 CL3_SH_Wasserpumpe 3;
BA_ "GenSigAutoGenDsp" SG_ 1505 CL3_ein_Lenkrad_Hzg 1;
BA_ "GenSigAutoGenSnd" SG_ 1505 CL3_ein_Lenkrad_Hzg 1;
BA_ "GenSigSendType" SG_ 1505 CL3_ein_Lenkrad_Hzg 3;
BA_ "GenSigAutoGenDsp" SG_ 1505 CL3_Gegendimmung 1;
BA_ "GenSigAutoGenSnd" SG_ 1505 CL3_Gegendimmung 1;
BA_ "GenSigSendType" SG_ 1505 CL3_Gegendimmung 3;
BA_ "GenSigAutoGenDsp" SG_ 1507 CL4_VL_Ist_Temp 1;
BA_ "GenSigAutoGenSnd" SG_ 1507 CL4_VL_Ist_Temp 1;
BA_ "GenSigSendType" SG_ 1507 CL4_VL_Ist_Temp 3;
BA_ "Fehlerwert" SG_ 1507 CL4_VL_Ist_Temp 255;
BA_ "GenSigAutoGenDsp" SG_ 1507 CL4_VR_Ist_Temp 1;
BA_ "GenSigAutoGenSnd" SG_ 1507 CL4_VR_Ist_Temp 1;
BA_ "GenSigSendType" SG_ 1507 CL4_VR_Ist_Temp 3;
BA_ "GenSigAutoGenDsp" SG_ 1507 CL4_HL_Ist_Temp 1;
BA_ "GenSigAutoGenSnd" SG_ 1507 CL4_HL_Ist_Temp 1;
BA_ "GenSigSendType" SG_ 1507 CL4_HL_Ist_Temp 3;
BA_ "GenSigAutoGenDsp" SG_ 1507 CL4_HR_Ist_Temp 1;
BA_ "GenSigAutoGenSnd" SG_ 1507 CL4_HR_Ist_Temp 1;
BA_ "GenSigSendType" SG_ 1507 CL4_HR_Ist_Temp 3;
BA_ "GenSigAutoGenDsp" SG_ 1507 CL4_V_Gebl_Leistung 1;
BA_ "GenSigAutoGenSnd" SG_ 1507 CL4_V_Gebl_Leistung 1;
BA_ "GenSigSendType" SG_ 1507 CL4_V_Gebl_Leistung 3;
BA_ "GenSigAutoGenDsp" SG_ 1507 CL4_H_Gebl_Leistung 1;
BA_ "GenSigAutoGenSnd" SG_ 1507 CL4_H_Gebl_Leistung 1;
BA_ "GenSigSendType" SG_ 1507 CL4_H_Gebl_Leistung 3;
BA_ "GenSigAutoGenDsp" SG_ 1507 CL4_UG_Tempbereich 1;
BA_ "GenSigAutoGenSnd" SG_ 1507 CL4_UG_Tempbereich 1;
BA_ "GenSigSendType" SG_ 1507 CL4_UG_Tempbereich 3;
BA_ "GenSigAutoGenDsp" SG_ 1507 CL4_Deltatemp 1;
BA_ "GenSigAutoGenSnd" SG_ 1507 CL4_Deltatemp 1;
BA_ "GenSigSendType" SG_ 1507 CL4_Deltatemp 3;
BA_ "GenSigAutoGenDsp" SG_ 1507 CL4_WSS_Temp 1;
BA_ "GenSigAutoGenSnd" SG_ 1507 CL4_WSS_Temp 1;
BA_ "GenSigSendType" SG_ 1507 CL4_WSS_Temp 3;
BA_ "GenSigAutoGenDsp" SG_ 1507 CL4_V_Qtg_Zaehler 1;
BA_ "GenSigAutoGenSnd" SG_ 1507 CL4_V_Qtg_Zaehler 1;
BA_ "GenSigSendType" SG_ 1507 CL4_V_Qtg_Zaehler 3;
BA_ "GenSigAutoGenDsp" SG_ 1507 CL4_V_Gebl_AutoMan 1;
BA_ "GenSigAutoGenSnd" SG_ 1507 CL4_V_Gebl_AutoMan 1;
BA_ "GenSigSendType" SG_ 1507 CL4_V_Gebl_AutoMan 3;
BA_ "GenSigAutoGenDsp" SG_ 1507 CL4_H_Qtg_Zaehler 1;
BA_ "GenSigAutoGenSnd" SG_ 1507 CL4_H_Qtg_Zaehler 1;
BA_ "GenSigSendType" SG_ 1507 CL4_H_Qtg_Zaehler 3;
BA_ "GenSigAutoGenDsp" SG_ 1507 CL4_H_Gebl_AutoMan 1;
BA_ "GenSigAutoGenSnd" SG_ 1507 CL4_H_Gebl_AutoMan 1;
BA_ "GenSigSendType" SG_ 1507 CL4_H_Gebl_AutoMan 3;
BA_ "GenSigAutoGenDsp" SG_ 1634 DA1_DAB_On 1;
BA_ "GenSigAutoGenSnd" SG_ 1634 DA1_DAB_On 1;
BA_ "GenSigSendType" SG_ 1634 DA1_DAB_On 3;
BA_ "GenSigAutoGenDsp" SG_ 1634 DA1_DAB_mute 1;
BA_ "GenSigAutoGenSnd" SG_ 1634 DA1_DAB_mute 1;
BA_ "GenSigSendType" SG_ 1634 DA1_DAB_mute 3;
BA_ "GenSigAutoGenDsp" SG_ 1634 DA1_DAB_Error_flag 1;
BA_ "GenSigAutoGenSnd" SG_ 1634 DA1_DAB_Error_flag 1;
BA_ "GenSigSendType" SG_ 1634 DA1_DAB_Error_flag 3;
BA_ "GenSigAutoGenDsp" SG_ 1634 DA1_DAB_Mode 1;
BA_ "GenSigAutoGenSnd" SG_ 1634 DA1_DAB_Mode 1;
BA_ "GenSigSendType" SG_ 1634 DA1_DAB_Mode 3;
BA_ "GenSigAutoGenDsp" SG_ 1634 DA1_DAB_Para1 1;
BA_ "GenSigAutoGenSnd" SG_ 1634 DA1_DAB_Para1 1;
BA_ "GenSigSendType" SG_ 1634 DA1_DAB_Para1 3;
BA_ "GenSigAutoGenDsp" SG_ 1634 DA1_DAB_Para2 1;
BA_ "GenSigAutoGenSnd" SG_ 1634 DA1_DAB_Para2 1;
BA_ "GenSigSendType" SG_ 1634 DA1_DAB_Para2 3;
BA_ "GenSigAutoGenDsp" SG_ 1634 DA1_DAB_Para3 1;
BA_ "GenSigAutoGenSnd" SG_ 1634 DA1_DAB_Para3 1;
BA_ "GenSigSendType" SG_ 1634 DA1_DAB_Para3 3;
BA_ "GenSigAutoGenDsp" SG_ 1634 DA1_DAB_Para4 1;
BA_ "GenSigAutoGenSnd" SG_ 1634 DA1_DAB_Para4 1;
BA_ "GenSigSendType" SG_ 1634 DA1_DAB_Para4 3;
BA_ "GenSigAutoGenDsp" SG_ 1634 DA1_DAB_Para5 1;
BA_ "GenSigAutoGenSnd" SG_ 1634 DA1_DAB_Para5 1;
BA_ "GenSigSendType" SG_ 1634 DA1_DAB_Para5 3;
BA_ "GenSigAutoGenDsp" SG_ 1634 DA1_DAB_Para6 1;
BA_ "GenSigAutoGenSnd" SG_ 1634 DA1_DAB_Para6 1;
BA_ "GenSigSendType" SG_ 1634 DA1_DAB_Para6 3;
BA_ "GenSigAutoGenDsp" SG_ 1629 DN1_Verlernzaehler 1;
BA_ "GenSigAutoGenSnd" SG_ 1629 DN1_Verlernzaehler 1;
BA_ "GenSigSendType" SG_ 1629 DN1_Verlernzaehler 0;
BA_ "Fehlerwert" SG_ 1629 DN1_Verlernzaehler 255;
BA_ "GenSigAutoGenDsp" SG_ 1629 DN1_KM_Stand 1;
BA_ "GenSigAutoGenSnd" SG_ 1629 DN1_KM_Stand 1;
BA_ "GenSigSendType" SG_ 1629 DN1_KM_Stand 0;
BA_ "GenSigAutoGenDsp" SG_ 1629 DN1_Jahr 1;
BA_ "GenSigAutoGenSnd" SG_ 1629 DN1_Jahr 1;
BA_ "GenSigSendType" SG_ 1629 DN1_Jahr 0;
BA_ "GenSigAutoGenDsp" SG_ 1629 DN1_Monat 1;
BA_ "GenSigAutoGenSnd" SG_ 1629 DN1_Monat 1;
BA_ "GenSigSendType" SG_ 1629 DN1_Monat 0;
BA_ "GenSigAutoGenDsp" SG_ 1629 DN1_Tag 1;
BA_ "GenSigAutoGenSnd" SG_ 1629 DN1_Tag 1;
BA_ "GenSigSendType" SG_ 1629 DN1_Tag 0;
BA_ "GenSigAutoGenDsp" SG_ 1629 DN1_Stunde 1;
BA_ "GenSigAutoGenSnd" SG_ 1629 DN1_Stunde 1;
BA_ "GenSigSendType" SG_ 1629 DN1_Stunde 0;
BA_ "GenSigAutoGenDsp" SG_ 1629 DN1_Minute 1;
BA_ "GenSigAutoGenSnd" SG_ 1629 DN1_Minute 1;
BA_ "GenSigSendType" SG_ 1629 DN1_Minute 0;
BA_ "GenSigAutoGenDsp" SG_ 1629 DN1_Sekunde 1;
BA_ "GenSigAutoGenSnd" SG_ 1629 DN1_Sekunde 1;
BA_ "GenSigSendType" SG_ 1629 DN1_Sekunde 0;
BA_ "GenSigAutoGenDsp" SG_ 1629 DN1_alt_Kilometerstand 1;
BA_ "GenSigAutoGenSnd" SG_ 1629 DN1_alt_Kilometerstand 1;
BA_ "GenSigSendType" SG_ 1629 DN1_alt_Kilometerstand 0;
BA_ "GenSigStartValue" SG_ 1629 DN1_alt_Kilometerstand 1;
BA_ "GenSigFuncType" SG_ 1629 DN1_alt_Kilometerstand 5;
BA_ "GenSigAutoGenDsp" SG_ 1629 DN1_alt_Zeit 1;
BA_ "GenSigAutoGenSnd" SG_ 1629 DN1_alt_Zeit 1;
BA_ "GenSigSendType" SG_ 1629 DN1_alt_Zeit 0;
BA_ "GenSigStartValue" SG_ 1629 DN1_alt_Zeit 1;
BA_ "GenSigFuncType" SG_ 1629 DN1_alt_Zeit 5;
BA_ "GenSigAutoGenDsp" SG_ 1589 DI1_Display 1;
BA_ "GenSigAutoGenSnd" SG_ 1589 DI1_Display 1;
BA_ "GenSigSendType" SG_ 1589 DI1_Display 3;
BA_ "Fehlerwert" SG_ 1589 DI1_Display 127;
BA_ "GenSigAutoGenDsp" SG_ 1589 DI1_Display_def 1;
BA_ "GenSigAutoGenSnd" SG_ 1589 DI1_Display_def 1;
BA_ "GenSigSendType" SG_ 1589 DI1_Display_def 3;
BA_ "GenSigAutoGenDsp" SG_ 1589 DI1_Schalter 1;
BA_ "GenSigAutoGenSnd" SG_ 1589 DI1_Schalter 1;
BA_ "GenSigSendType" SG_ 1589 DI1_Schalter 3;
BA_ "Fehlerwert" SG_ 1589 DI1_Schalter 127;
BA_ "GenSigAutoGenDsp" SG_ 1589 DI1_Schalter_def 1;
BA_ "GenSigAutoGenSnd" SG_ 1589 DI1_Schalter_def 1;
BA_ "GenSigSendType" SG_ 1589 DI1_Schalter_def 3;
BA_ "GenSigAutoGenDsp" SG_ 1589 DI1_Sensor 1;
BA_ "GenSigAutoGenSnd" SG_ 1589 DI1_Sensor 1;
BA_ "GenSigSendType" SG_ 1589 DI1_Sensor 3;
BA_ "GenSigStartValue" SG_ 1589 DI1_Sensor 254;
BA_ "Fehlerwert" SG_ 1589 DI1_Sensor 255;
BA_ "GenSigAutoGenDsp" SG_ 1583 DY1_Display_OK 1;
BA_ "GenSigAutoGenSnd" SG_ 1583 DY1_Display_OK 1;
BA_ "GenSigSendType" SG_ 1583 DY1_Display_OK 3;
BA_ "GenSigAutoGenDsp" SG_ 1583 DY1_Reset 1;
BA_ "GenSigAutoGenSnd" SG_ 1583 DY1_Reset 1;
BA_ "GenSigSendType" SG_ 1583 DY1_Reset 3;
BA_ "GenSigAutoGenDsp" SG_ 1583 DY1_Global_Reset 1;
BA_ "GenSigAutoGenSnd" SG_ 1583 DY1_Global_Reset 1;
BA_ "GenSigSendType" SG_ 1583 DY1_Global_Reset 3;
BA_ "GenSigAutoGenDsp" SG_ 1583 DY1_MFA_Down 1;
BA_ "GenSigAutoGenSnd" SG_ 1583 DY1_MFA_Down 1;
BA_ "GenSigSendType" SG_ 1583 DY1_MFA_Down 3;
BA_ "GenSigAutoGenDsp" SG_ 1583 DY1_MFA_Up 1;
BA_ "GenSigAutoGenSnd" SG_ 1583 DY1_MFA_Up 1;
BA_ "GenSigSendType" SG_ 1583 DY1_MFA_Up 3;
BA_ "GenSigAutoGenDsp" SG_ 1583 DY1_MFA_Reset 1;
BA_ "GenSigAutoGenSnd" SG_ 1583 DY1_MFA_Reset 1;
BA_ "GenSigSendType" SG_ 1583 DY1_MFA_Reset 3;
BA_ "GenSigAutoGenDsp" SG_ 1583 DY1_MFA_WippeLang 1;
BA_ "GenSigAutoGenSnd" SG_ 1583 DY1_MFA_WippeLang 1;
BA_ "GenSigSendType" SG_ 1583 DY1_MFA_WippeLang 3;
BA_ "GenSigAutoGenDsp" SG_ 1583 DY1_Bereich1 1;
BA_ "GenSigAutoGenSnd" SG_ 1583 DY1_Bereich1 1;
BA_ "GenSigSendType" SG_ 1583 DY1_Bereich1 3;
BA_ "GenSigAutoGenDsp" SG_ 1583 DY1_Bereich2 1;
BA_ "GenSigAutoGenSnd" SG_ 1583 DY1_Bereich2 1;
BA_ "GenSigSendType" SG_ 1583 DY1_Bereich2 3;
BA_ "GenSigAutoGenDsp" SG_ 1583 DY1_Bereich3 1;
BA_ "GenSigAutoGenSnd" SG_ 1583 DY1_Bereich3 1;
BA_ "GenSigSendType" SG_ 1583 DY1_Bereich3 3;
BA_ "GenSigAutoGenDsp" SG_ 1391 SD1_DSP_Type 1;
BA_ "GenSigAutoGenSnd" SG_ 1391 SD1_DSP_Type 1;
BA_ "GenSigSendType" SG_ 1391 SD1_DSP_Type 3;
BA_ "GenSigAutoGenDsp" SG_ 1391 SD1_Power_Mode 1;
BA_ "GenSigAutoGenSnd" SG_ 1391 SD1_Power_Mode 1;
BA_ "GenSigSendType" SG_ 1391 SD1_Power_Mode 3;
BA_ "GenSigAutoGenDsp" SG_ 1391 SD1_KD_Fehler 1;
BA_ "GenSigAutoGenSnd" SG_ 1391 SD1_KD_Fehler 1;
BA_ "GenSigSendType" SG_ 1391 SD1_KD_Fehler 3;
BA_ "GenSigAutoGenDsp" SG_ 1391 SD1_Ch1_Fading_in_process 1;
BA_ "GenSigAutoGenSnd" SG_ 1391 SD1_Ch1_Fading_in_process 1;
BA_ "GenSigSendType" SG_ 1391 SD1_Ch1_Fading_in_process 3;
BA_ "GenSigAutoGenDsp" SG_ 1391 SD1_Ch2_Fading_in_process 1;
BA_ "GenSigAutoGenSnd" SG_ 1391 SD1_Ch2_Fading_in_process 1;
BA_ "GenSigSendType" SG_ 1391 SD1_Ch2_Fading_in_process 3;
BA_ "GenSigAutoGenDsp" SG_ 1391 SD1_Ch3_Fading_in_process 1;
BA_ "GenSigAutoGenSnd" SG_ 1391 SD1_Ch3_Fading_in_process 1;
BA_ "GenSigSendType" SG_ 1391 SD1_Ch3_Fading_in_process 3;
BA_ "GenSigAutoGenDsp" SG_ 1391 SD1_hasVNC 1;
BA_ "GenSigAutoGenSnd" SG_ 1391 SD1_hasVNC 1;
BA_ "GenSigSendType" SG_ 1391 SD1_hasVNC 0;
BA_ "GenSigAutoGenDsp" SG_ 1391 SD1_hasSurround 1;
BA_ "GenSigAutoGenSnd" SG_ 1391 SD1_hasSurround 1;
BA_ "GenSigSendType" SG_ 1391 SD1_hasSurround 0;
BA_ "GenSigAutoGenDsp" SG_ 1391 SD1_VNC_Status 1;
BA_ "GenSigAutoGenSnd" SG_ 1391 SD1_VNC_Status 1;
BA_ "GenSigSendType" SG_ 1391 SD1_VNC_Status 0;
BA_ "GenSigAutoGenDsp" SG_ 1391 SD1_Surround_Status 1;
BA_ "GenSigAutoGenSnd" SG_ 1391 SD1_Surround_Status 1;
BA_ "GenSigSendType" SG_ 1391 SD1_Surround_Status 0;
BA_ "GenSigAutoGenDsp" SG_ 1550 EH1_Einh_Strck 1;
BA_ "GenSigAutoGenSnd" SG_ 1550 EH1_Einh_Strck 1;
BA_ "GenSigSendType" SG_ 1550 EH1_Einh_Strck 3;
BA_ "GenSigAutoGenDsp" SG_ 1550 EH1_Einh_Temp 1;
BA_ "GenSigAutoGenSnd" SG_ 1550 EH1_Einh_Temp 1;
BA_ "GenSigSendType" SG_ 1550 EH1_Einh_Temp 3;
BA_ "GenSigAutoGenDsp" SG_ 1550 EH1_Einh_Vol 1;
BA_ "GenSigAutoGenSnd" SG_ 1550 EH1_Einh_Vol 1;
BA_ "GenSigSendType" SG_ 1550 EH1_Einh_Vol 3;
BA_ "GenSigAutoGenDsp" SG_ 1550 EH1_Einh_Verbr 1;
BA_ "GenSigAutoGenSnd" SG_ 1550 EH1_Einh_Verbr 1;
BA_ "GenSigSendType" SG_ 1550 EH1_Einh_Verbr 3;
BA_ "GenSigAutoGenDsp" SG_ 1550 EH1_Einh_Druck 1;
BA_ "GenSigAutoGenSnd" SG_ 1550 EH1_Einh_Druck 1;
BA_ "GenSigSendType" SG_ 1550 EH1_Einh_Druck 3;
BA_ "GenSigAutoGenDsp" SG_ 1550 EH1_Datum_Anzeige 1;
BA_ "GenSigAutoGenSnd" SG_ 1550 EH1_Datum_Anzeige 1;
BA_ "GenSigSendType" SG_ 1550 EH1_Datum_Anzeige 3;
BA_ "GenSigAutoGenDsp" SG_ 1550 EH1_Uhr_Anzeige 1;
BA_ "GenSigAutoGenSnd" SG_ 1550 EH1_Uhr_Anzeige 1;
BA_ "GenSigSendType" SG_ 1550 EH1_Uhr_Anzeige 3;
BA_ "GenSigAutoGenDsp" SG_ 1550 EH1_Profil 1;
BA_ "GenSigAutoGenSnd" SG_ 1550 EH1_Profil 1;
BA_ "GenSigSendType" SG_ 1550 EH1_Profil 3;
BA_ "GenSigAutoGenDsp" SG_ 1550 EH1_Wochentag 1;
BA_ "GenSigAutoGenSnd" SG_ 1550 EH1_Wochentag 1;
BA_ "GenSigSendType" SG_ 1550 EH1_Wochentag 3;
BA_ "GenSigAutoGenDsp" SG_ 1550 EH1_Verstellung_Strck 1;
BA_ "GenSigAutoGenSnd" SG_ 1550 EH1_Verstellung_Strck 1;
BA_ "GenSigSendType" SG_ 1550 EH1_Verstellung_Strck 3;
BA_ "GenSigAutoGenDsp" SG_ 1471 MFL_Tastencode_1 1;
BA_ "GenSigAutoGenSnd" SG_ 1471 MFL_Tastencode_1 1;
BA_ "GenSigSendType" SG_ 1471 MFL_Tastencode_1 9;
BA_ "GenSigAutoGenDsp" SG_ 1471 MFL_Tastencode_2 1;
BA_ "GenSigAutoGenSnd" SG_ 1471 MFL_Tastencode_2 1;
BA_ "GenSigSendType" SG_ 1471 MFL_Tastencode_2 9;
BA_ "GenSigAutoGenDsp" SG_ 1471 MFL_Eventcode_1 1;
BA_ "GenSigAutoGenSnd" SG_ 1471 MFL_Eventcode_1 1;
BA_ "GenSigSendType" SG_ 1471 MFL_Eventcode_1 9;
BA_ "GenSigAutoGenDsp" SG_ 1471 MFL_Eventcode_2 1;
BA_ "GenSigAutoGenSnd" SG_ 1471 MFL_Eventcode_2 1;
BA_ "GenSigSendType" SG_ 1471 MFL_Eventcode_2 9;
BA_ "GenSigAutoGenDsp" SG_ 1471 MFL_Marke 1;
BA_ "GenSigAutoGenSnd" SG_ 1471 MFL_Marke 1;
BA_ "GenSigAutoGenDsp" SG_ 1471 MFL_Variante 1;
BA_ "GenSigAutoGenSnd" SG_ 1471 MFL_Variante 1;
BA_ "GenSigAutoGenDsp" SG_ 1631 FI1_MUX 1;
BA_ "GenSigAutoGenSnd" SG_ 1631 FI1_MUX 1;
BA_ "GenSigSendType" SG_ 1631 FI1_MUX 0;
BA_ "GenSigAutoGenDsp" SG_ 1631 FI1_Geheimnis_1 1;
BA_ "GenSigAutoGenSnd" SG_ 1631 FI1_Geheimnis_1 1;
BA_ "GenSigAutoGenDsp" SG_ 1631 FI1_VIN_4 1;
BA_ "GenSigAutoGenSnd" SG_ 1631 FI1_VIN_4 1;
BA_ "GenSigStartValue" SG_ 1631 FI1_VIN_4 88;
BA_ "GenSigAutoGenDsp" SG_ 1631 FI1_VIN_11 1;
BA_ "GenSigAutoGenSnd" SG_ 1631 FI1_VIN_11 1;
BA_ "GenSigStartValue" SG_ 1631 FI1_VIN_11 88;
BA_ "GenSigAutoGenDsp" SG_ 1631 FI1_Geheimnis_2 1;
BA_ "GenSigAutoGenSnd" SG_ 1631 FI1_Geheimnis_2 1;
BA_ "GenSigAutoGenDsp" SG_ 1631 FI1_VIN_5 1;
BA_ "GenSigAutoGenSnd" SG_ 1631 FI1_VIN_5 1;
BA_ "GenSigStartValue" SG_ 1631 FI1_VIN_5 88;
BA_ "GenSigAutoGenDsp" SG_ 1631 FI1_VIN_12 1;
BA_ "GenSigAutoGenSnd" SG_ 1631 FI1_VIN_12 1;
BA_ "GenSigStartValue" SG_ 1631 FI1_VIN_12 88;
BA_ "GenSigAutoGenDsp" SG_ 1631 FI1_Geheimnis_3 1;
BA_ "GenSigAutoGenSnd" SG_ 1631 FI1_Geheimnis_3 1;
BA_ "GenSigAutoGenDsp" SG_ 1631 FI1_VIN_6 1;
BA_ "GenSigAutoGenSnd" SG_ 1631 FI1_VIN_6 1;
BA_ "GenSigStartValue" SG_ 1631 FI1_VIN_6 88;
BA_ "GenSigAutoGenDsp" SG_ 1631 FI1_VIN_13 1;
BA_ "GenSigAutoGenSnd" SG_ 1631 FI1_VIN_13 1;
BA_ "GenSigStartValue" SG_ 1631 FI1_VIN_13 88;
BA_ "GenSigAutoGenDsp" SG_ 1631 FI1_Geheimnis_4 1;
BA_ "GenSigAutoGenSnd" SG_ 1631 FI1_Geheimnis_4 1;
BA_ "GenSigAutoGenDsp" SG_ 1631 FI1_VIN_7 1;
BA_ "GenSigAutoGenSnd" SG_ 1631 FI1_VIN_7 1;
BA_ "GenSigStartValue" SG_ 1631 FI1_VIN_7 88;
BA_ "GenSigAutoGenDsp" SG_ 1631 FI1_VIN_14 1;
BA_ "GenSigAutoGenSnd" SG_ 1631 FI1_VIN_14 1;
BA_ "GenSigStartValue" SG_ 1631 FI1_VIN_14 88;
BA_ "GenSigAutoGenDsp" SG_ 1631 FI1_VIN_1 1;
BA_ "GenSigAutoGenSnd" SG_ 1631 FI1_VIN_1 1;
BA_ "GenSigStartValue" SG_ 1631 FI1_VIN_1 88;
BA_ "GenSigAutoGenDsp" SG_ 1631 FI1_VIN_8 1;
BA_ "GenSigAutoGenSnd" SG_ 1631 FI1_VIN_8 1;
BA_ "GenSigStartValue" SG_ 1631 FI1_VIN_8 88;
BA_ "GenSigAutoGenDsp" SG_ 1631 FI1_VIN_15 1;
BA_ "GenSigAutoGenSnd" SG_ 1631 FI1_VIN_15 1;
BA_ "GenSigStartValue" SG_ 1631 FI1_VIN_15 88;
BA_ "GenSigAutoGenDsp" SG_ 1631 FI1_VIN_2 1;
BA_ "GenSigAutoGenSnd" SG_ 1631 FI1_VIN_2 1;
BA_ "GenSigStartValue" SG_ 1631 FI1_VIN_2 88;
BA_ "GenSigAutoGenDsp" SG_ 1631 FI1_VIN_9 1;
BA_ "GenSigAutoGenSnd" SG_ 1631 FI1_VIN_9 1;
BA_ "GenSigStartValue" SG_ 1631 FI1_VIN_9 88;
BA_ "GenSigAutoGenDsp" SG_ 1631 FI1_VIN_16 1;
BA_ "GenSigAutoGenSnd" SG_ 1631 FI1_VIN_16 1;
BA_ "GenSigStartValue" SG_ 1631 FI1_VIN_16 88;
BA_ "GenSigAutoGenDsp" SG_ 1631 FI1_VIN_3 1;
BA_ "GenSigAutoGenSnd" SG_ 1631 FI1_VIN_3 1;
BA_ "GenSigStartValue" SG_ 1631 FI1_VIN_3 88;
BA_ "GenSigAutoGenDsp" SG_ 1631 FI1_VIN_10 1;
BA_ "GenSigAutoGenSnd" SG_ 1631 FI1_VIN_10 1;
BA_ "GenSigStartValue" SG_ 1631 FI1_VIN_10 88;
BA_ "GenSigAutoGenDsp" SG_ 1631 FI1_VIN_17 1;
BA_ "GenSigAutoGenSnd" SG_ 1631 FI1_VIN_17 1;
BA_ "GenSigStartValue" SG_ 1631 FI1_VIN_17 88;
BA_ "GenSigAutoGenDsp" SG_ 849 GW1_FhzgGeschw_alt 1;
BA_ "GenSigAutoGenSnd" SG_ 849 GW1_FhzgGeschw_alt 1;
BA_ "GenSigSendType" SG_ 849 GW1_FhzgGeschw_alt 0;
BA_ "GenSigStartValue" SG_ 849 GW1_FhzgGeschw_alt 1;
BA_ "GenSigFuncType" SG_ 849 GW1_FhzgGeschw_alt 5;
BA_ "GenSigAutoGenDsp" SG_ 849 GW1_Rueckfahrlicht 1;
BA_ "GenSigAutoGenSnd" SG_ 849 GW1_Rueckfahrlicht 1;
BA_ "GenSigSendType" SG_ 849 GW1_Rueckfahrlicht 3;
BA_ "GenSigAutoGenDsp" SG_ 849 GW1_FzgGeschw 1;
BA_ "GenSigAutoGenSnd" SG_ 849 GW1_FzgGeschw 1;
BA_ "GenSigSendType" SG_ 849 GW1_FzgGeschw 0;
BA_ "GenSigStartValue" SG_ 849 GW1_FzgGeschw 32708;
BA_ "GenSigAutoGenDsp" SG_ 849 KKO_alt_mBSG_Kombi 1;
BA_ "GenSigAutoGenSnd" SG_ 849 KKO_alt_mBSG_Kombi 1;
BA_ "GenSigSendType" SG_ 849 KKO_alt_mBSG_Kombi 3;
BA_ "GenSigStartValue" SG_ 849 KKO_alt_mBSG_Kombi 1;
BA_ "GenSigFuncType" SG_ 849 KKO_alt_mBSG_Kombi 5;
BA_ "GenSigAutoGenDsp" SG_ 1619 GW3_Laendervariante 1;
BA_ "GenSigAutoGenSnd" SG_ 1619 GW3_Laendervariante 1;
BA_ "GenSigAutoGenDsp" SG_ 1619 GW3_Alt_3_Kombi 1;
BA_ "GenSigAutoGenSnd" SG_ 1619 GW3_Alt_3_Kombi 1;
BA_ "GenSigSendType" SG_ 1619 GW3_Alt_3_Kombi 0;
BA_ "GenSigStartValue" SG_ 1619 GW3_Alt_3_Kombi 1;
BA_ "GenSigFuncType" SG_ 1619 GW3_Alt_3_Kombi 5;
BA_ "GenSigAutoGenDsp" SG_ 1619 GW3_Land_Sprach_empf 1;
BA_ "GenSigAutoGenSnd" SG_ 1619 GW3_Land_Sprach_empf 1;
BA_ "GenSigSendType" SG_ 1619 GW3_Land_Sprach_empf 0;
BA_ "GenSigAutoGenDsp" SG_ 1619 GW3_Sprachvariante 1;
BA_ "GenSigAutoGenSnd" SG_ 1619 GW3_Sprachvariante 1;
BA_ "GenSigAutoGenDsp" SG_ 1619 GW3_Motortyp 1;
BA_ "GenSigAutoGenSnd" SG_ 1619 GW3_Motortyp 1;
BA_ "GenSigAutoGenDsp" SG_ 1619 GW3_Alt_5_Motor 1;
BA_ "GenSigAutoGenSnd" SG_ 1619 GW3_Alt_5_Motor 1;
BA_ "GenSigSendType" SG_ 1619 GW3_Alt_5_Motor 3;
BA_ "GenSigStartValue" SG_ 1619 GW3_Alt_5_Motor 1;
BA_ "GenSigFuncType" SG_ 1619 GW3_Alt_5_Motor 5;
BA_ "GenSigAutoGenDsp" SG_ 1619 GW3_Motortyp_empf 1;
BA_ "GenSigAutoGenSnd" SG_ 1619 GW3_Motortyp_empf 1;
BA_ "GenSigSendType" SG_ 1619 GW3_Motortyp_empf 0;
BA_ "GenSigAutoGenDsp" SG_ 1487 GS1_Error_flag 1;
BA_ "GenSigAutoGenSnd" SG_ 1487 GS1_Error_flag 1;
BA_ "GenSigSendType" SG_ 1487 GS1_Error_flag 3;
BA_ "GenSigAutoGenDsp" SG_ 857 GWB_Alt_FzgGeschw 1;
BA_ "GenSigAutoGenSnd" SG_ 857 GWB_Alt_FzgGeschw 1;
BA_ "GenSigSendType" SG_ 857 GWB_Alt_FzgGeschw 0;
BA_ "GenSigStartValue" SG_ 857 GWB_Alt_FzgGeschw 1;
BA_ "GenSigFuncType" SG_ 857 GWB_Alt_FzgGeschw 5;
BA_ "GenSigAutoGenDsp" SG_ 857 GWB_Alt_2_Bremse 1;
BA_ "GenSigAutoGenSnd" SG_ 857 GWB_Alt_2_Bremse 1;
BA_ "GenSigSendType" SG_ 857 GWB_Alt_2_Bremse 0;
BA_ "GenSigStartValue" SG_ 857 GWB_Alt_2_Bremse 1;
BA_ "GenSigFuncType" SG_ 857 GWB_Alt_2_Bremse 5;
BA_ "GenSigAutoGenDsp" SG_ 857 GWB_Alt_1_Bremse 1;
BA_ "GenSigAutoGenSnd" SG_ 857 GWB_Alt_1_Bremse 1;
BA_ "GenSigSendType" SG_ 857 GWB_Alt_1_Bremse 0;
BA_ "GenSigStartValue" SG_ 857 GWB_Alt_1_Bremse 1;
BA_ "GenSigFuncType" SG_ 857 GWB_Alt_1_Bremse 5;
BA_ "GenSigAutoGenDsp" SG_ 857 GWB_Alt_1_Getriebe 1;
BA_ "GenSigAutoGenSnd" SG_ 857 GWB_Alt_1_Getriebe 1;
BA_ "GenSigSendType" SG_ 857 GWB_Alt_1_Getriebe 0;
BA_ "GenSigStartValue" SG_ 857 GWB_Alt_1_Getriebe 1;
BA_ "GenSigFuncType" SG_ 857 GWB_Alt_1_Getriebe 5;
BA_ "GenSigAutoGenDsp" SG_ 857 GWB_Alt_2_Getriebe 1;
BA_ "GenSigAutoGenSnd" SG_ 857 GWB_Alt_2_Getriebe 1;
BA_ "GenSigSendType" SG_ 857 GWB_Alt_2_Getriebe 0;
BA_ "GenSigStartValue" SG_ 857 GWB_Alt_2_Getriebe 1;
BA_ "GenSigFuncType" SG_ 857 GWB_Alt_2_Getriebe 5;
BA_ "GenSigAutoGenDsp" SG_ 857 GWB_Alt_1_EPB 1;
BA_ "GenSigAutoGenSnd" SG_ 857 GWB_Alt_1_EPB 1;
BA_ "GenSigSendType" SG_ 857 GWB_Alt_1_EPB 0;
BA_ "GenSigStartValue" SG_ 857 GWB_Alt_1_EPB 1;
BA_ "GenSigFuncType" SG_ 857 GWB_Alt_1_EPB 5;
BA_ "GenSigAutoGenDsp" SG_ 857 GWB_Alt_5_Bremse 1;
BA_ "GenSigAutoGenSnd" SG_ 857 GWB_Alt_5_Bremse 1;
BA_ "GenSigSendType" SG_ 857 GWB_Alt_5_Bremse 0;
BA_ "GenSigStartValue" SG_ 857 GWB_Alt_5_Bremse 1;
BA_ "GenSigFuncType" SG_ 857 GWB_Alt_5_Bremse 5;
BA_ "GenSigAutoGenDsp" SG_ 857 GWB_Alt_AWV_X 1;
BA_ "GenSigAutoGenSnd" SG_ 857 GWB_Alt_AWV_X 1;
BA_ "GenSigSendType" SG_ 857 GWB_Alt_AWV_X 0;
BA_ "GenSigStartValue" SG_ 857 GWB_Alt_AWV_X 1;
BA_ "GenSigFuncType" SG_ 857 GWB_Alt_AWV_X 5;
BA_ "GenSigAutoGenDsp" SG_ 857 GWB_FzgGeschw_Quelle 1;
BA_ "GenSigAutoGenSnd" SG_ 857 GWB_FzgGeschw_Quelle 1;
BA_ "GenSigSendType" SG_ 857 GWB_FzgGeschw_Quelle 0;
BA_ "GenSigStartValue" SG_ 857 GWB_FzgGeschw_Quelle 1;
BA_ "GenSigAutoGenDsp" SG_ 857 GWB_FzgGeschw 1;
BA_ "GenSigAutoGenSnd" SG_ 857 GWB_FzgGeschw 1;
BA_ "GenSigSendType" SG_ 857 GWB_FzgGeschw 0;
BA_ "GenSigStartValue" SG_ 857 GWB_FzgGeschw 32708;
BA_ "GenSigAutoGenDsp" SG_ 857 GWB_Wegimpulse 1;
BA_ "GenSigAutoGenSnd" SG_ 857 GWB_Wegimpulse 1;
BA_ "GenSigSendType" SG_ 857 GWB_Wegimpulse 0;
BA_ "GenSigAutoGenDsp" SG_ 857 GWB_Wegimpuls_Status 1;
BA_ "GenSigAutoGenSnd" SG_ 857 GWB_Wegimpuls_Status 1;
BA_ "GenSigSendType" SG_ 857 GWB_Wegimpuls_Status 0;
BA_ "GenSigAutoGenDsp" SG_ 857 GWB_Wegimpulse_Fehler 1;
BA_ "GenSigAutoGenSnd" SG_ 857 GWB_Wegimpulse_Fehler 1;
BA_ "GenSigSendType" SG_ 857 GWB_Wegimpulse_Fehler 0;
BA_ "Fehlerwert" SG_ 857 GWB_Wegimpulse_Fehler 1;
BA_ "GenSigAutoGenDsp" SG_ 857 GWB_Impulszahl 1;
BA_ "GenSigAutoGenSnd" SG_ 857 GWB_Impulszahl 1;
BA_ "GenSigSendType" SG_ 857 GWB_Impulszahl 0;
BA_ "GenSigSwitchedByIgnition" SG_ 857 GWB_Impulszahl 1;
BA_ "GenSigAutoGenDsp" SG_ 857 GWB_Alt_PLA_Status 1;
BA_ "GenSigAutoGenSnd" SG_ 857 GWB_Alt_PLA_Status 1;
BA_ "GenSigSendType" SG_ 857 GWB_Alt_PLA_Status 0;
BA_ "GenSigStartValue" SG_ 857 GWB_Alt_PLA_Status 1;
BA_ "GenSigFuncType" SG_ 857 GWB_Alt_PLA_Status 5;
BA_ "GenSigSendType" SG_ 857 PLS_Bremsleuchte 0;
BA_ "GenSigSwitchedByIgnition" SG_ 857 PLS_Bremsleuchte 1;
BA_ "GenSigAutoGenDsp" SG_ 857 GWB_TSP_aktiv 1;
BA_ "GenSigAutoGenSnd" SG_ 857 GWB_TSP_aktiv 1;
BA_ "GenSigSendType" SG_ 857 GWB_TSP_aktiv 0;
BA_ "GenSigSwitchedByIgnition" SG_ 857 GWB_TSP_aktiv 1;
BA_ "GenSigAutoGenDsp" SG_ 857 GWB_Notbremsung 1;
BA_ "GenSigAutoGenSnd" SG_ 857 GWB_Notbremsung 1;
BA_ "GenSigSendType" SG_ 857 GWB_Notbremsung 0;
BA_ "GenSigSwitchedByIgnition" SG_ 857 GWB_Notbremsung 1;
BA_ "GenSigAutoGenDsp" SG_ 857 GWB_ABS_Bremsung 1;
BA_ "GenSigAutoGenSnd" SG_ 857 GWB_ABS_Bremsung 1;
BA_ "GenSigSendType" SG_ 857 GWB_ABS_Bremsung 0;
BA_ "GenSigSwitchedByIgnition" SG_ 857 GWB_ABS_Bremsung 1;
BA_ "GenSigAutoGenDsp" SG_ 857 GWB_EPB_Status 1;
BA_ "GenSigAutoGenSnd" SG_ 857 GWB_EPB_Status 1;
BA_ "GenSigSendType" SG_ 857 GWB_EPB_Status 0;
BA_ "GenSigSwitchedByIgnition" SG_ 857 GWB_EPB_Status 1;
BA_ "GenSigAutoGenDsp" SG_ 857 GWB_EPB_Bremslicht 1;
BA_ "GenSigAutoGenSnd" SG_ 857 GWB_EPB_Bremslicht 1;
BA_ "GenSigSendType" SG_ 857 GWB_EPB_Bremslicht 0;
BA_ "GenSigSwitchedByIgnition" SG_ 857 GWB_EPB_Bremslicht 1;
BA_ "GenSigAutoGenDsp" SG_ 857 GWB_Schlechtweg 1;
BA_ "GenSigAutoGenSnd" SG_ 857 GWB_Schlechtweg 1;
BA_ "GenSigSendType" SG_ 857 GWB_Schlechtweg 0;
BA_ "GenSigSwitchedByIgnition" SG_ 857 GWB_Schlechtweg 1;
BA_ "GenSigAutoGenDsp" SG_ 857 GWB_Schlechtweg_Fehler 1;
BA_ "GenSigAutoGenSnd" SG_ 857 GWB_Schlechtweg_Fehler 1;
BA_ "GenSigSendType" SG_ 857 GWB_Schlechtweg_Fehler 0;
BA_ "GenSigSwitchedByIgnition" SG_ 857 GWB_Schlechtweg_Fehler 1;
BA_ "GenSigAutoGenDsp" SG_ 857 GWB_Geschw_Ersatz 1;
BA_ "GenSigAutoGenSnd" SG_ 857 GWB_Geschw_Ersatz 1;
BA_ "GenSigSendType" SG_ 857 GWB_Geschw_Ersatz 0;
BA_ "GenSigStartValue" SG_ 857 GWB_Geschw_Ersatz 1;
BA_ "GenSigSwitchedByIgnition" SG_ 857 GWB_Geschw_Ersatz 1;
BA_ "GenSigAutoGenDsp" SG_ 857 GWB_Schaltvorgang 1;
BA_ "GenSigAutoGenSnd" SG_ 857 GWB_Schaltvorgang 1;
BA_ "GenSigSendType" SG_ 857 GWB_Schaltvorgang 0;
BA_ "GenSigSwitchedByIgnition" SG_ 857 GWB_Schaltvorgang 1;
BA_ "GenSigAutoGenDsp" SG_ 857 ANB_Teilbremsung_Freigabe 1;
BA_ "GenSigAutoGenSnd" SG_ 857 ANB_Teilbremsung_Freigabe 1;
BA_ "GenSigSendType" SG_ 857 ANB_Teilbremsung_Freigabe 0;
BA_ "GenSigSwitchedByIgnition" SG_ 857 ANB_Teilbremsung_Freigabe 1;
BA_ "GenSigAutoGenDsp" SG_ 857 GWB_ESP_Eingriff 1;
BA_ "GenSigAutoGenSnd" SG_ 857 GWB_ESP_Eingriff 1;
BA_ "GenSigSendType" SG_ 857 GWB_ESP_Eingriff 0;
BA_ "GenSigSwitchedByIgnition" SG_ 857 GWB_ESP_Eingriff 1;
BA_ "GenSigAutoGenDsp" SG_ 857 GWB_Shift_Lock 1;
BA_ "GenSigAutoGenSnd" SG_ 857 GWB_Shift_Lock 1;
BA_ "GenSigSendType" SG_ 857 GWB_Shift_Lock 0;
BA_ "GenSigSwitchedByIgnition" SG_ 857 GWB_Shift_Lock 1;
BA_ "GenSigAutoGenDsp" SG_ 857 GWB_Info_Waehlhebel 1;
BA_ "GenSigAutoGenSnd" SG_ 857 GWB_Info_Waehlhebel 1;
BA_ "GenSigSendType" SG_ 857 GWB_Info_Waehlhebel 0;
BA_ "GenSigSwitchedByIgnition" SG_ 857 GWB_Info_Waehlhebel 1;
BA_ "Fehlerwert" SG_ 857 GWB_Info_Waehlhebel 15;
BA_ "GenSigAutoGenDsp" SG_ 1315 GWI_alt_ZKE_4 1;
BA_ "GenSigAutoGenSnd" SG_ 1315 GWI_alt_ZKE_4 1;
BA_ "GenSigSendType" SG_ 1315 GWI_alt_ZKE_4 3;
BA_ "GenSigStartValue" SG_ 1315 GWI_alt_ZKE_4 1;
BA_ "GenSigFuncType" SG_ 1315 GWI_alt_ZKE_4 5;
BA_ "GenSigAutoGenDsp" SG_ 1315 GWI_alt_ZKE_3 1;
BA_ "GenSigAutoGenSnd" SG_ 1315 GWI_alt_ZKE_3 1;
BA_ "GenSigSendType" SG_ 1315 GWI_alt_ZKE_3 3;
BA_ "GenSigStartValue" SG_ 1315 GWI_alt_ZKE_3 1;
BA_ "GenSigFuncType" SG_ 1315 GWI_alt_ZKE_3 5;
BA_ "GenSigAutoGenDsp" SG_ 1315 GWI_alt_Kombi_1 1;
BA_ "GenSigAutoGenSnd" SG_ 1315 GWI_alt_Kombi_1 1;
BA_ "GenSigSendType" SG_ 1315 GWI_alt_Kombi_1 0;
BA_ "GenSigStartValue" SG_ 1315 GWI_alt_Kombi_1 1;
BA_ "GenSigFuncType" SG_ 1315 GWI_alt_Kombi_1 5;
BA_ "GenSigAutoGenDsp" SG_ 1315 GWI_res3 1;
BA_ "GenSigAutoGenSnd" SG_ 1315 GWI_res3 1;
BA_ "GenSigSendType" SG_ 1315 GWI_res3 0;
BA_ "GenSigStartValue" SG_ 1315 GWI_res3 1;
BA_ "GenSigFuncType" SG_ 1315 GWI_res3 5;
BA_ "GenSigAutoGenDsp" SG_ 1315 GWI_res4 1;
BA_ "GenSigAutoGenSnd" SG_ 1315 GWI_res4 1;
BA_ "GenSigSendType" SG_ 1315 GWI_res4 0;
BA_ "GenSigStartValue" SG_ 1315 GWI_res4 1;
BA_ "GenSigFuncType" SG_ 1315 GWI_res4 5;
BA_ "GenSigAutoGenDsp" SG_ 1315 GWI_res5 1;
BA_ "GenSigAutoGenSnd" SG_ 1315 GWI_res5 1;
BA_ "GenSigSendType" SG_ 1315 GWI_res5 0;
BA_ "GenSigStartValue" SG_ 1315 GWI_res5 1;
BA_ "GenSigFuncType" SG_ 1315 GWI_res5 5;
BA_ "GenSigAutoGenDsp" SG_ 1315 GWI_res6 1;
BA_ "GenSigAutoGenSnd" SG_ 1315 GWI_res6 1;
BA_ "GenSigSendType" SG_ 1315 GWI_res6 0;
BA_ "GenSigStartValue" SG_ 1315 GWI_res6 1;
BA_ "GenSigFuncType" SG_ 1315 GWI_res6 5;
BA_ "GenSigAutoGenDsp" SG_ 1315 GWI_res7 1;
BA_ "GenSigAutoGenSnd" SG_ 1315 GWI_res7 1;
BA_ "GenSigSendType" SG_ 1315 GWI_res7 0;
BA_ "GenSigStartValue" SG_ 1315 GWI_res7 1;
BA_ "GenSigFuncType" SG_ 1315 GWI_res7 5;
BA_ "GenSigAutoGenDsp" SG_ 1315 GWI_Status_Verdeck 1;
BA_ "GenSigAutoGenSnd" SG_ 1315 GWI_Status_Verdeck 1;
BA_ "GenSigSendType" SG_ 1315 GWI_Status_Verdeck 3;
BA_ "GenSigAutoGenDsp" SG_ 1315 GWI_ZKE4_Zusatzfkt 1;
BA_ "GenSigAutoGenSnd" SG_ 1315 GWI_ZKE4_Zusatzfkt 1;
BA_ "GenSigSendType" SG_ 1315 GWI_ZKE4_Zusatzfkt 3;
BA_ "GenSigAutoGenDsp" SG_ 1315 GWI_Blk_ZV_auf 1;
BA_ "GenSigAutoGenSnd" SG_ 1315 GWI_Blk_ZV_auf 1;
BA_ "GenSigSendType" SG_ 1315 GWI_Blk_ZV_auf 4;
BA_ "GenSigAutoGenDsp" SG_ 1315 GWI_Blk_ZV_zu 1;
BA_ "GenSigAutoGenSnd" SG_ 1315 GWI_Blk_ZV_zu 1;
BA_ "GenSigSendType" SG_ 1315 GWI_Blk_ZV_zu 4;
BA_ "GenSigAutoGenDsp" SG_ 1315 GWI_Blk_DW_ein 1;
BA_ "GenSigAutoGenSnd" SG_ 1315 GWI_Blk_DW_ein 1;
BA_ "GenSigSendType" SG_ 1315 GWI_Blk_DW_ein 4;
BA_ "GenSigAutoGenDsp" SG_ 1315 GWI_DWA_Alarm 1;
BA_ "GenSigAutoGenSnd" SG_ 1315 GWI_DWA_Alarm 1;
BA_ "GenSigSendType" SG_ 1315 GWI_DWA_Alarm 4;
BA_ "GenSigAutoGenDsp" SG_ 1315 GWI_verriegelt_int 1;
BA_ "GenSigAutoGenSnd" SG_ 1315 GWI_verriegelt_int 1;
BA_ "GenSigSendType" SG_ 1315 GWI_verriegelt_int 3;
BA_ "GenSigAutoGenDsp" SG_ 1315 GWI_verriegelt_ext 1;
BA_ "GenSigAutoGenSnd" SG_ 1315 GWI_verriegelt_ext 1;
BA_ "GenSigSendType" SG_ 1315 GWI_verriegelt_ext 3;
BA_ "GenSigAutoGenDsp" SG_ 1315 GWI_gesaeft_ext 1;
BA_ "GenSigAutoGenSnd" SG_ 1315 GWI_gesaeft_ext 1;
BA_ "GenSigSendType" SG_ 1315 GWI_gesaeft_ext 3;
BA_ "GenSigAutoGenDsp" SG_ 1315 KB1_angez_kmh 1;
BA_ "GenSigAutoGenSnd" SG_ 1315 KB1_angez_kmh 1;
BA_ "GenSigSendType" SG_ 1315 KB1_angez_kmh 0;
BA_ "Fehlerwert" SG_ 1315 KB1_angez_kmh 1020;
BA_ "GenSigAutoGenDsp" SG_ 1319 GWK_Alt_3_Kombi 1;
BA_ "GenSigAutoGenSnd" SG_ 1319 GWK_Alt_3_Kombi 1;
BA_ "GenSigSendType" SG_ 1319 GWK_Alt_3_Kombi 0;
BA_ "GenSigStartValue" SG_ 1319 GWK_Alt_3_Kombi 1;
BA_ "GenSigFuncType" SG_ 1319 GWK_Alt_3_Kombi 5;
BA_ "GenSigAutoGenDsp" SG_ 1319 GWK_Alt_2_Kombi 1;
BA_ "GenSigAutoGenSnd" SG_ 1319 GWK_Alt_2_Kombi 1;
BA_ "GenSigSendType" SG_ 1319 GWK_Alt_2_Kombi 0;
BA_ "GenSigStartValue" SG_ 1319 GWK_Alt_2_Kombi 1;
BA_ "GenSigFuncType" SG_ 1319 GWK_Alt_2_Kombi 5;
BA_ "GenSigAutoGenDsp" SG_ 1319 GWK_Alt_1_Kombi 1;
BA_ "GenSigAutoGenSnd" SG_ 1319 GWK_Alt_1_Kombi 1;
BA_ "GenSigSendType" SG_ 1319 GWK_Alt_1_Kombi 0;
BA_ "GenSigStartValue" SG_ 1319 GWK_Alt_1_Kombi 1;
BA_ "GenSigFuncType" SG_ 1319 GWK_Alt_1_Kombi 5;
BA_ "GenSigAutoGenDsp" SG_ 1319 GWK_Reifenumfang_empf 1;
BA_ "GenSigAutoGenSnd" SG_ 1319 GWK_Reifenumfang_empf 1;
BA_ "GenSigSendType" SG_ 1319 GWK_Reifenumfang_empf 0;
BA_ "GenSigAutoGenDsp" SG_ 1319 GWK_FzgGeschw_Quelle 1;
BA_ "GenSigAutoGenSnd" SG_ 1319 GWK_FzgGeschw_Quelle 1;
BA_ "GenSigSendType" SG_ 1319 GWK_FzgGeschw_Quelle 0;
BA_ "GenSigAutoGenDsp" SG_ 1319 GWK_FzgGeschw 1;
BA_ "GenSigAutoGenSnd" SG_ 1319 GWK_FzgGeschw 1;
BA_ "GenSigSendType" SG_ 1319 GWK_FzgGeschw 0;
BA_ "GenSigAutoGenDsp" SG_ 1319 GWK_Umfang_Reifen 1;
BA_ "GenSigAutoGenSnd" SG_ 1319 GWK_Umfang_Reifen 1;
BA_ "GenSigAutoGenDsp" SG_ 1319 GWK_AussenTemp_gefiltert 1;
BA_ "GenSigAutoGenSnd" SG_ 1319 GWK_AussenTemp_gefiltert 1;
BA_ "GenSigSendType" SG_ 1319 GWK_AussenTemp_gefiltert 0;
BA_ "Fehlerwert" SG_ 1319 GWK_AussenTemp_gefiltert 255;
BA_ "GenSigAutoGenDsp" SG_ 1319 GWK_AussenTemp_ungefiltert 1;
BA_ "GenSigAutoGenSnd" SG_ 1319 GWK_AussenTemp_ungefiltert 1;
BA_ "GenSigSendType" SG_ 1319 GWK_AussenTemp_ungefiltert 0;
BA_ "Fehlerwert" SG_ 1319 GWK_AussenTemp_ungefiltert 255;
BA_ "GenSigAutoGenDsp" SG_ 1319 GWK_AussenTemp_Fehler 1;
BA_ "GenSigAutoGenSnd" SG_ 1319 GWK_AussenTemp_Fehler 1;
BA_ "GenSigSendType" SG_ 1319 GWK_AussenTemp_Fehler 0;
BA_ "GenSigStartValue" SG_ 1319 GWK_AussenTemp_Fehler 1;
BA_ "GenSigAutoGenDsp" SG_ 1319 GWK_Warn_Heiss 1;
BA_ "GenSigAutoGenSnd" SG_ 1319 GWK_Warn_Heiss 1;
BA_ "GenSigSendType" SG_ 1319 GWK_Warn_Heiss 0;
BA_ "GenSigSwitchedByIgnition" SG_ 1319 GWK_Warn_Heiss 1;
BA_ "GenSigAutoGenDsp" SG_ 1319 GWK_Passiv_Autolock 1;
BA_ "GenSigAutoGenSnd" SG_ 1319 GWK_Passiv_Autolock 1;
BA_ "GenSigSendType" SG_ 1319 GWK_Passiv_Autolock 0;
BA_ "GenSigAutoGenDsp" SG_ 1319 GWK_WFS_Schl_Ort 1;
BA_ "GenSigAutoGenSnd" SG_ 1319 GWK_WFS_Schl_Ort 1;
BA_ "GenSigSendType" SG_ 1319 GWK_WFS_Schl_Ort 0;
BA_ "GenSigAutoGenDsp" SG_ 1319 KB1_Lenkh_Lampe 1;
BA_ "GenSigAutoGenSnd" SG_ 1319 KB1_Lenkh_Lampe 1;
BA_ "GenSigSendType" SG_ 1319 KB1_Lenkh_Lampe 0;
BA_ "GenSigAutoGenDsp" SG_ 859 GWM_Alt_1_Motor 1;
BA_ "GenSigAutoGenSnd" SG_ 859 GWM_Alt_1_Motor 1;
BA_ "GenSigSendType" SG_ 859 GWM_Alt_1_Motor 0;
BA_ "GenSigStartValue" SG_ 859 GWM_Alt_1_Motor 1;
BA_ "GenSigFuncType" SG_ 859 GWM_Alt_1_Motor 5;
BA_ "GenSigAutoGenDsp" SG_ 859 GWM_Alt_2_Motor 1;
BA_ "GenSigAutoGenSnd" SG_ 859 GWM_Alt_2_Motor 1;
BA_ "GenSigSendType" SG_ 859 GWM_Alt_2_Motor 3;
BA_ "GenSigStartValue" SG_ 859 GWM_Alt_2_Motor 1;
BA_ "GenSigFuncType" SG_ 859 GWM_Alt_2_Motor 5;
BA_ "GenSigAutoGenDsp" SG_ 859 GWM_Alt_5_Motor 1;
BA_ "GenSigAutoGenSnd" SG_ 859 GWM_Alt_5_Motor 1;
BA_ "GenSigSendType" SG_ 859 GWM_Alt_5_Motor 3;
BA_ "GenSigStartValue" SG_ 859 GWM_Alt_5_Motor 1;
BA_ "GenSigFuncType" SG_ 859 GWM_Alt_5_Motor 5;
BA_ "GenSigAutoGenDsp" SG_ 859 GWM_Alt_Motor_Bremse 1;
BA_ "GenSigAutoGenSnd" SG_ 859 GWM_Alt_Motor_Bremse 1;
BA_ "GenSigSendType" SG_ 859 GWM_Alt_Motor_Bremse 3;
BA_ "GenSigStartValue" SG_ 859 GWM_Alt_Motor_Bremse 1;
BA_ "GenSigFuncType" SG_ 859 GWM_Alt_Motor_Bremse 5;
BA_ "GenSigAutoGenDsp" SG_ 859 GWM_RME_Gehalt 1;
BA_ "GenSigAutoGenSnd" SG_ 859 GWM_RME_Gehalt 1;
BA_ "GenSigSendType" SG_ 859 GWM_RME_Gehalt 0;
BA_ "GenSigSwitchedByIgnition" SG_ 859 GWM_RME_Gehalt 1;
BA_ "Fehlerwert" SG_ 859 GWM_RME_Gehalt 7;
BA_ "GenSigAutoGenDsp" SG_ 859 GWM_Motordrehzahl 1;
BA_ "GenSigAutoGenSnd" SG_ 859 GWM_Motordrehzahl 1;
BA_ "GenSigSendType" SG_ 859 GWM_Motordrehzahl 0;
BA_ "GenSigSwitchedByIgnition" SG_ 859 GWM_Motordrehzahl 1;
BA_ "Fehlerwert" SG_ 859 GWM_Motordrehzahl 65280;
BA_ "GenSigAutoGenDsp" SG_ 859 GWM_KuehlmittelTemp 1;
BA_ "GenSigAutoGenSnd" SG_ 859 GWM_KuehlmittelTemp 1;
BA_ "GenSigSendType" SG_ 859 GWM_KuehlmittelTemp 0;
BA_ "GenSigSwitchedByIgnition" SG_ 859 GWM_KuehlmittelTemp 1;
BA_ "Fehlerwert" SG_ 859 GWM_KuehlmittelTemp 255;
BA_ "GenSigAutoGenDsp" SG_ 859 GWM_Bremslicht_Schalter 1;
BA_ "GenSigAutoGenSnd" SG_ 859 GWM_Bremslicht_Schalter 1;
BA_ "GenSigSendType" SG_ 859 GWM_Bremslicht_Schalter 0;
BA_ "GenSigSwitchedByIgnition" SG_ 859 GWM_Bremslicht_Schalter 1;
BA_ "GenSigAutoGenDsp" SG_ 859 GWM_Bremstest_Schalter 1;
BA_ "GenSigAutoGenSnd" SG_ 859 GWM_Bremstest_Schalter 1;
BA_ "GenSigSendType" SG_ 859 GWM_Bremstest_Schalter 0;
BA_ "GenSigSwitchedByIgnition" SG_ 859 GWM_Bremstest_Schalter 1;
BA_ "GenSigAutoGenDsp" SG_ 859 GWM_Fehl_KmittelTemp 1;
BA_ "GenSigAutoGenSnd" SG_ 859 GWM_Fehl_KmittelTemp 1;
BA_ "GenSigSendType" SG_ 859 GWM_Fehl_KmittelTemp 0;
BA_ "GenSigSwitchedByIgnition" SG_ 859 GWM_Fehl_KmittelTemp 1;
BA_ "GenSigAutoGenDsp" SG_ 859 GWM_Kuppl_Schalter 1;
BA_ "GenSigAutoGenSnd" SG_ 859 GWM_Kuppl_Schalter 1;
BA_ "GenSigSendType" SG_ 859 GWM_Kuppl_Schalter 0;
BA_ "GenSigSwitchedByIgnition" SG_ 859 GWM_Kuppl_Schalter 1;
BA_ "GenSigAutoGenDsp" SG_ 859 GWM_Heissl_Vorwarn 1;
BA_ "GenSigAutoGenSnd" SG_ 859 GWM_Heissl_Vorwarn 1;
BA_ "GenSigSendType" SG_ 859 GWM_Heissl_Vorwarn 0;
BA_ "GenSigSwitchedByIgnition" SG_ 859 GWM_Heissl_Vorwarn 1;
BA_ "GenSigAutoGenDsp" SG_ 859 GWM_Klimaabschaltung 1;
BA_ "GenSigAutoGenSnd" SG_ 859 GWM_Klimaabschaltung 1;
BA_ "GenSigSendType" SG_ 859 GWM_Klimaabschaltung 0;
BA_ "GenSigSwitchedByIgnition" SG_ 859 GWM_Klimaabschaltung 1;
BA_ "GenSigAutoGenDsp" SG_ 859 GWM_Kennfeldkuehlung 1;
BA_ "GenSigAutoGenSnd" SG_ 859 GWM_Kennfeldkuehlung 1;
BA_ "GenSigSendType" SG_ 859 GWM_Kennfeldkuehlung 0;
BA_ "GenSigSwitchedByIgnition" SG_ 859 GWM_Kennfeldkuehlung 1;
BA_ "GenSigAutoGenDsp" SG_ 859 GWM_Komp_Leist_red 1;
BA_ "GenSigAutoGenSnd" SG_ 859 GWM_Komp_Leist_red 1;
BA_ "GenSigSendType" SG_ 859 GWM_Komp_Leist_red 0;
BA_ "GenSigSwitchedByIgnition" SG_ 859 GWM_Komp_Leist_red 1;
BA_ "GenSigAutoGenDsp" SG_ 859 GWM_KLuefter 1;
BA_ "GenSigAutoGenSnd" SG_ 859 GWM_KLuefter 1;
BA_ "GenSigSendType" SG_ 859 GWM_KLuefter 0;
BA_ "GenSigSwitchedByIgnition" SG_ 859 GWM_KLuefter 1;
BA_ "Fehlerwert" SG_ 859 GWM_KLuefter 255;
BA_ "GenSigAutoGenDsp" SG_ 859 GWM_Anl_Freigabe 1;
BA_ "GenSigAutoGenSnd" SG_ 859 GWM_Anl_Freigabe 1;
BA_ "GenSigSendType" SG_ 859 GWM_Anl_Freigabe 0;
BA_ "GenSigSwitchedByIgnition" SG_ 859 GWM_Anl_Freigabe 1;
BA_ "GenSigAutoGenDsp" SG_ 859 GWM_Anl_Ausspuren 1;
BA_ "GenSigAutoGenSnd" SG_ 859 GWM_Anl_Ausspuren 1;
BA_ "GenSigSendType" SG_ 859 GWM_Anl_Ausspuren 0;
BA_ "GenSigSwitchedByIgnition" SG_ 859 GWM_Anl_Ausspuren 1;
BA_ "GenSigAutoGenDsp" SG_ 859 GWM_Interlock 1;
BA_ "GenSigAutoGenSnd" SG_ 859 GWM_Interlock 1;
BA_ "GenSigSendType" SG_ 859 GWM_Interlock 0;
BA_ "GenSigSwitchedByIgnition" SG_ 859 GWM_Interlock 1;
BA_ "GenSigAutoGenDsp" SG_ 859 GWM_TypStartSteu 1;
BA_ "GenSigAutoGenSnd" SG_ 859 GWM_TypStartSteu 1;
BA_ "GenSigSendType" SG_ 859 GWM_TypStartSteu 0;
BA_ "GenSigSwitchedByIgnition" SG_ 859 GWM_TypStartSteu 1;
BA_ "GenSigAutoGenDsp" SG_ 859 GWM_Freig_Bremsanforderung 1;
BA_ "GenSigAutoGenSnd" SG_ 859 GWM_Freig_Bremsanforderung 1;
BA_ "GenSigSendType" SG_ 859 GWM_Freig_Bremsanforderung 0;
BA_ "GenSigSwitchedByIgnition" SG_ 859 GWM_Freig_Bremsanforderung 1;
BA_ "GenSigAutoGenDsp" SG_ 859 GWM_Vorgluehen 1;
BA_ "GenSigAutoGenSnd" SG_ 859 GWM_Vorgluehen 1;
BA_ "GenSigSendType" SG_ 859 GWM_Vorgluehen 0;
BA_ "GenSigSwitchedByIgnition" SG_ 859 GWM_Vorgluehen 1;
BA_ "GenSigAutoGenDsp" SG_ 859 GWM_GRA_Status 1;
BA_ "GenSigAutoGenSnd" SG_ 859 GWM_GRA_Status 1;
BA_ "GenSigSendType" SG_ 859 GWM_GRA_Status 0;
BA_ "GenSigSwitchedByIgnition" SG_ 859 GWM_GRA_Status 1;
BA_ "GenSigAutoGenDsp" SG_ 859 GWM_KVerbrauch 1;
BA_ "GenSigAutoGenSnd" SG_ 859 GWM_KVerbrauch 1;
BA_ "GenSigSendType" SG_ 859 GWM_KVerbrauch 0;
BA_ "GenSigAutoGenDsp" SG_ 859 GWM_Ueberl_KV 1;
BA_ "GenSigAutoGenSnd" SG_ 859 GWM_Ueberl_KV 1;
BA_ "GenSigSendType" SG_ 859 GWM_Ueberl_KV 0;
BA_ "GenSigSwitchedByIgnition" SG_ 859 GWM_Ueberl_KV 1;
BA_ "GenSigAutoGenDsp" SG_ 1367 EKD_Motor_A 1;
BA_ "GenSigAutoGenSnd" SG_ 1367 EKD_Motor_A 1;
BA_ "GenSigSendType" SG_ 1367 EKD_Motor_A 0;
BA_ "GenSigAutoGenDsp" SG_ 1367 EKD_Getriebe_A 1;
BA_ "GenSigAutoGenSnd" SG_ 1367 EKD_Getriebe_A 1;
BA_ "GenSigSendType" SG_ 1367 EKD_Getriebe_A 0;
BA_ "GenSigAutoGenDsp" SG_ 1367 EKD_Bremse_A 1;
BA_ "GenSigAutoGenSnd" SG_ 1367 EKD_Bremse_A 1;
BA_ "GenSigSendType" SG_ 1367 EKD_Bremse_A 0;
BA_ "GenSigAutoGenDsp" SG_ 1367 EKD_Kombi_A 1;
BA_ "GenSigAutoGenSnd" SG_ 1367 EKD_Kombi_A 1;
BA_ "GenSigSendType" SG_ 1367 EKD_Kombi_A 0;
BA_ "GenSigAutoGenDsp" SG_ 1367 EKD_LSM_A 1;
BA_ "GenSigAutoGenSnd" SG_ 1367 EKD_LSM_A 1;
BA_ "GenSigSendType" SG_ 1367 EKD_LSM_A 0;
BA_ "GenSigAutoGenDsp" SG_ 1367 EKD_Airbag_A 1;
BA_ "GenSigAutoGenSnd" SG_ 1367 EKD_Airbag_A 1;
BA_ "GenSigSendType" SG_ 1367 EKD_Airbag_A 0;
BA_ "GenSigSwitchedByIgnition" SG_ 1367 EKD_Airbag_A 1;
BA_ "GenSigAutoGenDsp" SG_ 1367 EKD_Lenkhilfe_A 1;
BA_ "GenSigAutoGenSnd" SG_ 1367 EKD_Lenkhilfe_A 1;
BA_ "GenSigSendType" SG_ 1367 EKD_Lenkhilfe_A 0;
BA_ "GenSigAutoGenDsp" SG_ 1367 EKD_dyn_LWR_A 1;
BA_ "GenSigAutoGenSnd" SG_ 1367 EKD_dyn_LWR_A 1;
BA_ "GenSigSendType" SG_ 1367 EKD_dyn_LWR_A 0;
BA_ "GenSigSwitchedByIgnition" SG_ 1367 EKD_dyn_LWR_A 1;
BA_ "GenSigAutoGenDsp" SG_ 1367 EKD_Niveau_A 1;
BA_ "GenSigAutoGenSnd" SG_ 1367 EKD_Niveau_A 1;
BA_ "GenSigSendType" SG_ 1367 EKD_Niveau_A 0;
BA_ "GenSigAutoGenDsp" SG_ 1367 EKD_Allrad_A 1;
BA_ "GenSigAutoGenSnd" SG_ 1367 EKD_Allrad_A 1;
BA_ "GenSigSendType" SG_ 1367 EKD_Allrad_A 0;
BA_ "GenSigSwitchedByIgnition" SG_ 1367 EKD_Allrad_A 1;
BA_ "GenSigAutoGenDsp" SG_ 1367 EKD_ADR_Sensor_A 1;
BA_ "GenSigAutoGenSnd" SG_ 1367 EKD_ADR_Sensor_A 1;
BA_ "GenSigSendType" SG_ 1367 EKD_ADR_Sensor_A 0;
BA_ "GenSigSwitchedByIgnition" SG_ 1367 EKD_ADR_Sensor_A 1;
BA_ "GenSigAutoGenDsp" SG_ 1367 EKD_ADR_getrennt 1;
BA_ "GenSigAutoGenSnd" SG_ 1367 EKD_ADR_getrennt 1;
BA_ "GenSigSendType" SG_ 1367 EKD_ADR_getrennt 0;
BA_ "GenSigAutoGenDsp" SG_ 1367 EKD_Parkbremse_A 1;
BA_ "GenSigAutoGenSnd" SG_ 1367 EKD_Parkbremse_A 1;
BA_ "GenSigSendType" SG_ 1367 EKD_Parkbremse_A 0;
BA_ "GenSigAutoGenDsp" SG_ 1367 EKD_EZS_A 1;
BA_ "GenSigAutoGenSnd" SG_ 1367 EKD_EZS_A 1;
BA_ "GenSigSendType" SG_ 1367 EKD_EZS_A 0;
BA_ "GenSigAutoGenDsp" SG_ 1367 EKD_Daempfer_A 1;
BA_ "GenSigAutoGenSnd" SG_ 1367 EKD_Daempfer_A 1;
BA_ "GenSigSendType" SG_ 1367 EKD_Daempfer_A 0;
BA_ "GenSigSwitchedByIgnition" SG_ 1367 EKD_Daempfer_A 1;
BA_ "GenSigAutoGenDsp" SG_ 1367 EKD_Quersperre 1;
BA_ "GenSigAutoGenSnd" SG_ 1367 EKD_Quersperre 1;
BA_ "GenSigSendType" SG_ 1367 EKD_Quersperre 0;
BA_ "GenSigSwitchedByIgnition" SG_ 1367 EKD_Quersperre 1;
BA_ "Fehlerwert" SG_ 1367 EKD_Quersperre 1;
BA_ "GenSigAutoGenDsp" SG_ 1367 EKD_Motor_Slave_A 1;
BA_ "GenSigAutoGenSnd" SG_ 1367 EKD_Motor_Slave_A 1;
BA_ "GenSigSendType" SG_ 1367 EKD_Motor_Slave_A 0;
BA_ "GenSigSwitchedByIgnition" SG_ 1367 EKD_Motor_Slave_A 1;
BA_ "GenSigAutoGenDsp" SG_ 1367 EKD_SWA_A 1;
BA_ "GenSigAutoGenSnd" SG_ 1367 EKD_SWA_A 1;
BA_ "GenSigSendType" SG_ 1367 EKD_SWA_A 0;
BA_ "GenSigSwitchedByIgnition" SG_ 1367 EKD_SWA_A 1;
BA_ "Fehlerwert" SG_ 1367 EKD_SWA_A 1;
BA_ "GenSigAutoGenDsp" SG_ 1367 EKD_LDW_A 1;
BA_ "GenSigAutoGenSnd" SG_ 1367 EKD_LDW_A 1;
BA_ "GenSigSendType" SG_ 1367 EKD_LDW_A 0;
BA_ "GenSigSwitchedByIgnition" SG_ 1367 EKD_LDW_A 1;
BA_ "Fehlerwert" SG_ 1367 EKD_LDW_A 1;
BA_ "GenSigAutoGenDsp" SG_ 1367 EKD_RKA_Plus_A 1;
BA_ "GenSigAutoGenSnd" SG_ 1367 EKD_RKA_Plus_A 1;
BA_ "GenSigSendType" SG_ 1367 EKD_RKA_Plus_A 0;
BA_ "GenSigSwitchedByIgnition" SG_ 1367 EKD_RKA_Plus_A 1;
BA_ "GenSigAutoGenDsp" SG_ 1367 EKD_PLA_A 1;
BA_ "GenSigAutoGenSnd" SG_ 1367 EKD_PLA_A 1;
BA_ "GenSigSendType" SG_ 1367 EKD_PLA_A 3;
BA_ "GenSigSwitchedByIgnition" SG_ 1367 EKD_PLA_A 1;
BA_ "Fehlerwert" SG_ 1367 EKD_PLA_A 1;
BA_ "GenSigAutoGenDsp" SG_ 1367 EKD_WFS_KBI 1;
BA_ "GenSigAutoGenSnd" SG_ 1367 EKD_WFS_KBI 1;
BA_ "GenSigSendType" SG_ 1367 EKD_WFS_KBI 0;
BA_ "GenSigAutoGenDsp" SG_ 1367 EKD_Kombi_KBI 1;
BA_ "GenSigAutoGenSnd" SG_ 1367 EKD_Kombi_KBI 1;
BA_ "GenSigSendType" SG_ 1367 EKD_Kombi_KBI 0;
BA_ "GenSigAutoGenDsp" SG_ 1367 EKD_BSG_K 1;
BA_ "GenSigAutoGenSnd" SG_ 1367 EKD_BSG_K 1;
BA_ "GenSigSendType" SG_ 1367 EKD_BSG_K 3;
BA_ "Fehlerwert" SG_ 1367 EKD_BSG_K 1;
BA_ "GenSigAutoGenDsp" SG_ 1367 EKD_KSG_K 1;
BA_ "GenSigAutoGenSnd" SG_ 1367 EKD_KSG_K 1;
BA_ "GenSigSendType" SG_ 1367 EKD_KSG_K 3;
BA_ "GenSigAutoGenDsp" SG_ 1367 EKD_TSG_FT_K 1;
BA_ "GenSigAutoGenSnd" SG_ 1367 EKD_TSG_FT_K 1;
BA_ "GenSigSendType" SG_ 1367 EKD_TSG_FT_K 3;
BA_ "GenSigAutoGenDsp" SG_ 1367 EKD_TSG_BT_K 1;
BA_ "GenSigAutoGenSnd" SG_ 1367 EKD_TSG_BT_K 1;
BA_ "GenSigSendType" SG_ 1367 EKD_TSG_BT_K 3;
BA_ "GenSigAutoGenDsp" SG_ 1367 EKD_TSG_HL_K 1;
BA_ "GenSigAutoGenSnd" SG_ 1367 EKD_TSG_HL_K 1;
BA_ "GenSigSendType" SG_ 1367 EKD_TSG_HL_K 3;
BA_ "GenSigAutoGenDsp" SG_ 1367 EKD_TSG_HR_K 1;
BA_ "GenSigAutoGenSnd" SG_ 1367 EKD_TSG_HR_K 1;
BA_ "GenSigSendType" SG_ 1367 EKD_TSG_HR_K 3;
BA_ "GenSigAutoGenDsp" SG_ 1367 EKD_Memory_K 1;
BA_ "GenSigAutoGenSnd" SG_ 1367 EKD_Memory_K 1;
BA_ "GenSigSendType" SG_ 1367 EKD_Memory_K 3;
BA_ "GenSigAutoGenDsp" SG_ 1367 EKD_Dachmodul_K 1;
BA_ "GenSigAutoGenSnd" SG_ 1367 EKD_Dachmodul_K 1;
BA_ "GenSigSendType" SG_ 1367 EKD_Dachmodul_K 0;
BA_ "GenSigAutoGenDsp" SG_ 1367 EKD_Zentralelektrik_II_K 1;
BA_ "GenSigAutoGenSnd" SG_ 1367 EKD_Zentralelektrik_II_K 1;
BA_ "GenSigSendType" SG_ 1367 EKD_Zentralelektrik_II_K 0;
BA_ "GenSigAutoGenDsp" SG_ 1367 EKD_RDK_K 1;
BA_ "GenSigAutoGenSnd" SG_ 1367 EKD_RDK_K 1;
BA_ "GenSigSendType" SG_ 1367 EKD_RDK_K 3;
BA_ "GenSigAutoGenDsp" SG_ 1367 EKD_SMLS_K 1;
BA_ "GenSigAutoGenSnd" SG_ 1367 EKD_SMLS_K 1;
BA_ "GenSigSendType" SG_ 1367 EKD_SMLS_K 0;
BA_ "GenSigAutoGenDsp" SG_ 1367 EKD_Gateway_K 1;
BA_ "GenSigAutoGenSnd" SG_ 1367 EKD_Gateway_K 1;
BA_ "GenSigSendType" SG_ 1367 EKD_Gateway_K 0;
BA_ "GenSigAutoGenDsp" SG_ 1367 EKD_Clima_K 1;
BA_ "GenSigAutoGenSnd" SG_ 1367 EKD_Clima_K 1;
BA_ "GenSigSendType" SG_ 1367 EKD_Clima_K 0;
BA_ "GenSigAutoGenDsp" SG_ 1367 EKD_APS_K 1;
BA_ "GenSigAutoGenSnd" SG_ 1367 EKD_APS_K 1;
BA_ "GenSigSendType" SG_ 1367 EKD_APS_K 3;
BA_ "GenSigAutoGenDsp" SG_ 1367 EKD_PTC_Heizung_K 1;
BA_ "GenSigAutoGenSnd" SG_ 1367 EKD_PTC_Heizung_K 1;
BA_ "GenSigSendType" SG_ 1367 EKD_PTC_Heizung_K 3;
BA_ "GenSigAutoGenDsp" SG_ 1367 EKD_Standhzg_K 1;
BA_ "GenSigAutoGenSnd" SG_ 1367 EKD_Standhzg_K 1;
BA_ "GenSigSendType" SG_ 1367 EKD_Standhzg_K 3;
BA_ "Fehlerwert" SG_ 1367 EKD_Standhzg_K 1;
BA_ "GenSigAutoGenDsp" SG_ 1367 EKD_VSG_K 1;
BA_ "GenSigAutoGenSnd" SG_ 1367 EKD_VSG_K 1;
BA_ "GenSigSendType" SG_ 1367 EKD_VSG_K 3;
BA_ "GenSigAutoGenDsp" SG_ 1367 EKD_RSE_I 1;
BA_ "GenSigAutoGenSnd" SG_ 1367 EKD_RSE_I 1;
BA_ "GenSigSendType" SG_ 1367 EKD_RSE_I 0;
BA_ "GenSigAutoGenDsp" SG_ 1367 EKD_Wischer_K 1;
BA_ "GenSigAutoGenSnd" SG_ 1367 EKD_Wischer_K 1;
BA_ "GenSigSendType" SG_ 1367 EKD_Wischer_K 0;
BA_ "GenSigAutoGenDsp" SG_ 1367 EKD_MDI_I 1;
BA_ "GenSigAutoGenSnd" SG_ 1367 EKD_MDI_I 1;
BA_ "GenSigSendType" SG_ 1367 EKD_MDI_I 3;
BA_ "GenSigAutoGenDsp" SG_ 1367 EKD_AAG_K 1;
BA_ "GenSigAutoGenSnd" SG_ 1367 EKD_AAG_K 1;
BA_ "GenSigSendType" SG_ 1367 EKD_AAG_K 3;
BA_ "GenSigAutoGenDsp" SG_ 1367 EKD_Mem_BF_K 1;
BA_ "GenSigAutoGenSnd" SG_ 1367 EKD_Mem_BF_K 1;
BA_ "GenSigSendType" SG_ 1367 EKD_Mem_BF_K 3;
BA_ "GenSigAutoGenDsp" SG_ 1367 EKD_Easy_Entry_VF 1;
BA_ "GenSigAutoGenSnd" SG_ 1367 EKD_Easy_Entry_VF 1;
BA_ "GenSigSendType" SG_ 1367 EKD_Easy_Entry_VF 3;
BA_ "GenSigAutoGenDsp" SG_ 1367 EKD_Easy_Entry_VB 1;
BA_ "GenSigAutoGenSnd" SG_ 1367 EKD_Easy_Entry_VB 1;
BA_ "GenSigSendType" SG_ 1367 EKD_Easy_Entry_VB 3;
BA_ "GenSigAutoGenDsp" SG_ 1367 EKD_Heckdeckel_K 1;
BA_ "GenSigAutoGenSnd" SG_ 1367 EKD_Heckdeckel_K 1;
BA_ "GenSigSendType" SG_ 1367 EKD_Heckdeckel_K 3;
BA_ "GenSigAutoGenDsp" SG_ 1367 EKD_Rearview_I 1;
BA_ "GenSigAutoGenSnd" SG_ 1367 EKD_Rearview_I 1;
BA_ "GenSigSendType" SG_ 1367 EKD_Rearview_I 3;
BA_ "GenSigAutoGenDsp" SG_ 1367 EKD_Sonderfahrzeug_SG_K 1;
BA_ "GenSigAutoGenSnd" SG_ 1367 EKD_Sonderfahrzeug_SG_K 1;
BA_ "GenSigSendType" SG_ 1367 EKD_Sonderfahrzeug_SG_K 3;
BA_ "GenSigAutoGenDsp" SG_ 1367 EKD_Tastenmodul_I 1;
BA_ "GenSigAutoGenSnd" SG_ 1367 EKD_Tastenmodul_I 1;
BA_ "GenSigSendType" SG_ 1367 EKD_Tastenmodul_I 3;
BA_ "GenSigAutoGenDsp" SG_ 1367 EKD_Kompass_I 1;
BA_ "GenSigAutoGenSnd" SG_ 1367 EKD_Kompass_I 1;
BA_ "GenSigSendType" SG_ 1367 EKD_Kompass_I 0;
BA_ "GenSigAutoGenDsp" SG_ 1367 EKD_WFS_K 1;
BA_ "GenSigAutoGenSnd" SG_ 1367 EKD_WFS_K 1;
BA_ "GenSigSendType" SG_ 1367 EKD_WFS_K 3;
BA_ "GenSigAutoGenDsp" SG_ 1367 EKD_GSM_Pager_I 1;
BA_ "GenSigAutoGenSnd" SG_ 1367 EKD_GSM_Pager_I 1;
BA_ "GenSigSendType" SG_ 1367 EKD_GSM_Pager_I 3;
BA_ "GenSigAutoGenDsp" SG_ 1367 EKD_DSP_I 1;
BA_ "GenSigAutoGenSnd" SG_ 1367 EKD_DSP_I 1;
BA_ "GenSigSendType" SG_ 1367 EKD_DSP_I 3;
BA_ "GenSigAutoGenDsp" SG_ 1367 EKD_DAB_I 1;
BA_ "GenSigAutoGenSnd" SG_ 1367 EKD_DAB_I 1;
BA_ "GenSigSendType" SG_ 1367 EKD_DAB_I 3;
BA_ "GenSigAutoGenDsp" SG_ 1367 EKD_Telematik_I 1;
BA_ "GenSigAutoGenSnd" SG_ 1367 EKD_Telematik_I 1;
BA_ "GenSigSendType" SG_ 1367 EKD_Telematik_I 3;
BA_ "GenSigAutoGenDsp" SG_ 1367 EKD_Navigation_I 1;
BA_ "GenSigAutoGenSnd" SG_ 1367 EKD_Navigation_I 1;
BA_ "GenSigSendType" SG_ 1367 EKD_Navigation_I 3;
BA_ "GenSigAutoGenDsp" SG_ 1367 EKD_TV_Tuner_I 1;
BA_ "GenSigAutoGenSnd" SG_ 1367 EKD_TV_Tuner_I 1;
BA_ "GenSigSendType" SG_ 1367 EKD_TV_Tuner_I 3;
BA_ "GenSigAutoGenDsp" SG_ 1367 EKD_Neigungsmodul 1;
BA_ "GenSigAutoGenSnd" SG_ 1367 EKD_Neigungsmodul 1;
BA_ "GenSigSendType" SG_ 1367 EKD_Neigungsmodul 0;
BA_ "GenSigAutoGenDsp" SG_ 1367 EKD_Radio_I 1;
BA_ "GenSigAutoGenSnd" SG_ 1367 EKD_Radio_I 1;
BA_ "GenSigSendType" SG_ 1367 EKD_Radio_I 3;
BA_ "GenSigAutoGenDsp" SG_ 1367 EKD_Telefon_I 1;
BA_ "GenSigAutoGenSnd" SG_ 1367 EKD_Telefon_I 1;
BA_ "GenSigSendType" SG_ 1367 EKD_Telefon_I 3;
BA_ "GenSigAutoGenDsp" SG_ 1569 KO1_Tankstop 1;
BA_ "GenSigAutoGenSnd" SG_ 1569 KO1_Tankstop 1;
BA_ "GenSigSendType" SG_ 1569 KO1_Tankstop 0;
BA_ "GenSigAutoGenDsp" SG_ 1569 KO1_Tankwarnlampe 1;
BA_ "GenSigAutoGenSnd" SG_ 1569 KO1_Tankwarnlampe 1;
BA_ "GenSigSendType" SG_ 1569 KO1_Tankwarnlampe 0;
BA_ "GenSigAutoGenDsp" SG_ 1569 KO1_WaschWasser 1;
BA_ "GenSigAutoGenSnd" SG_ 1569 KO1_WaschWasser 1;
BA_ "GenSigSendType" SG_ 1569 KO1_WaschWasser 0;
BA_ "GenSigAutoGenDsp" SG_ 1569 KO1_MH_Kontakt 1;
BA_ "GenSigAutoGenSnd" SG_ 1569 KO1_MH_Kontakt 1;
BA_ "GenSigSendType" SG_ 1569 KO1_MH_Kontakt 0;
BA_ "GenSigAutoGenDsp" SG_ 1569 KO1_FT_geoeffnet 1;
BA_ "GenSigAutoGenSnd" SG_ 1569 KO1_FT_geoeffnet 1;
BA_ "GenSigSendType" SG_ 1569 KO1_FT_geoeffnet 0;
BA_ "GenSigAutoGenDsp" SG_ 1569 KO1_Handbremse 1;
BA_ "GenSigAutoGenSnd" SG_ 1569 KO1_Handbremse 1;
BA_ "GenSigSendType" SG_ 1569 KO1_Handbremse 0;
BA_ "GenSigAutoGenDsp" SG_ 1569 KO1_AFL 1;
BA_ "GenSigAutoGenSnd" SG_ 1569 KO1_AFL 1;
BA_ "GenSigSendType" SG_ 1569 KO1_AFL 0;
BA_ "GenSigAutoGenDsp" SG_ 1569 KO1_Klemme_L 1;
BA_ "GenSigAutoGenSnd" SG_ 1569 KO1_Klemme_L 1;
BA_ "GenSigSendType" SG_ 1569 KO1_Klemme_L 0;
BA_ "GenSigAutoGenDsp" SG_ 1569 KO1_Standzeit 1;
BA_ "GenSigAutoGenSnd" SG_ 1569 KO1_Standzeit 1;
BA_ "GenSigSendType" SG_ 1569 KO1_Standzeit 0;
BA_ "GenSigAutoGenDsp" SG_ 1569 KO1_Standzeit_Fehler 1;
BA_ "GenSigAutoGenSnd" SG_ 1569 KO1_Standzeit_Fehler 1;
BA_ "GenSigSendType" SG_ 1569 KO1_Standzeit_Fehler 0;
BA_ "GenSigAutoGenDsp" SG_ 1569 KO1_Tankinhalt 1;
BA_ "GenSigAutoGenSnd" SG_ 1569 KO1_Tankinhalt 1;
BA_ "GenSigSendType" SG_ 1569 KO1_Tankinhalt 0;
BA_ "Fehlerwert" SG_ 1569 KO1_Tankinhalt 127;
BA_ "GenSigAutoGenDsp" SG_ 1569 KO1_Tankwarnung 1;
BA_ "GenSigAutoGenSnd" SG_ 1569 KO1_Tankwarnung 1;
BA_ "GenSigSendType" SG_ 1569 KO1_Tankwarnung 0;
BA_ "GenSigAutoGenDsp" SG_ 1569 KO1_WFS_Schluessel 1;
BA_ "GenSigAutoGenSnd" SG_ 1569 KO1_WFS_Schluessel 1;
BA_ "GenSigSendType" SG_ 1569 KO1_WFS_Schluessel 0;
BA_ "GenSigAutoGenDsp" SG_ 1569 KO1_KD_Fehler_WFS 1;
BA_ "GenSigAutoGenSnd" SG_ 1569 KO1_KD_Fehler_WFS 1;
BA_ "GenSigSendType" SG_ 1569 KO1_KD_Fehler_WFS 0;
BA_ "GenSigAutoGenDsp" SG_ 1569 KO1_Fernlicht 1;
BA_ "GenSigAutoGenSnd" SG_ 1569 KO1_Fernlicht 1;
BA_ "GenSigSendType" SG_ 1569 KO1_Fernlicht 3;
BA_ "GenSigAutoGenDsp" SG_ 1569 KO1_Freigabe_Zuheizer 1;
BA_ "GenSigAutoGenSnd" SG_ 1569 KO1_Freigabe_Zuheizer 1;
BA_ "GenSigSendType" SG_ 1569 KO1_Freigabe_Zuheizer 0;
BA_ "GenSigAutoGenDsp" SG_ 1569 KO1_MFA_vorhanden 1;
BA_ "GenSigAutoGenSnd" SG_ 1569 KO1_MFA_vorhanden 1;
BA_ "GenSigSendType" SG_ 1569 KO1_MFA_vorhanden 0;
BA_ "GenSigAutoGenDsp" SG_ 1569 KO1_Bel_Displ 1;
BA_ "GenSigAutoGenSnd" SG_ 1569 KO1_Bel_Displ 1;
BA_ "GenSigSendType" SG_ 1569 KO1_Bel_Displ 0;
BA_ "GenSigAutoGenDsp" SG_ 1569 KO1_Sta_Displ 1;
BA_ "GenSigAutoGenSnd" SG_ 1569 KO1_Sta_Displ 1;
BA_ "GenSigSendType" SG_ 1569 KO1_Sta_Displ 0;
BA_ "GenSigAutoGenDsp" SG_ 1569 KO1_Lichtsensor 1;
BA_ "GenSigAutoGenSnd" SG_ 1569 KO1_Lichtsensor 1;
BA_ "GenSigSendType" SG_ 1569 KO1_Lichtsensor 3;
BA_ "GenSigStartValue" SG_ 1569 KO1_Lichtsensor 254;
BA_ "Fehlerwert" SG_ 1569 KO1_Lichtsensor 255;
BA_ "GenSigAutoGenDsp" SG_ 1571 KO2_DCF 1;
BA_ "GenSigAutoGenSnd" SG_ 1571 KO2_DCF 1;
BA_ "GenSigSendType" SG_ 1571 KO2_DCF 0;
BA_ "GenSigAutoGenDsp" SG_ 1571 KO2_Reset 1;
BA_ "GenSigAutoGenSnd" SG_ 1571 KO2_Reset 1;
BA_ "GenSigSendType" SG_ 1571 KO2_Reset 0;
BA_ "GenSigAutoGenDsp" SG_ 1571 KO2_24h_Anzeige 1;
BA_ "GenSigAutoGenSnd" SG_ 1571 KO2_24h_Anzeige 1;
BA_ "GenSigSendType" SG_ 1571 KO2_24h_Anzeige 0;
BA_ "GenSigAutoGenDsp" SG_ 1571 KO2_WeckzSH_OK 1;
BA_ "GenSigAutoGenSnd" SG_ 1571 KO2_WeckzSH_OK 1;
BA_ "GenSigSendType" SG_ 1571 KO2_WeckzSH_OK 0;
BA_ "GenSigAutoGenDsp" SG_ 1571 KO2_QV 1;
BA_ "GenSigAutoGenSnd" SG_ 1571 KO2_QV 1;
BA_ "GenSigSendType" SG_ 1571 KO2_QV 0;
BA_ "GenSigAutoGenDsp" SG_ 1571 KO2_Stunde 1;
BA_ "GenSigAutoGenSnd" SG_ 1571 KO2_Stunde 1;
BA_ "GenSigSendType" SG_ 1571 KO2_Stunde 0;
BA_ "GenSigAutoGenDsp" SG_ 1571 KO2_Minute 1;
BA_ "GenSigAutoGenSnd" SG_ 1571 KO2_Minute 1;
BA_ "GenSigSendType" SG_ 1571 KO2_Minute 0;
BA_ "GenSigAutoGenDsp" SG_ 1571 KO2_Sekunde 1;
BA_ "GenSigAutoGenSnd" SG_ 1571 KO2_Sekunde 1;
BA_ "GenSigSendType" SG_ 1571 KO2_Sekunde 0;
BA_ "GenSigAutoGenDsp" SG_ 1571 KO2_Tag 1;
BA_ "GenSigAutoGenSnd" SG_ 1571 KO2_Tag 1;
BA_ "GenSigSendType" SG_ 1571 KO2_Tag 0;
BA_ "GenSigAutoGenDsp" SG_ 1571 KO2_Monat 1;
BA_ "GenSigAutoGenSnd" SG_ 1571 KO2_Monat 1;
BA_ "GenSigSendType" SG_ 1571 KO2_Monat 0;
BA_ "GenSigAutoGenDsp" SG_ 1571 KO2_Jahrhundert 1;
BA_ "GenSigAutoGenSnd" SG_ 1571 KO2_Jahrhundert 1;
BA_ "GenSigSendType" SG_ 1571 KO2_Jahrhundert 0;
BA_ "GenSigAutoGenDsp" SG_ 1571 KO2_Jahr 1;
BA_ "GenSigAutoGenSnd" SG_ 1571 KO2_Jahr 1;
BA_ "GenSigSendType" SG_ 1571 KO2_Jahr 0;
BA_ "GenSigAutoGenDsp" SG_ 1573 KO3_SC_1 1;
BA_ "GenSigAutoGenSnd" SG_ 1573 KO3_SC_1 1;
BA_ "GenSigSendType" SG_ 1573 KO3_SC_1 5;
BA_ "GenSigAutoGenDsp" SG_ 1573 KO3_SC_2 1;
BA_ "GenSigAutoGenSnd" SG_ 1573 KO3_SC_2 1;
BA_ "GenSigSendType" SG_ 1573 KO3_SC_2 5;
BA_ "GenSigAutoGenDsp" SG_ 1573 KO3_SC_3 1;
BA_ "GenSigAutoGenSnd" SG_ 1573 KO3_SC_3 1;
BA_ "GenSigSendType" SG_ 1573 KO3_SC_3 5;
BA_ "GenSigAutoGenDsp" SG_ 1573 KO3_SC_4 1;
BA_ "GenSigAutoGenSnd" SG_ 1573 KO3_SC_4 1;
BA_ "GenSigSendType" SG_ 1573 KO3_SC_4 5;
BA_ "GenSigAutoGenDsp" SG_ 1573 KO3_Ziel 1;
BA_ "GenSigAutoGenSnd" SG_ 1573 KO3_Ziel 1;
BA_ "GenSigSendType" SG_ 1573 KO3_Ziel 5;
BA_ "GenSigAutoGenDsp" SG_ 1575 KO4_Disp_Request 1;
BA_ "GenSigAutoGenSnd" SG_ 1575 KO4_Disp_Request 1;
BA_ "GenSigSendType" SG_ 1575 KO4_Disp_Request 3;
BA_ "GenSigAutoGenDsp" SG_ 1575 KO4_Disp_Ack 1;
BA_ "GenSigAutoGenSnd" SG_ 1575 KO4_Disp_Ack 1;
BA_ "GenSigSendType" SG_ 1575 KO4_Disp_Ack 3;
BA_ "GenSigAutoGenDsp" SG_ 1575 KO4_Disp_Busy 1;
BA_ "GenSigAutoGenSnd" SG_ 1575 KO4_Disp_Busy 1;
BA_ "GenSigSendType" SG_ 1575 KO4_Disp_Busy 3;
BA_ "GenSigAutoGenDsp" SG_ 1575 KO4_code_no_ack 1;
BA_ "GenSigAutoGenSnd" SG_ 1575 KO4_code_no_ack 1;
BA_ "GenSigSendType" SG_ 1575 KO4_code_no_ack 3;
BA_ "GenSigAutoGenDsp" SG_ 1575 KO4_Disp_Ft_auf 1;
BA_ "GenSigAutoGenSnd" SG_ 1575 KO4_Disp_Ft_auf 1;
BA_ "GenSigSendType" SG_ 1575 KO4_Disp_Ft_auf 3;
BA_ "GenSigAutoGenDsp" SG_ 1575 KO4_User_field1 1;
BA_ "GenSigAutoGenSnd" SG_ 1575 KO4_User_field1 1;
BA_ "GenSigSendType" SG_ 1575 KO4_User_field1 3;
BA_ "GenSigAutoGenDsp" SG_ 1575 KO4_User_field2 1;
BA_ "GenSigAutoGenSnd" SG_ 1575 KO4_User_field2 1;
BA_ "GenSigSendType" SG_ 1575 KO4_User_field2 3;
BA_ "GenSigAutoGenDsp" SG_ 1575 KO4_User_field3 1;
BA_ "GenSigAutoGenSnd" SG_ 1575 KO4_User_field3 1;
BA_ "GenSigSendType" SG_ 1575 KO4_User_field3 3;
BA_ "GenSigAutoGenDsp" SG_ 1575 KO4_User_field4 1;
BA_ "GenSigAutoGenSnd" SG_ 1575 KO4_User_field4 1;
BA_ "GenSigSendType" SG_ 1575 KO4_User_field4 3;
BA_ "GenSigAutoGenDsp" SG_ 1575 KO4_User_field5 1;
BA_ "GenSigAutoGenSnd" SG_ 1575 KO4_User_field5 1;
BA_ "GenSigSendType" SG_ 1575 KO4_User_field5 3;
BA_ "GenSigAutoGenDsp" SG_ 1575 KO4_User_field6 1;
BA_ "GenSigAutoGenSnd" SG_ 1575 KO4_User_field6 1;
BA_ "GenSigSendType" SG_ 1575 KO4_User_field6 3;
BA_ "GenSigAutoGenDsp" SG_ 1575 KO4_User_field7 1;
BA_ "GenSigAutoGenSnd" SG_ 1575 KO4_User_field7 1;
BA_ "GenSigSendType" SG_ 1575 KO4_User_field7 3;
BA_ "GenSigAutoGenDsp" SG_ 1479 KOM_Norden 1;
BA_ "GenSigAutoGenSnd" SG_ 1479 KOM_Norden 1;
BA_ "GenSigSendType" SG_ 1479 KOM_Norden 0;
BA_ "GenSigAutoGenDsp" SG_ 1479 KOM_NordOst 1;
BA_ "GenSigAutoGenSnd" SG_ 1479 KOM_NordOst 1;
BA_ "GenSigSendType" SG_ 1479 KOM_NordOst 0;
BA_ "GenSigAutoGenDsp" SG_ 1479 KOM_Ost 1;
BA_ "GenSigAutoGenSnd" SG_ 1479 KOM_Ost 1;
BA_ "GenSigSendType" SG_ 1479 KOM_Ost 0;
BA_ "GenSigAutoGenDsp" SG_ 1479 KOM_SuedOst 1;
BA_ "GenSigAutoGenSnd" SG_ 1479 KOM_SuedOst 1;
BA_ "GenSigSendType" SG_ 1479 KOM_SuedOst 0;
BA_ "GenSigAutoGenDsp" SG_ 1479 KOM_Sued 1;
BA_ "GenSigAutoGenSnd" SG_ 1479 KOM_Sued 1;
BA_ "GenSigSendType" SG_ 1479 KOM_Sued 0;
BA_ "GenSigAutoGenDsp" SG_ 1479 KOM_SuedWest 1;
BA_ "GenSigAutoGenSnd" SG_ 1479 KOM_SuedWest 1;
BA_ "GenSigSendType" SG_ 1479 KOM_SuedWest 0;
BA_ "GenSigAutoGenDsp" SG_ 1479 KOM_West 1;
BA_ "GenSigAutoGenSnd" SG_ 1479 KOM_West 1;
BA_ "GenSigSendType" SG_ 1479 KOM_West 0;
BA_ "GenSigAutoGenDsp" SG_ 1479 KOM_NordWest 1;
BA_ "GenSigAutoGenSnd" SG_ 1479 KOM_NordWest 1;
BA_ "GenSigSendType" SG_ 1479 KOM_NordWest 0;
BA_ "GenSigAutoGenDsp" SG_ 1479 KOM_Zone 1;
BA_ "GenSigAutoGenSnd" SG_ 1479 KOM_Zone 1;
BA_ "GenSigSendType" SG_ 1479 KOM_Zone 0;
BA_ "GenSigAutoGenDsp" SG_ 1479 KOM_Calibriert 1;
BA_ "GenSigAutoGenSnd" SG_ 1479 KOM_Calibriert 1;
BA_ "GenSigSendType" SG_ 1479 KOM_Calibriert 0;
BA_ "GenSigAutoGenDsp" SG_ 1479 KOM_CALaktiv 1;
BA_ "GenSigAutoGenSnd" SG_ 1479 KOM_CALaktiv 1;
BA_ "GenSigSendType" SG_ 1479 KOM_CALaktiv 0;
BA_ "GenSigAutoGenDsp" SG_ 1479 KOM_Grad 1;
BA_ "GenSigAutoGenSnd" SG_ 1479 KOM_Grad 1;
BA_ "GenSigSendType" SG_ 1479 KOM_Grad 0;
BA_ "GenSigAutoGenDsp" SG_ 1479 KOM_Stoerfeld 1;
BA_ "GenSigAutoGenSnd" SG_ 1479 KOM_Stoerfeld 1;
BA_ "GenSigSendType" SG_ 1479 KOM_Stoerfeld 0;
BA_ "GenSigAutoGenDsp" SG_ 1479 KOM_ASIC_Fehler 1;
BA_ "GenSigAutoGenSnd" SG_ 1479 KOM_ASIC_Fehler 1;
BA_ "GenSigSendType" SG_ 1479 KOM_ASIC_Fehler 0;
BA_ "GenSigAutoGenDsp" SG_ 1479 KOM_Fehler3 1;
BA_ "GenSigAutoGenSnd" SG_ 1479 KOM_Fehler3 1;
BA_ "GenSigSendType" SG_ 1479 KOM_Fehler3 0;
BA_ "GenSigAutoGenDsp" SG_ 1479 KOM_Fehler4 1;
BA_ "GenSigAutoGenSnd" SG_ 1479 KOM_Fehler4 1;
BA_ "GenSigSendType" SG_ 1479 KOM_Fehler4 0;
BA_ "GenSigAutoGenDsp" SG_ 1479 KOM_Fehler5 1;
BA_ "GenSigAutoGenSnd" SG_ 1479 KOM_Fehler5 1;
BA_ "GenSigSendType" SG_ 1479 KOM_Fehler5 0;
BA_ "GenSigAutoGenDsp" SG_ 1479 KOM_Fehler6 1;
BA_ "GenSigAutoGenSnd" SG_ 1479 KOM_Fehler6 1;
BA_ "GenSigSendType" SG_ 1479 KOM_Fehler6 0;
BA_ "GenSigAutoGenDsp" SG_ 1479 KOM_Fehler7 1;
BA_ "GenSigAutoGenSnd" SG_ 1479 KOM_Fehler7 1;
BA_ "GenSigSendType" SG_ 1479 KOM_Fehler7 0;
BA_ "GenSigAutoGenDsp" SG_ 1479 KOM_KD_Fehler 1;
BA_ "GenSigAutoGenSnd" SG_ 1479 KOM_KD_Fehler 1;
BA_ "GenSigSendType" SG_ 1479 KOM_KD_Fehler 0;
VAL_ 995 CL2_Sonne_links 255 "Fehler" ;
VAL_ 995 CL2_Sonne_rechts 255 "Fehler" ;
VAL_ 995 CL2_InnenTemp 255 "Fehler" ;
VAL_ 995 CL2_StSt_Info 3 "Systemfehler" 0 "Motorlauf_nn" 1 "Stoppverbot_Motoranlauf_nn" 2 "Motoranlauf_notwendig" ;
VAL_ 995 CL2_SL_LED 1 "Lampe_ein" 0 "Lampe_aus" ;
VAL_ 995 CL2_Solltemperatur 255 "Fehler" ;
VAL_ 995 CL2_Vorgabe_KWTemp 255 "Fehler" ;
VAL_ 1507 CL4_VL_Ist_Temp 255 "Fehler" ;
VAL_ 1507 CL4_Deltatemp 0 "Bregrenzung_nicht_verwendet" ;
VAL_ 1507 CL4_V_Gebl_AutoMan 0 "Automatik" 1 "Manuell" ;
VAL_ 1507 CL4_H_Gebl_AutoMan 0 "Automatik" 1 "Manuell" ;
VAL_ 1634 DA1_DAB_Error_flag 1 "Fehlerspeichereintrag" 0 "kein_Fehlerspeichereintrag" ;
VAL_ 1629 DN1_Verlernzaehler 255 "Fehler" ;
VAL_ 1629 DN1_Monat 14 "relatives_Datum" 15 "Spezialfall" 13 "ungueltig" 0 "ungueltig" ;
VAL_ 1629 DN1_Stunde 31 "ungueltig" 26 "ungueltig" 28 "ungueltig" 30 "ungueltig" 29 "ungueltig" 25 "ungueltig" 24 "ungueltig" 27 "ungueltig" ;
VAL_ 1629 DN1_Minute 62 "ungueltig" 63 "ungueltig" 60 "ungueltig" 61 "ungueltig" ;
VAL_ 1629 DN1_Sekunde 62 "ungueltig" 63 "ungueltig" 60 "ungueltig" 61 "ungueltig" ;
VAL_ 1629 DN1_alt_Kilometerstand 1 "veraltet" 0 "aktuell_empfangen" ;
VAL_ 1629 DN1_alt_Zeit 1 "veraltet" 0 "aktuell_empfangen" ;
VAL_ 1589 DI1_Display 127 "Fehler" ;
VAL_ 1589 DI1_Display_def 0 "Kl_58d_i_O" 1 "Kl_58d_n_i_O" ;
VAL_ 1589 DI1_Schalter 127 "Fehler" ;
VAL_ 1589 DI1_Schalter_def 0 "Kl_58s_i_O" 1 "Kl_58_s_n_i_O" ;
VAL_ 1589 DI1_Sensor 254 "INIT" 255 "Fehler" ;
VAL_ 1391 SD1_DSP_Type 8 "DSP_BAP_0" 7 "DSP_Booster_2" 2 "analog_CAN_Amp_8Ch" 6 "DSP_Booster_1" 5 "DSP_Booster_0" 9 "DSP_BAP_1" 3 "digital_CAN_Amp_12Ch" 13 "DSP_BAP_SF_2" 0 "no_Type" 12 "DSP_BAP_SF_1" 10 "DSP_BAP_2" 1 "analog_Amp_8Ch" 4 "digital_Amp_10Ch" 11 "DSP_BAP_SF_0" ;
VAL_ 1391 SD1_KD_Fehler 1 "Fehlerspeichereintrag" 0 "kein_Fehlerspeichereintrag" ;
VAL_ 1550 EH1_Einh_Strck 0 "km" 1 "mls" ;
VAL_ 1550 EH1_Einh_Temp 0 "Grad_C" 1 "Grad_F" ;
VAL_ 1550 EH1_Einh_Vol 1 "gallons" 0 "liter" ;
VAL_ 1550 EH1_Einh_Verbr 0 "Strecke_Vol" 1 "Vol_Strecke" ;
VAL_ 1550 EH1_Einh_Druck 0 "bar" 3 "kPa" 1 "psi" 2 "nn" ;
VAL_ 1550 EH1_Datum_Anzeige 0 "TT_MM_JJJJ" 1 "MM_TT_JJJJ" ;
VAL_ 1550 EH1_Uhr_Anzeige 0 "24h_Anz" 1 "12h_Anz" ;
VAL_ 1550 EH1_Wochentag 3 "Mi" 7 "So" 1 "Mo" 0 "Init" 4 "Do" 6 "Sa" 5 "Fr" 2 "Di" ;
VAL_ 1550 EH1_Verstellung_Strck 1 "ja" 0 "nein" ;
VAL_ 1471 MFL_Tastencode_1 5 "Down" 20 "Audio_Source" 2 "Menu_Up__Next_Screen" 3 "Menu_Down__Previous_Screen" 7 "OK__ThumbWheel_Button" 8 "Cancel__Escape" 21 "Arrow_A_Up__Right" 22 "Arrow_A_Down__Left" 6 "Up__Down_ThumbWheel" 0 "Key_Released__No_Key" 16 "Volume_Up" 19 "Volume_ThumbWheel_Button" 18 "Volume_Up__Down_ThumbWheel" 4 "Up" 17 "Volume_Down" 1 "Menu" 29 "Hang_Up" 240 "Startup_Reset" 28 "Hook" 30 "Off_Hook" 24 "Arrow_B_Down__Left" 26 "PPT_Cancel" 27 "Route_Info" 25 "PTT__PushToTalk" 33 "Joker1" 23 "Arrow_B_Up__Right" 34 "Joker2" 31 "Light_On__Off" 32 "Mute" ;
VAL_ 1471 MFL_Tastencode_2 20 "Audio_Source" 21 "Arrow_A_Up__Right" 16 "Volume_Up" 6 "Up__Down_ThumbWheel" 4 "Up" 17 "Volume_Down" 3 "Menu_Down__Previous_Screen" 18 "Volume_Up__Down_ThumbWheel" 5 "Down" 1 "Menu" 0 "Key_Released__No_Key" 8 "Cancel__Escape" 7 "OK__ThumbWheel_Button" 2 "Menu_Up__Next_Screen" 22 "Arrow_A_Down__Left" 19 "Volume_ThumbWheel_Button" 30 "Off_Hook" 33 "Joker1" 28 "Hook" 23 "Arrow_B_Up__Right" 25 "PPT__PushToTalk" 24 "Arrow_B_Down__Left" 240 "Startup_Reset" 29 "Hang_Up" 31 "Light_On__Off" 26 "PPT_Cancel" 34 "Joker2" 32 "Mute" 27 "Route_Info" ;
VAL_ 1471 MFL_Eventcode_1 6 "Walze: 6 Ticks up   | Taste: long-press 3 [3s]" 7 "Walze: 7 Ticks up   |" 13 "Walze: 3 Ticks down |" 4 "Walze: 4 Ticks up   | Taste: long-press 1 [800ms]" 2 "Walze: 2 Ticks up   | " 11 "Walze: 5 Ticks down |" 12 "Walze: 4 Ticks down |" 10 "Walze: 6 Ticks down |" 14 "Walze: 2 Ticks down |" 3 "Walze: 3 Ticks up   | Taste: double-click" 9 "Walze: 7 Ticks down |" 0 "Walze: no Event     | Taste: no Event" 5 "Walze: 5 Ticks up   | Taste: long-press 2 [2s]" 1 "Walze: 1 Tick  up   | Taste: pressed" 15 "Walze: 1 Tick  down |" ;
VAL_ 1471 MFL_Eventcode_2 4 "Walze: 4 Ticks up   | Taste: long-press 1 [800ms]" 7 "Walze: 7 Ticks up   |" 11 "Walze: 5 Ticks down |" 5 "Walze: 5 Ticks up   | Taste: long-press 2 [2s]" 0 "Walze: no Event     | Taste: no Event" 6 "Walze: 6 Ticks up   | Taste: long-press 3 [3s]" 3 "Walze: 3 Ticks up   | Taste: double-click" 9 "Walze: 7 Ticks down |" 14 "Walze: 2 Ticks down |" 13 "Walze: 3 Ticks down |" 15 "Walze: 1 Tick  down |" 10 "Walze: 6 Ticks down |" 12 "Walze: 4 Ticks down |" 2 "Walze: 2 Ticks up   |  " 1 "Walze: 1 Tick  up   | Taste: pressed" ;
VAL_ 1471 MFL_Marke 2 "Seat" 8 "Rolls_Royce" 14 "Ford" 5 "Bugatti" 15 "Porsche" 1 "Audi" 6 "Lamborghini" 3 "Skoda" 0 "VW" 7 "Bentley" 4 "VW_Nutzf" 12 "kein_Hersteller_3" 10 "kein_Hersteller_1" 13 "kein_Hersteller_4" 11 "kein_Hersteller_2" 9 "Quattro" ;
VAL_ 849 GW1_FhzgGeschw_alt 1 "veraltet" 0 "aktuell_empfangen" ;
VAL_ 849 GW1_Rueckfahrlicht 1 "Rueckfahrlicht_ein" ;
VAL_ 849 GW1_FzgGeschw 32725 "Unterspannung" 32708 "Init_PQ25_35_46" 32742 "Sensorfehler" ;
VAL_ 849 KKO_alt_mBSG_Kombi 1 "veraltet" 0 "aktuell_empfangen" ;
VAL_ 1619 GW3_Laendervariante 6 "Saudi_Arabien" 5 "Japan" 0 "Deutschland" 7 "Australien" 3 "Kanada" 1 "Europa" 2 "USA" 4 "Grossbritannien" ;
VAL_ 1619 GW3_Alt_3_Kombi 1 "veraltet" 0 "aktuell_empfangen" ;
VAL_ 1619 GW3_Land_Sprach_empf 0 "Inhalt_nicht_empfangen" 1 "Aktuell_empfangen" ;
VAL_ 1619 GW3_Sprachvariante 4 "Italienisch" 0 "keine_Sprachvar" 6 "Portugiesisch" 11 "Niederlaendisch" 10 "US_Englisch" 9 "Chinesisch" 1 "Deutsch" 5 "Spanisch" 2 "Englisch" 12 "Japanisch" 13 "Russisch" 15 "Franko_Kanadisch" 14 "Koreanisch" 8 "Tschechisch" 3 "Franzoesisch" 16 "Schwedisch" 18 "Türkisch" 17 "Polnisch" ;
VAL_ 1619 GW3_Alt_5_Motor 1 "veraltet" 0 "aktuell_empfangen" ;
VAL_ 1619 GW3_Motortyp_empf 1 "Aktuell_empfangen" 0 "Inhalt_nicht_empfangen" ;
VAL_ 1487 GS1_Error_flag 1 "Fehlerspeichereintrag" 0 "kein_Fehlerspeichereintrag" ;
VAL_ 857 GWB_Alt_FzgGeschw 1 "veraltet" 0 "aktuell_empfangen" ;
VAL_ 857 GWB_Alt_2_Bremse 1 "veraltet" 0 "aktuell_empfangen" ;
VAL_ 857 GWB_Alt_1_Bremse 1 "veraltet" 0 "aktuell_empfangen" ;
VAL_ 857 GWB_Alt_1_Getriebe 1 "veraltet" 0 "aktuell_empfangen" ;
VAL_ 857 GWB_Alt_2_Getriebe 1 "veraltet" 0 "aktuell_empfangen" ;
VAL_ 857 GWB_Alt_1_EPB 1 "veraltet" 0 "aktuell_empfangen" ;
VAL_ 857 GWB_Alt_5_Bremse 1 "veraltet" 0 "aktuell_empfangen" ;
VAL_ 857 GWB_Alt_AWV_X 1 "veraltet" 0 "aktuell_empfangen" ;
VAL_ 857 GWB_FzgGeschw_Quelle 1 "ABS" 0 "kein_ABS" ;
VAL_ 857 GWB_FzgGeschw 32725 "Unterspannung" 32708 "Init_PQ25_35_46" 32742 "Sensorfehler" ;
VAL_ 857 GWB_Wegimpuls_Status 0 "Reset_und_kein_Ueberlauf" 1 "mind_1mal_Ueberlauf" ;
VAL_ 857 GWB_Wegimpulse_Fehler 0 "Wegimpulse_i_O" 1 "Fehler" ;
VAL_ 857 GWB_Alt_PLA_Status 1 "veraltet" 0 "aktuell_empfangen" ;
VAL_ 857 PLS_Bremsleuchte 1 "Bremsleuchte_ein" 0 "Bremsleuchte_aus" ;
VAL_ 857 GWB_TSP_aktiv 1 "Bremslicht_an" 0 "keine_Bremslichtanforderung" ;
VAL_ 857 GWB_Notbremsung 0 "keine_Notbremsung" 1 "Notbremsung_erk" ;
VAL_ 857 GWB_ABS_Bremsung 0 "keine_ABS_Regelung" 1 "ABS_Regelung" ;
VAL_ 857 GWB_EPB_Status 1 "Bremse_geschlossen" 0 "Bremse_geoeffnet" ;
VAL_ 857 GWB_EPB_Bremslicht 1 "Ein" 0 "Aus" ;
VAL_ 857 GWB_Schlechtweg 1 "Ausblendung" 0 "keine_Ausblendung" ;
VAL_ 857 GWB_Schlechtweg_Fehler 1 "ungueltig" 0 "gueltig" ;
VAL_ 857 GWB_Geschw_Ersatz 1 "Ersatzwert" 0 "i_O" ;
VAL_ 857 GWB_Schaltvorgang 1 "Schaltung_laeuft" 0 "keine_Schaltung" ;
VAL_ 857 ANB_Teilbremsung_Freigabe 1 "Teilbremsung_freigegeben" 0 "Teilbremsung_nicht_freigegeben" ;
VAL_ 857 GWB_ESP_Eingriff 0 "kein_ESP_Eingriff" 1 "ESP_Eingriff" ;
VAL_ 857 GWB_Shift_Lock 1 "Lampe_ein" 0 "Lampe_aus" ;
VAL_ 857 GWB_Info_Waehlhebel 12 "Pos_S_Automatic_Sport" 6 "Pos_N" 7 "Pos_R" 3 "Pos_3" 4 "Pos_4" 1 "Pos_1" 2 "Pos_2" 5 "Pos_D_Automatic" 13 "Pos_L" 10 "Pos_Z1" 9 "Pos_RSP_Manual_Sport" 0 "Zwischenstellung" 8 "Pos_P_Key_Lock_Release" 14 "Tipp_Gasse_Manual" 11 "Pos_Z2" 15 "Fehler" ;
VAL_ 1315 GWI_alt_ZKE_4 1 "veraltet" 0 "aktuell_empfangen" ;
VAL_ 1315 GWI_alt_ZKE_3 1 "veraltet" 0 "aktuell_empfangen" ;
VAL_ 1315 GWI_alt_Kombi_1 1 "veraltet" 0 "aktuell_empfangen" ;
VAL_ 1315 GWI_res3 1 "veraltet" 0 "aktuell_empfangen" ;
VAL_ 1315 GWI_res4 1 "veraltet" 0 "aktuell_empfangen" ;
VAL_ 1315 GWI_res5 1 "veraltet" 0 "aktuell_empfangen" ;
VAL_ 1315 GWI_res6 1 "veraltet" 0 "aktuell_empfangen" ;
VAL_ 1315 GWI_res7 1 "veraltet" 0 "aktuell_empfangen" ;
VAL_ 1315 GWI_Status_Verdeck 0 "geschlossen" 1 "offen" ;
VAL_ 1315 KB1_angez_kmh 1020 "Fehler" ;
VAL_ 1319 GWK_Alt_3_Kombi 1 "veraltet" 0 "aktuell_empfangen" ;
VAL_ 1319 GWK_Alt_2_Kombi 1 "veraltet" 0 "aktuell_empfangen" ;
VAL_ 1319 GWK_Alt_1_Kombi 1 "veraltet" 0 "aktuell_empfangen" ;
VAL_ 1319 GWK_Reifenumfang_empf 0 "Inhalt_nicht_empfangen" 1 "Aktuell_empfangen" ;
VAL_ 1319 GWK_FzgGeschw_Quelle 0 "Tachogeber" 1 "ABS_Signale" ;
VAL_ 1319 GWK_AussenTemp_gefiltert 255 "Fehler" ;
VAL_ 1319 GWK_AussenTemp_ungefiltert 255 "Fehler" ;
VAL_ 1319 GWK_AussenTemp_Fehler 1 "n_iO" 0 "iO" ;
VAL_ 1319 GWK_Warn_Heiss 1 "Warnung" 0 "keine_Warnung" ;
VAL_ 1319 GWK_Passiv_Autolock 0 "inaktiv" 1 "aktiv" ;
VAL_ 1319 GWK_WFS_Schl_Ort 0 "keyless" 1 "Lesespule" ;
VAL_ 1319 KB1_Lenkh_Lampe 1 "Lampe_ein" 0 "Lampe_aus" ;
VAL_ 859 GWM_Alt_1_Motor 1 "veraltet" 0 "aktuell_empfangen" ;
VAL_ 859 GWM_Alt_2_Motor 1 "veraltet" 0 "aktuell_empfangen" ;
VAL_ 859 GWM_Alt_5_Motor 1 "veraltet" 0 "aktuell_empfangen" ;
VAL_ 859 GWM_Alt_Motor_Bremse 1 "veraltet" 0 "aktuell_empfangen" ;
VAL_ 859 GWM_RME_Gehalt 7 "Fehler" ;
VAL_ 859 GWM_Motordrehzahl 65280 "Fehler" ;
VAL_ 859 GWM_KuehlmittelTemp 0 "Init" 255 "Fehler" ;
VAL_ 859 GWM_Bremslicht_Schalter 1 "Bremse_betaetigt" 0 "kein_Bremsen" ;
VAL_ 859 GWM_Bremstest_Schalter 0 "kein_Bremsen" 1 "Bremse_betaetigt" ;
VAL_ 859 GWM_Fehl_KmittelTemp 0 "Temperatur_iO" 1 "Temperatur_n_iO" ;
VAL_ 859 GWM_Kuppl_Schalter 1 "Schalter_sagt_eingekuppelt" 0 "Schalter_sagt_ausgekuppelt" ;
VAL_ 859 GWM_Heissl_Vorwarn 0 "keine_Warnung" 1 "Vorwarnung" ;
VAL_ 859 GWM_Klimaabschaltung 1 "Klimakompr_aus" 0 "keine_Anforderung" ;
VAL_ 859 GWM_Kennfeldkuehlung 1 "ja" 0 "nein" ;
VAL_ 859 GWM_Komp_Leist_red 1 "ja" 0 "nein" ;
VAL_ 859 GWM_KLuefter 0 "keine_Anforderung" 255 "Fehler" ;
VAL_ 859 GWM_Anl_Freigabe 1 "Startfreigabe" 0 "Start_nicht_zulaessig" ;
VAL_ 859 GWM_Anl_Ausspuren 0 "Motor_laeuft_nicht_stabil" 1 "Anlasser_ausspuren" ;
VAL_ 859 GWM_Interlock 1 "Interlock_betaetigt" 0 "Interlock_nicht_betaetigt" ;
VAL_ 859 GWM_TypStartSteu 1 "Automatikstart" 0 "Start_BSG_Kessy_oder_Fahrer" ;
VAL_ 859 GWM_Freig_Bremsanforderung 1 "Bremsanf_freigegeben" 0 "Bremsanf_nicht_freigegeb" ;
VAL_ 859 GWM_Vorgluehen 1 "Lampe_ein" 0 "Lampe_aus" ;
VAL_ 859 GWM_GRA_Status 2 "uebersteuert_Lampe_an" 0 "ADR_GRA_aus" 3 "ADR_nicht_freigegeben" 1 "aktiviert_Lampe_an" ;
VAL_ 859 GWM_Ueberl_KV 1 "mindestens_einmal_uebergelaufen" 0 "kein_Ueberlauf" ;
VAL_ 1367 EKD_Motor_A 1 "Fehlerspeichereintrag" 0 "kein_Fehlerspeichereintrag" ;
VAL_ 1367 EKD_Getriebe_A 1 "Fehlerspeichereintrag" 0 "kein_Fehlerspeichereintrag" ;
VAL_ 1367 EKD_Bremse_A 1 "Fehlerspeichereintrag" 0 "kein_Fehlerspeichereintrag" ;
VAL_ 1367 EKD_Kombi_A 1 "Fehlerspeichereintrag" 0 "kein_Fehlerspeichereintrag" ;
VAL_ 1367 EKD_LSM_A 1 "Fehlerspeichereintrag" 0 "kein_Fehlerspeichereintrag" ;
VAL_ 1367 EKD_Airbag_A 1 "Fehlerspeichereintrag" 0 "kein_Fehlerspeichereintrag" ;
VAL_ 1367 EKD_Lenkhilfe_A 1 "Fehlerspeichereintrag" 0 "kein_Fehlerspeichereintrag" ;
VAL_ 1367 EKD_dyn_LWR_A 1 "Fehlerspeichereintrag" 0 "kein_Fehlerspeichereintrag" ;
VAL_ 1367 EKD_Niveau_A 1 "Fehlerspeichereintrag" 0 "kein_Fehlerspeichereintrag" ;
VAL_ 1367 EKD_Allrad_A 1 "Fehlerspeichereintrag" 0 "kein_Fehlerspeichereintrag" ;
VAL_ 1367 EKD_ADR_Sensor_A 1 "Fehlerspeichereintrag" 0 "kein_Fehlerspeichereintrag" ;
VAL_ 1367 EKD_ADR_getrennt 1 "ADR_getrennt" 0 "ADR_angeschlossen" ;
VAL_ 1367 EKD_Parkbremse_A 1 "Fehlerspeichereintrag" 0 "kein_Fehlerspeichereintrag" ;
VAL_ 1367 EKD_EZS_A 1 "Fehlerspeichereintrag" 0 "kein_Fehlerspeichereintrag" ;
VAL_ 1367 EKD_Daempfer_A 1 "Fehlerspeichereintrag" 0 "kein_Fehlerspeichereintrag" ;
VAL_ 1367 EKD_Quersperre 1 "Fehlerspeichereintrag" 0 "kein_Fehlerspeichereintrag" ;
VAL_ 1367 EKD_Motor_Slave_A 1 "Fehlerspeichereintrag" 0 "kein_Fehlerspeichereintrag" ;
VAL_ 1367 EKD_SWA_A 1 "Fehlerspeichereintrag" 0 "kein_Fehlerspeichereintrag" ;
VAL_ 1367 EKD_LDW_A 1 "Fehlerspeichereintrag" 0 "kein_Fehlerspeichereintrag" ;
VAL_ 1367 EKD_RKA_Plus_A 1 "Fehlerspeichereintrag" 0 "kein_Fehlerspeichereintrag" ;
VAL_ 1367 EKD_PLA_A 1 "Fehlerspeichereintrag" 0 "kein_Fehlerspeichereintrag" ;
VAL_ 1367 EKD_WFS_KBI 1 "Fehlerspeichereintrag" 0 "kein_Fehlerspeichereintrag" ;
VAL_ 1367 EKD_Kombi_KBI 1 "Fehlerspeichereintrag" 0 "kein_Fehlerspeichereintrag" ;
VAL_ 1367 EKD_BSG_K 1 "Fehlerspeichereintrag" 0 "kein_Fehlerspeichereintrag" ;
VAL_ 1367 EKD_KSG_K 1 "Fehlerspeichereintrag" 0 "kein_Fehlerspeichereintrag" ;
VAL_ 1367 EKD_TSG_FT_K 1 "Fehlerspeichereintrag" 0 "kein_Fehlerspeichereintrag" ;
VAL_ 1367 EKD_TSG_BT_K 1 "Fehlerspeichereintrag" 0 "kein_Fehlerspeichereintrag" ;
VAL_ 1367 EKD_TSG_HL_K 1 "Fehlerspeichereintrag" 0 "kein_Fehlerspeichereintrag" ;
VAL_ 1367 EKD_TSG_HR_K 1 "Fehlerspeichereintrag" 0 "kein_Fehlerspeichereintrag" ;
VAL_ 1367 EKD_Memory_K 1 "Fehlerspeichereintrag" 0 "kein_Fehlerspeichereintrag" ;
VAL_ 1367 EKD_Dachmodul_K 1 "Fehlerspeichereintrag" 0 "kein_Fehlerspeichereintrag" ;
VAL_ 1367 EKD_Zentralelektrik_II_K 1 "Fehlerspeichereintrag" 0 "kein_Fehlerspeichereintrag" ;
VAL_ 1367 EKD_RDK_K 1 "Fehlerspeichereintrag" 0 "kein_Fehlerspeichereintrag" ;
VAL_ 1367 EKD_SMLS_K 1 "Fehlerspeichereintrag" 0 "kein_Fehlerspeichereintrag" ;
VAL_ 1367 EKD_Gateway_K 1 "Fehlerspeichereintrag" 0 "kein_Fehlerspeichereintrag" ;
VAL_ 1367 EKD_Clima_K 1 "Fehlerspeichereintrag" 0 "kein_Fehlerspeichereintrag" ;
VAL_ 1367 EKD_APS_K 1 "Fehlerspeichereintrag" 0 "kein_Fehlerspeichereintrag" ;
VAL_ 1367 EKD_PTC_Heizung_K 1 "Fehlerspeichereintrag" 0 "kein_Fehlerspeichereintrag" ;
VAL_ 1367 EKD_Standhzg_K 1 "Fehlerspeichereintrag" 0 "kein_Fehlerspeichereintrag" ;
VAL_ 1367 EKD_VSG_K 1 "Fehlerspeichereintrag" 0 "kein_Fehlerspeichereintrag" ;
VAL_ 1367 EKD_RSE_I 1 "Fehlerspeichereintrag" 0 "kein_Fehlerspeichereintrag" ;
VAL_ 1367 EKD_Wischer_K 1 "Fehlerspeichereintrag" 0 "kein_Fehlerspeichereintrag" ;
VAL_ 1367 EKD_MDI_I 1 "Fehlerspeichereintrag" 0 "kein_Fehlerspeichereintrag" ;
VAL_ 1367 EKD_AAG_K 1 "Fehlerspeichereintrag" 0 "kein_Fehlerspeichereintrag" ;
VAL_ 1367 EKD_Mem_BF_K 1 "Fehlerspeichereintrag" 0 "kein_Fehlerspeichereintrag" ;
VAL_ 1367 EKD_Easy_Entry_VF 1 "Fehlerspeichereintrag" 0 "kein_Fehlerspeichereintrag" ;
VAL_ 1367 EKD_Easy_Entry_VB 1 "Fehlerspeichereintrag" 0 "kein_Fehlerspeichereintrag" ;
VAL_ 1367 EKD_Heckdeckel_K 1 "Fehlerspeichereintrag" 0 "kein_Fehlerspeichereintrag" ;
VAL_ 1367 EKD_Rearview_I 1 "Fehlerspeichereintrag" 0 "kein_Fehlerspeichereintrag" ;
VAL_ 1367 EKD_Sonderfahrzeug_SG_K 1 "Fehlerspeichereintrag" 0 "kein_Fehlerspeichereintrag" ;
VAL_ 1367 EKD_Tastenmodul_I 1 "Fehlerspeichereintrag" 0 "kein_Fehlerspeichereintrag" ;
VAL_ 1367 EKD_Kompass_I 1 "Fehlerspeichereintrag" 0 "kein_Fehlerspeichereintrag" ;
VAL_ 1367 EKD_WFS_K 1 "Fehlerspeichereintrag" 0 "kein_Fehlerspeichereintrag" ;
VAL_ 1367 EKD_GSM_Pager_I 1 "Fehlerspeichereintrag" 0 "kein_Fehlerspeichereintrag" ;
VAL_ 1367 EKD_DSP_I 1 "Fehlerspeichereintrag" 0 "kein_Fehlerspeichereintrag" ;
VAL_ 1367 EKD_DAB_I 1 "Fehlerspeichereintrag" 0 "kein_Fehlerspeichereintrag" ;
VAL_ 1367 EKD_Telematik_I 1 "Fehlerspeichereintrag" 0 "kein_Fehlerspeichereintrag" ;
VAL_ 1367 EKD_Navigation_I 1 "Fehlerspeichereintrag" 0 "kein_Fehlerspeichereintrag" ;
VAL_ 1367 EKD_TV_Tuner_I 1 "Fehlerspeichereintrag" 0 "kein_Fehlerspeichereintrag" ;
VAL_ 1367 EKD_Neigungsmodul 1 "Fehlerspeichereintrag" 0 "kein_Fehlerspeichereintrag" ;
VAL_ 1367 EKD_Radio_I 1 "Fehlerspeichereintrag" 0 "kein_Fehlerspeichereintrag" ;
VAL_ 1367 EKD_Telefon_I 1 "Fehlerspeichereintrag" 0 "kein_Fehlerspeichereintrag" ;
VAL_ 1569 KO1_Tankstop 1 "Tankstop_erkannt" ;
VAL_ 1569 KO1_Tankwarnlampe 1 "Lampe_ein" 0 "Lampe_aus" ;
VAL_ 1569 KO1_Handbremse 1 "angezogen" 0 "nicht_angezogen" ;
VAL_ 1569 KO1_Klemme_L 0 "Lampe_aus" 1 "Lampe_ein" ;
VAL_ 1569 KO1_Standzeit_Fehler 1 "Kl_30_war_weg" 0 "Standzeit_iO" ;
VAL_ 1569 KO1_Tankinhalt 127 "Fehler" ;
VAL_ 1569 KO1_Tankwarnung 0 "iO" 1 "Tankwarnung" ;
VAL_ 1569 KO1_WFS_Schluessel 0 "ungueltig" ;
VAL_ 1569 KO1_KD_Fehler_WFS 1 "Fehlerspeichereintrag" 0 "kein_Fehlerspeichereintrag" ;
VAL_ 1569 KO1_Fernlicht 1 "Kl56a_ein" 0 "aus" ;
VAL_ 1569 KO1_Freigabe_Zuheizer 0 "Zuheizer_EIN" 1 "Zuheizer_AUS" ;
VAL_ 1569 KO1_Bel_Displ 127 "kein_Ersatzwert" ;
VAL_ 1569 KO1_Sta_Displ 1 "Kl_58d_n_iO" 0 "Kl_58d_iO" ;
VAL_ 1569 KO1_Lichtsensor 254 "INIT" 255 "Fehler" ;
VAL_ 1479 KOM_KD_Fehler 1 "Fehlerspeichereintrag" 0 "kein_Fehlerspeichereintrag" ;
